VERSION ""

NS_ :

BS_:

BU_: Skylark_EV

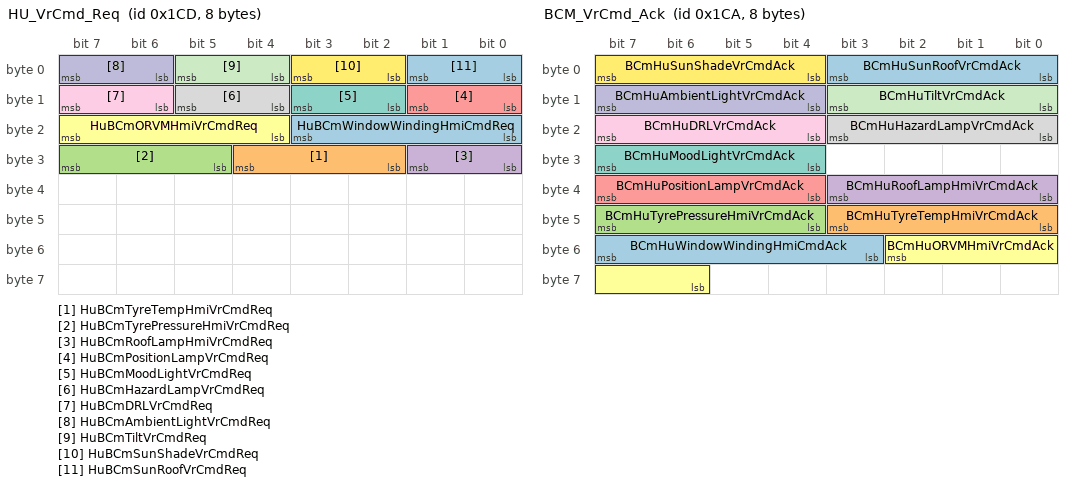
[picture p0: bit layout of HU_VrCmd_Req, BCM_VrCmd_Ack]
BO_ 461 HU_VrCmd_Req: 8 Skylark_EV
 SG_ HuBCmWindowWindingHmiCmdReq : 19|4@0+ (1,0) [0|15] "" Vector__XXX
 SG_ HuBCmTyreTempHmiVrCmdReq : 28|3@0+ (1,0) [0|7] "" Vector__XXX
 SG_ HuBCmTyrePressureHmiVrCmdReq : 31|3@0+ (1,0) [0|7] "" Vector__XXX
 SG_ HuBCmRoofLampHmiVrCmdReq : 25|2@0+ (1,0) [0|3] "" Vector__XXX
 SG_ HuBCmPositionLampVrCmdReq : 9|2@0+ (1,0) [0|3] "" Vector__XXX
 SG_ HuBCmORVMHmiVrCmdReq : 23|4@0+ (1,0) [0|15] "" Vector__XXX
 SG_ HuBCmMoodLightVrCmdReq : 11|2@0+ (1,0) [0|3] "" Vector__XXX
 SG_ HuBCmHazardLampVrCmdReq : 13|2@0+ (1,0) [0|3] "" Vector__XXX
 SG_ HuBCmDRLVrCmdReq : 15|2@0+ (1,0) [0|3] "" Vector__XXX
 SG_ HuBCmAmbientLightVrCmdReq : 7|2@0+ (1,0) [0|3] "" Vector__XXX
 SG_ HuBCmTiltVrCmdReq : 5|2@0+ (1,0) [0|3] "" Vector__XXX
 SG_ HuBCmSunShadeVrCmdReq : 3|2@0+ (1,0) [0|3] "" Vector__XXX
 SG_ HuBCmSunRoofVrCmdReq : 1|2@0+ (1,0) [0|3] "" Vector__XXX

BO_ 489 BCM_VrCmd_Support: 8 Vector__XXX
 SG_ BCmHuWindowWindingHmiCmdSupport : 23|1@0+ (1,0) [0|1] ""  Skylark_EV
 SG_ BCmHuTyreTempVrCmdSupport : 8|1@0+ (1,0) [0|1] ""  Skylark_EV
 SG_ BCmHuTyreTempHmiCmdSupport : 9|1@0+ (1,0) [0|1] ""  Skylark_EV
 SG_ BCmHuTyrePressureVrCmdSupport : 10|1@0+ (1,0) [0|1] ""  Skylark_EV
 SG_ BCmHuTyrePressureHmiCmdSupport : 11|1@0+ (1,0) [0|1] ""  Skylark_EV
 SG_ BCmHuSunroofTiltVrCmdSupport : 12|1@0+ (1,0) [0|1] ""  Skylark_EV
 SG_ BCmHuRoofLampVrCmdSupport : 13|1@0+ (1,0) [0|1] ""  Skylark_EV
 SG_ BCmHuRoofLampHmiCmdSupport : 14|1@0+ (1,0) [0|1] ""  Skylark_EV
 SG_ BCmHuPositionLampVrCmdSupport : 15|1@0+ (1,0) [0|1] ""  Skylark_EV
 SG_ BCmHuORVMVrCmdSupport : 2|1@0+ (1,0) [0|1] ""  Skylark_EV
 SG_ BCmHuORVMHmiCmdSupport : 3|1@0+ (1,0) [0|1] ""  Skylark_EV
 SG_ BCmHuMoodLightVrCmdSupport : 4|1@0+ (1,0) [0|1] ""  Skylark_EV
 SG_ BCmHuHazardLampVrCmdSupport : 5|1@0+ (1,0) [0|1] ""  Skylark_EV
 SG_ BCmHuDRLVrCmdSupport : 6|1@0+ (1,0) [0|1] ""  Skylark_EV
 SG_ BCmHuAmbientLightVrCmdSupport : 7|1@0+ (1,0) [0|1] ""  Skylark_EV
 SG_ BCmHuSunShadeVrCmdSupport : 1|1@0+ (1,0) [0|1] ""  Skylark_EV
 SG_ BCmHuSunRoofVrCmdSupport : 0|1@0+ (1,0) [0|1] ""  Skylark_EV

BO_ 458 BCM_VrCmd_Ack: 8 Vector__XXX
 SG_ BCmHuWindowWindingHmiCmdAck : 55|5@0+ (1,0) [0|31] ""  Skylark_EV
 SG_ BCmHuTyreTempHmiVrCmdAck : 43|4@0+ (1,0) [0|15] ""  Skylark_EV
 SG_ BCmHuTyrePressureHmiVrCmdAck : 47|4@0+ (1,0) [0|15] ""  Skylark_EV
 SG_ BCmHuRoofLampHmiVrCmdAck : 35|4@0+ (1,0) [0|15] ""  Skylark_EV
 SG_ BCmHuPositionLampVrCmdAck : 39|4@0+ (1,0) [0|15] ""  Skylark_EV
 SG_ BCmHuORVMHmiVrCmdAck : 50|5@0+ (1,0) [0|31] ""  Skylark_EV
 SG_ BCmHuMoodLightVrCmdAck : 31|4@0+ (1,0) [0|15] ""  Skylark_EV
 SG_ BCmHuHazardLampVrCmdAck : 19|4@0+ (1,0) [0|15] ""  Skylark_EV
 SG_ BCmHuDRLVrCmdAck : 23|4@0+ (1,0) [0|15] ""  Skylark_EV
 SG_ BCmHuAmbientLightVrCmdAck : 15|4@0+ (1,0) [0|15] ""  Skylark_EV
 SG_ BCmHuTiltVrCmdAck : 11|4@0+ (1,0) [0|15] ""  Skylark_EV
 SG_ BCmHuSunShadeVrCmdAck : 7|4@0+ (1,0) [0|15] ""  Skylark_EV
 SG_ BCmHuSunRoofVrCmdAck : 3|4@0+ (1,0) [0|15] ""  Skylark_EV

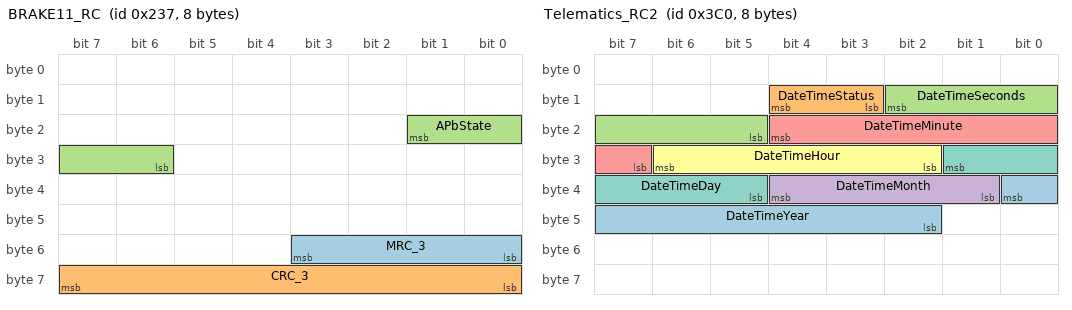
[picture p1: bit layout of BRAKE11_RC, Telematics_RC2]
BO_ 567 BRAKE11_RC: 8 Vector__XXX
 SG_ MRC_3 : 51|4@0+ (1,0) [0|15] ""  Skylark_EV
 SG_ CRC_3 : 63|8@0+ (1,0) [0|255] ""  Skylark_EV
 SG_ APbState : 17|4@0+ (1,0) [0|15] ""  Skylark_EV

BO_ 960 Telematics_RC2: 8 Skylark_EV
 SG_ DateTimeYear : 32|7@0+ (1,0) [0|99] "" Vector__XXX
 SG_ DateTimeStatus : 12|2@0+ (1,0) [0|3] "" Vector__XXX
 SG_ DateTimeSeconds : 10|6@0+ (1,0) [0|59] "" Vector__XXX
 SG_ DateTimeMonth : 36|4@0+ (1,0) [1|12] "" Vector__XXX
 SG_ DateTimeMinute : 20|6@0+ (1,0) [0|59] "" Vector__XXX
 SG_ DateTimeHour : 30|5@0+ (1,0) [0|23] "" Vector__XXX
 SG_ DateTimeDay : 25|5@0+ (1,0) [1|31] "" Vector__XXX

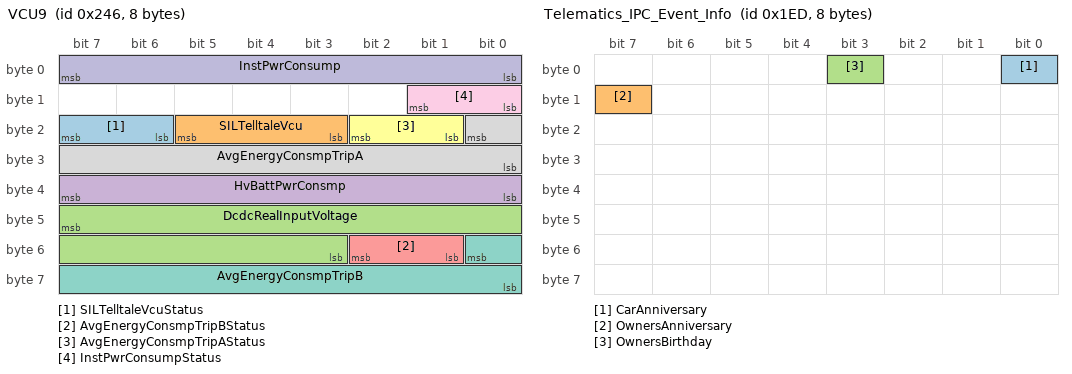
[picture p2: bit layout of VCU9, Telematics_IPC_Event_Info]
BO_ 582 VCU9: 8 Vector__XXX
 SG_ SILTelltaleVcuStatus : 23|2@0+ (1,0) [0|3] ""  Skylark_EV
 SG_ SILTelltaleVcu : 21|3@0+ (1,0) [0|7] ""  Skylark_EV
 SG_ DcdcRealInputVoltage : 47|13@0+ (0.1,0) [0|819.1] "V"  Skylark_EV
 SG_ HvBattPwrConsmp : 39|8@0+ (1,0) [0|250] "KwHr"  Skylark_EV
 SG_ AvgEnergyConsmpTripBStatus : 50|2@0+ (1,0) [0|3] ""  Skylark_EV
 SG_ AvgEnergyConsmpTripAStatus : 18|2@0+ (1,0) [0|3] ""  Skylark_EV
 SG_ AvgEnergyConsmpTripB : 48|9@0+ (1,0) [0|511] "kwH/Km"  Skylark_EV
 SG_ AvgEnergyConsmpTripA : 16|9@0+ (1,0) [0|511] "kwH/Km"  Skylark_EV
 SG_ InstPwrConsumpStatus : 9|2@0+ (1,0) [0|3] ""  Skylark_EV
 SG_ InstPwrConsump : 7|8@0+ (1,-100) [-100|100] "%"  Skylark_EV

BO_ 719 CCM_RC2: 8 Vector__XXX
 SG_ ComfortState : 0|1@0+ (1,0) [0|1] ""  Skylark_EV
 SG_ ComfortStateStatus : 2|2@0+ (1,0) [0|3] ""  Skylark_EV

BO_ 493 Telematics_IPC_Event_Info: 8 Skylark_EV
 SG_ CarAnniversary : 0|1@0+ (1,0) [0|1] "" Vector__XXX
 SG_ OwnersAnniversary : 15|1@0+ (1,0) [0|1] "" Vector__XXX
 SG_ OwnersBirthday : 3|1@0+ (1,0) [0|1] "" Vector__XXX

BO_ 581 VCU8_RC: 8 Vector__XXX
 SG_ HvChargeTypeStatus_VCAN : 37|2@0+ (1,0) [0|3] ""  Skylark_EV
 SG_ HvChargeType_VCAN : 35|2@0+ (1,0) [0|3] ""  Skylark_EV
 SG_ HvChargingStateStatus_VCAN : 33|2@0+ (1,0) [0|3] ""  Skylark_EV
 SG_ HvChargingState_VCAN : 26|3@0+ (1,0) [0|7] ""  Skylark_EV
 SG_ TimetoChargeHVMintsStatus_VCAN : 17|2@0+ (1,0) [0|3] ""  Skylark_EV
 SG_ TimetoChargeHVMints_VCAN : 23|6@0+ (1,0) [0|59] "Minutes"  Skylark_EV
 SG_ TimetoChargeHVHoursStatus_VCAN : 10|2@0+ (1,0) [0|3] ""  Skylark_EV
 SG_ TimetoChargeHVHours_VCAN : 15|5@0+ (1,0) [0|23] "Hours"  Skylark_EV
 SG_ CoolingPwrFdbkVal : 63|7@0+ (1,0) [0|100] "%"  Skylark_EV
 SG_ HeatingPwrFdbkVal : 55|7@0+ (1,0) [0|100] "%"  Skylark_EV
 SG_ CabinCoolingSolValveStateStatus : 29|2@0+ (1,0) [0|3] ""  Skylark_EV
 SG_ CabinCoolingSolValveState : 31|2@0+ (1,0) [0|3] ""  Skylark_EV
 SG_ LowHVBatteryChargeStatus_VCAN : 7|2@0+ (1,0) [0|3] ""  Skylark_EV
 SG_ LowHVBatteryCharge_VCAN : 5|2@0+ (1,0) [0|3] ""  Skylark_EV
 SG_ LowLVBatteryChargeStatus_VCAN : 3|2@0+ (1,0) [0|3] ""  Skylark_EV
 SG_ LowLVBatteryCharge_VCAN : 1|2@0+ (1,0) [0|3] ""  Skylark_EV
 SG_ HvAmpHrStatus : 39|2@0+ (1,0) [0|3] ""  Skylark_EV
 SG_ HvAmpHr : 47|8@0+ (0.5,0) [0|125] ""  Skylark_EV

BO_ 1330 CCM_Debug_Output2: 8 Vector__XXX
 SG_ SolarLoad : 7|8@0+ (5,0) [0|1200] "W/M^2"  Skylark_EV

BO_ 1329 CCM_Debug_Output1: 8 Vector__XXX
 SG_ SolarLoad : 63|8@0+ (5,0) [0|1200] "W/M^2"  Skylark_EV

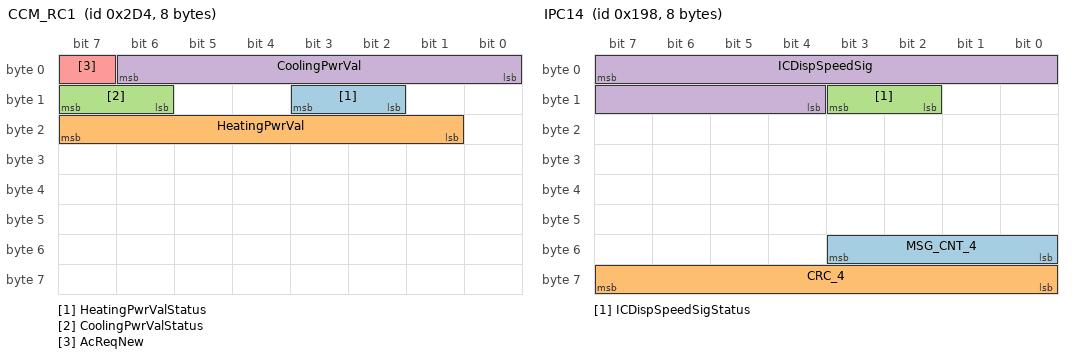
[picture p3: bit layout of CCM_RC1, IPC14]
BO_ 724 CCM_RC1: 8 Vector__XXX
 SG_ HeatingPwrValStatus : 11|2@0+ (1,0) [0|3] ""  Skylark_EV
 SG_ HeatingPwrVal : 23|7@0+ (1,0) [0|100] "%"  Skylark_EV
 SG_ CoolingPwrValStatus : 15|2@0+ (1,0) [0|3] ""  Skylark_EV
 SG_ CoolingPwrVal : 6|7@0+ (1,0) [0|100] "%"  Skylark_EV
 SG_ AcReqNew : 7|1@0+ (1,0) [0|1] ""  Skylark_EV

BO_ 408 IPC14: 8 Vector__XXX
 SG_ MSG_CNT_4 : 51|4@0+ (1,0) [0|15] ""  Skylark_EV
 SG_ CRC_4 : 63|8@0+ (1,0) [0|255] ""  Skylark_EV
 SG_ ICDispSpeedSigStatus : 11|2@0+ (1,0) [0|3] ""  Skylark_EV
 SG_ ICDispSpeedSig : 7|12@0+ (0.03125,0) [0|127.96875] "m/s"  Skylark_EV

BO_ 738 BCM_RC5: 8 Vector__XXX
 SG_ TurnInputSwStateInfoStatus : 62|2@0+ (1,0) [0|3] ""  Skylark_EV
 SG_ TurnInputSwStateInfo : 48|2@0+ (1,0) [0|3] ""  Skylark_EV
 SG_ RemoteUsecaseStateStatus : 51|2@0+ (1,0) [0|3] ""  Skylark_EV
 SG_ RemoteUsecaseState : 53|2@0+ (1,0) [0|3] ""  Skylark_EV
 SG_ HornStateStatus : 14|2@0+ (1,0) [0|3] ""  Skylark_EV
 SG_ HornState : 15|1@0+ (1,0) [0|1] ""  Skylark_EV
 SG_ ForcePanicStatus : 12|1@0+ (1,0) [0|1] ""  Skylark_EV
 SG_ ApprochLampStateStatus : 18|2@0+ (1,0) [0|3] ""  Skylark_EV
 SG_ ApprochLampState : 16|1@0+ (1,0) [0|1] ""  Skylark_EV
 SG_ LowBeamTellTaleStatus : 11|2@0+ (1,0) [0|3] ""  Skylark_EV
 SG_ LowBeamTellTale : 7|1@0+ (1,0) [0|1] ""  Skylark_EV
 SG_ IntrusionInfoStateStatus : 9|2@0+ (1,0) [0|3] ""  Skylark_EV
 SG_ IntrusionInfoState : 6|1@0+ (1,0) [0|1] ""  Skylark_EV
 SG_ HazardLampState : 3|1@0+ (1,0) [0|1] ""  Skylark_EV
 SG_ HazardLampStateStatus : 5|2@0+ (1,0) [0|3] ""  Skylark_EV
 SG_ VehicleSecured : 0|1@0+ (1,0) [0|1] ""  Skylark_EV
 SG_ VehicleSecuredStatus : 2|2@0+ (1,0) [0|3] ""  Skylark_EV

BO_ 495 TelematicsEventMsg_RC4: 8 Skylark_EV
 SG_ RemoteHornCmdStatus : 44|2@0+ (1,0) [0|3] "" Vector__XXX
 SG_ RemoteHornCmd : 45|1@0+ (1,0) [0|1] "" Vector__XXX
 SG_ RemoteApprochLmpCmdStatus : 41|2@0+ (1,0) [0|3] "" Vector__XXX
 SG_ RemoteApprochLmpCmd : 42|1@0+ (1,0) [0|1] "" Vector__XXX
 SG_ RemoteValetCmdStatus : 47|2@0+ (1,0) [0|3] "" Vector__XXX
 SG_ RemoteValetCmd : 33|1@0+ (1,0) [0|1] "" Vector__XXX
 SG_ RemoteAcTempSetStatus : 30|2@0+ (1,0) [0|3] "" Vector__XXX
 SG_ RemoteAcTempSet : 28|5@0+ (0.5,0) [0|31] "" Vector__XXX
 SG_ RemoteAcCmd : 31|1@0+ (1,0) [0|1] "" Vector__XXX
 SG_ RemoteAcCmdStatus : 39|2@0+ (1,0) [0|3] "" Vector__XXX
 SG_ RemoteImmoReqStatus : 37|2@0+ (1,0) [0|3] "" Vector__XXX
 SG_ RemoteImmoReq : 35|2@0+ (1,0) [0|3] "" Vector__XXX
 SG_ TowInfoStatus : 20|2@0+ (1,0) [0|3] "" Vector__XXX
 SG_ TowInfo : 21|1@0+ (1,0) [0|1] "" Vector__XXX
 SG_ ParkingCollisionInfoStatus : 23|2@0+ (1,0) [0|3] "" Vector__XXX
 SG_ ParkingCollisionInfo : 8|1@0+ (1,0) [0|1] "" Vector__XXX
 SG_ RemotePositionCmdStatus : 7|2@0+ (1,0) [0|3] "" Vector__XXX
 SG_ RemotePositionCmd : 15|1@0+ (1,0) [0|1] "" Vector__XXX
 SG_ RemoteHazardCmdStatus : 11|2@0+ (1,0) [0|3] "" Vector__XXX
 SG_ RemoteHazardCmd : 9|1@0+ (1,0) [0|1] "" Vector__XXX
 SG_ RemoteVehicleUnlockCmdStatus : 5|2@0+ (1,0) [0|3] "" Vector__XXX
 SG_ RemoteVehicleUnlockCmd : 3|1@0+ (1,0) [0|1] "" Vector__XXX
 SG_ RemoteVehicleLockCmdStatus : 2|2@0+ (1,0) [0|3] "" Vector__XXX
 SG_ RemoteVehicleLockCmd : 0|1@0+ (1,0) [0|1] "" Vector__XXX

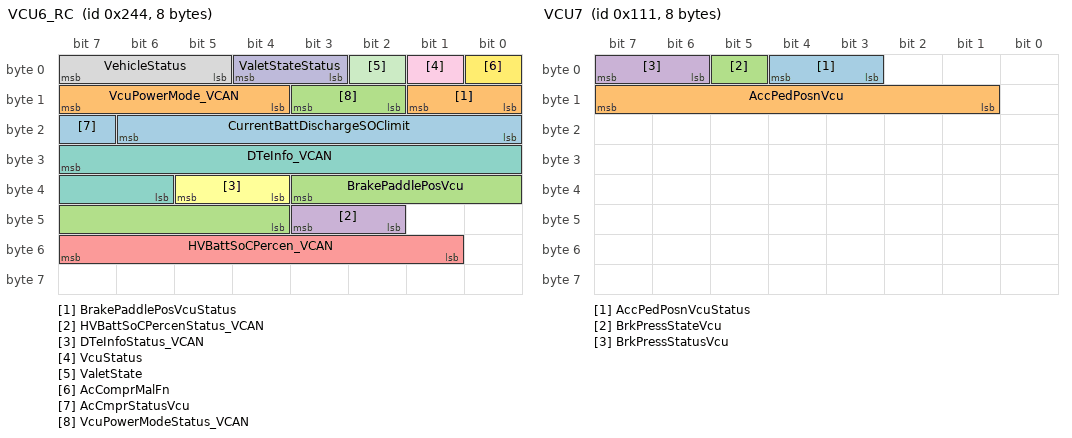
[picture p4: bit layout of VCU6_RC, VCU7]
BO_ 580 VCU6_RC: 8 Vector__XXX
 SG_ CurrentBattDischargeSOClimit : 22|7@0+ (1,0) [0|100] "%"  Skylark_EV
 SG_ BrakePaddlePosVcuStatus : 9|2@0+ (1,0) [0|3] ""  Skylark_EV
 SG_ BrakePaddlePosVcu : 35|8@0+ (0.5,0) [0|100] "%"  Skylark_EV
 SG_ HVBattSoCPercenStatus_VCAN : 43|2@0+ (1,0) [0|3] ""  Skylark_EV
 SG_ HVBattSoCPercen_VCAN : 55|7@0+ (1,0) [0|100] "%"  Skylark_EV
 SG_ DTeInfoStatus_VCAN : 37|2@0+ (1,0) [0|3] ""  Skylark_EV
 SG_ DTeInfo_VCAN : 31|10@0+ (1,0) [0|999] ""  Skylark_EV
 SG_ VehicleStatus : 7|3@0+ (1,0) [0|7] ""  Skylark_EV
 SG_ VcuStatus : 1|1@0+ (1,0) [0|1] ""  Skylark_EV
 SG_ ValetStateStatus : 4|2@0+ (1,0) [0|3] ""  Skylark_EV
 SG_ ValetState : 2|1@0+ (1,0) [0|1] ""  Skylark_EV
 SG_ AcComprMalFn : 0|1@0+ (1,0) [0|1] ""  Skylark_EV
 SG_ AcCmprStatusVcu : 23|1@0+ (1,0) [0|1] ""  Skylark_EV
 SG_ VcuPowerMode_VCAN : 15|4@0+ (1,0) [0|15] ""  Skylark_EV
 SG_ VcuPowerModeStatus_VCAN : 11|2@0+ (1,0) [0|3] ""  Skylark_EV

BO_ 579 VCU5: 8 Vector__XXX
 SG_ VcuHazardLampReqStatus : 50|2@0+ (1,0) [0|3] ""  Skylark_EV
 SG_ VcuHazardLampReq : 51|1@0+ (1,0) [0|1] ""  Skylark_EV
 SG_ VCuPresence : 0|1@0+ (1,0) [0|1] ""  Skylark_EV
 SG_ BrkVacPumpStatus : 40|1@0+ (1,0) [0|1] ""  Skylark_EV
 SG_ DriveMotorStatus : 53|1@0+ (1,0) [0|1] ""  Skylark_EV
 SG_ HvBattSoh : 52|1@0+ (1,0) [0|1] ""  Skylark_EV
 SG_ RegenAmpHr : 29|8@0+ (0.5,0) [0|125] ""  Skylark_EV
 SG_ HvBattPackVolStatus : 55|2@0+ (1,0) [0|3] ""  Skylark_EV
 SG_ HvBattPackVol : 37|13@0+ (0.1,0) [0|500] ""  Skylark_EV
 SG_ AvgEnergyConsmption : 48|9@0+ (1,0) [0|511] "kwH/Km"  Skylark_EV
 SG_ AvgEnergyConsmptionStatus : 17|2@0+ (1,0) [0|3] ""  Skylark_EV
 SG_ MotorHightempStatus : 19|2@0+ (1,0) [0|3] ""  Skylark_EV
 SG_ MotorHightemp : 31|2@0+ (1,0) [0|3] ""  Skylark_EV
 SG_ VcuGearSelectionChangeTxt : 21|2@0+ (1,0) [0|3] ""  Skylark_EV
 SG_ ImmoStatusVcu : 8|1@0+ (1,0) [0|1] ""  Skylark_EV
 SG_ ClntTempVcuStatus : 23|2@0+ (1,0) [0|3] ""  Skylark_EV
 SG_ ClntTempVcu : 15|7@0+ (1,-10) [-10|80] "deg"  Skylark_EV
 SG_ GearForDisplayVcu : 7|4@0+ (1,0) [0|15] ""  Skylark_EV
 SG_ GearForDisplayVcuStatus : 3|2@0+ (1,0) [0|3] ""  Skylark_EV

BO_ 273 VCU7: 8 Vector__XXX
 SG_ AccPedPosnVcuStatus : 4|2@0+ (1,0) [0|3] ""  Skylark_EV
 SG_ AccPedPosnVcu : 15|7@0+ (1,0) [0|100] "%"  Skylark_EV
 SG_ BrkPressStateVcu : 5|1@0+ (1,0) [0|1] ""  Skylark_EV
 SG_ BrkPressStatusVcu : 7|2@0+ (1,0) [0|3] ""  Skylark_EV

BO_ 192 SAS1: 5 Vector__XXX
 SG_ LWS_ANGLE : 0|16@1- (0.1,0) [-780|779.9] "degree"  Skylark_EV

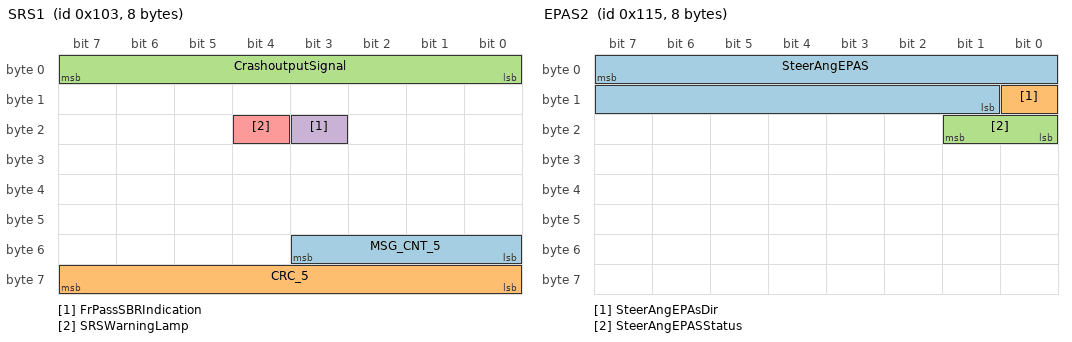
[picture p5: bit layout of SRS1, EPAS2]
BO_ 259 SRS1: 8 Vector__XXX
 SG_ MSG_CNT_5 : 51|4@0+ (1,0) [0|15] ""  Skylark_EV
 SG_ CRC_5 : 63|8@0+ (1,0) [0|255] ""  Skylark_EV
 SG_ CrashoutputSignal : 7|8@0+ (1,0) [0|255] ""  Skylark_EV
 SG_ FrPassSBRIndication : 19|1@0+ (1,0) [0|1] ""  Skylark_EV
 SG_ SRSWarningLamp : 20|1@0+ (1,0) [0|1] ""  Skylark_EV

BO_ 277 EPAS2: 8 Vector__XXX
 SG_ SteerAngEPAS : 7|15@0+ (0.04375,0) [0|1433.55625] " deg"  Skylark_EV
 SG_ SteerAngEPAsDir : 8|1@0+ (1,0) [0|1] ""  Skylark_EV
 SG_ SteerAngEPASStatus : 17|2@0+ (1,0) [0|3] ""  Skylark_EV

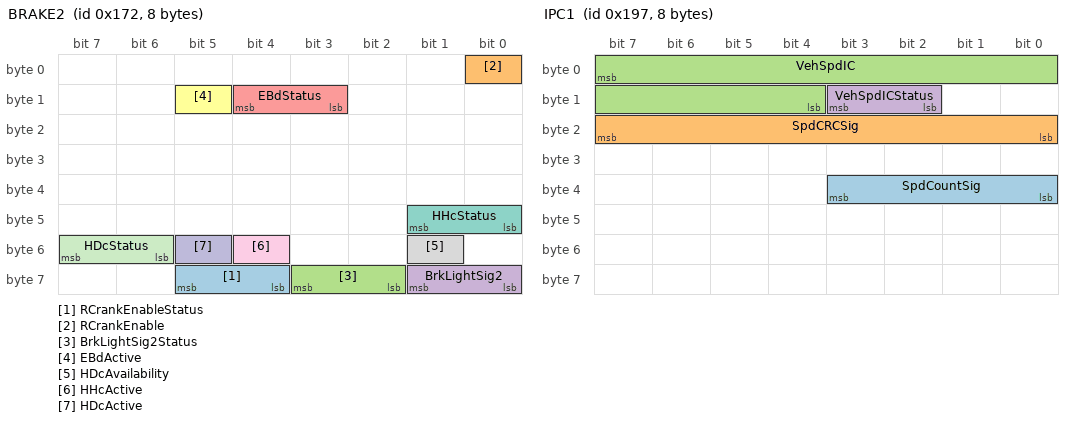
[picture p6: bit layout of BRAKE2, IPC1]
BO_ 370 BRAKE2: 8 Vector__XXX
 SG_ RCrankEnableStatus : 61|2@0+ (1,0) [0|3] ""  Skylark_EV
 SG_ RCrankEnable : 0|1@0+ (1,0) [0|1] ""  Skylark_EV
 SG_ BrkLightSig2Status : 59|2@0+ (1,0) [0|3] ""  Skylark_EV
 SG_ BrkLightSig2 : 57|2@0+ (1,0) [0|3] ""  Skylark_EV
 SG_ EBdStatus : 12|2@0+ (1,0) [0|3] ""  Skylark_EV
 SG_ EBdActive : 13|1@0+ (1,0) [0|1] ""  Skylark_EV
 SG_ HHcStatus : 41|2@0+ (1,0) [0|3] ""  Skylark_EV
 SG_ HDcAvailability : 49|1@0+ (1,0) [0|1] ""  Skylark_EV
 SG_ HHcActive : 52|1@0+ (1,0) [0|1] ""  Skylark_EV
 SG_ HDcActive : 53|1@0+ (1,0) [0|1] ""  Skylark_EV
 SG_ HDcStatus : 55|2@0+ (1,0) [0|3] ""  Skylark_EV

BO_ 374 BRAKE5: 8 Vector__XXX
 SG_ DrvModeIndctnESP2Status : 28|2@0+ (1,0) [0|3] ""  Skylark_EV
 SG_ DrvModeIndctnESP2 : 31|3@0+ (1,0) [0|7] ""  Skylark_EV

BO_ 376 BRAKE9: 8 Vector__XXX
 SG_ AX1 : 7|16@0+ (0.0001,-3.2768) [-3.2768|3.2767] "g"  Skylark_EV
 SG_ AY1 : 23|16@0+ (0.0001,-3.2768) [-3.2768|3.2767] "g"  Skylark_EV

BO_ 407 IPC1: 8 Vector__XXX
 SG_ SpdCountSig : 35|4@0+ (1,0) [0|15] ""  Skylark_EV
 SG_ SpdCRCSig : 23|8@0+ (1,0) [0|255] ""  Skylark_EV
 SG_ VehSpdIC : 7|12@0+ (0.03125,0) [0|127.96875] "m/s"  Skylark_EV
 SG_ VehSpdICStatus : 11|2@0+ (1,0) [0|3] ""  Skylark_EV

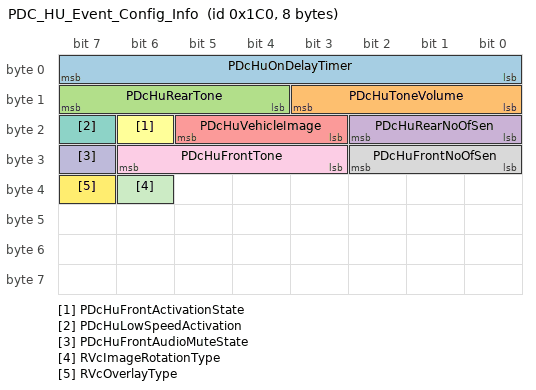
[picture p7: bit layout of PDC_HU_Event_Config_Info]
BO_ 448 PDC_HU_Event_Config_Info: 8 Vector__XXX
 SG_ PDcHuOnDelayTimer : 7|8@0+ (1,0) [0|255] "sec"  Skylark_EV
 SG_ PDcHuToneVolume : 11|4@0+ (1,0) [0|15] ""  Skylark_EV
 SG_ PDcHuRearTone : 15|4@0+ (1,0) [0|15] ""  Skylark_EV
 SG_ PDcHuRearNoOfSen : 18|3@0+ (1,0) [0|7] ""  Skylark_EV
 SG_ PDcHuVehicleImage : 21|3@0+ (1,0) [0|7] ""  Skylark_EV
 SG_ PDcHuFrontActivationState : 22|1@0+ (1,0) [0|1] ""  Skylark_EV
 SG_ PDcHuLowSpeedActivation : 23|1@0+ (1,0) [0|1] ""  Skylark_EV
 SG_ PDcHuFrontNoOfSen : 26|3@0+ (1,0) [0|7] ""  Skylark_EV
 SG_ PDcHuFrontTone : 30|4@0+ (1,0) [0|15] ""  Skylark_EV
 SG_ PDcHuFrontAudioMuteState : 31|1@0+ (1,0) [0|1] ""  Skylark_EV
 SG_ RVcImageRotationType : 38|1@0+ (1,0) [0|1] ""  Skylark_EV
 SG_ RVcOverlayType : 39|1@0+ (1,0) [0|1] ""  Skylark_EV

BO_ 451 IPC_VCIM_Event_OdoFullRange_RC: 8 Vector__XXX
 SG_ OdoICFullSig : 7|32@0+ (1,0) [0|999999000] "m"  Skylark_EV

CM_ SG_ 461 HuBCmWindowWindingHmiCmdReq "Window Winding voice command request from HU to BCM";
CM_ SG_ 461 HuBCmTyreTempHmiVrCmdReq "Tyre Temperature HMI or voice command request from HU to BCM";
CM_ SG_ 461 HuBCmTyrePressureHmiVrCmdReq "Tyre Pressure HMI or voice command request from HU to BCM";
CM_ SG_ 461 HuBCmRoofLampHmiVrCmdReq "Roof lamp HMI or Voice command request from HU to BCM";
CM_ SG_ 461 HuBCmPositionLampVrCmdReq "Position lamp voice command request from HU to BCM";
CM_ SG_ 461 HuBCmORVMHmiVrCmdReq "ORVM HMI or Voice command request from HU to BCM";
CM_ SG_ 461 HuBCmMoodLightVrCmdReq "Mood light voice command request from HU to BCM";
CM_ SG_ 461 HuBCmHazardLampVrCmdReq "Hazard lamp voice command request from HU to BCM";
CM_ SG_ 461 HuBCmDRLVrCmdReq "DRL voice command request from HU to BCM";
CM_ SG_ 461 HuBCmAmbientLightVrCmdReq "Ambient light voice command request from HU to BCM";
CM_ SG_ 461 HuBCmTiltVrCmdReq "Sunroof Tilt voice command command request from HU to BCM";
CM_ SG_ 461 HuBCmSunShadeVrCmdReq "Sunshade voice command request from HU to BCM";
CM_ SG_ 461 HuBCmSunRoofVrCmdReq "Sunroof voice command command request from HU to BCM";
CM_ SG_ 489 BCmHuWindowWindingHmiCmdSupport "Window Winding HMI support from BCM to HU";
CM_ SG_ 489 BCmHuTyreTempVrCmdSupport "Tyre Temparature Voice support from BCM to HU";
CM_ SG_ 489 BCmHuTyreTempHmiCmdSupport "Tyre Temparature HMI support from BCM to HU";
CM_ SG_ 489 BCmHuTyrePressureVrCmdSupport "Tyre Pressure Voice support from BCM to HU";
CM_ SG_ 489 BCmHuTyrePressureHmiCmdSupport "Tyre Pressure HMI support from BCM to HU";
CM_ SG_ 489 BCmHuSunroofTiltVrCmdSupport "Sunroof Tilt voice support from BCM to HU";
CM_ SG_ 489 BCmHuRoofLampVrCmdSupport "Roof Lamp Voice support from BCM to HU";
CM_ SG_ 489 BCmHuRoofLampHmiCmdSupport "Roof Lamp HMI support from BCM to HU";
CM_ SG_ 489 BCmHuPositionLampVrCmdSupport "Position lamp voice support from BCM to HU";
CM_ SG_ 489 BCmHuORVMVrCmdSupport "ORVM Voice support from BCM to HU";
CM_ SG_ 489 BCmHuORVMHmiCmdSupport "ORVM HMI support from BCM to HU";
CM_ SG_ 489 BCmHuMoodLightVrCmdSupport "Mood Light voice support from BCM to HU";
CM_ SG_ 489 BCmHuHazardLampVrCmdSupport "Hazard Lamp voice support from BCM to HU";
CM_ SG_ 489 BCmHuDRLVrCmdSupport "DRL voice support from BCM to HU";
CM_ SG_ 489 BCmHuAmbientLightVrCmdSupport "Ambient Light voice support from BCM to HU";
CM_ SG_ 489 BCmHuSunShadeVrCmdSupport "Sunshade operation support from BCM to HU";
CM_ SG_ 489 BCmHuSunRoofVrCmdSupport "Sunroof operation support from BCM to HU";
CM_ SG_ 458 BCmHuWindowWindingHmiCmdAck "Window Winding state from BCM to HU















";
CM_ SG_ 458 BCmHuTyreTempHmiVrCmdAck "Tyre Temperature state from BCM to HU














";
CM_ SG_ 458 BCmHuTyrePressureHmiVrCmdAck "Tyre Pressure state from BCM to HU















";
CM_ SG_ 458 BCmHuRoofLampHmiVrCmdAck "Roof lamp state from BCM to HU

















";
CM_ SG_ 458 BCmHuPositionLampVrCmdAck "Position lamp state from BCM to HU";
CM_ SG_ 458 BCmHuORVMHmiVrCmdAck "ORVM state from BCM to HU
















";
CM_ SG_ 458 BCmHuMoodLightVrCmdAck "Mood Light state from BCM to HU";
CM_ SG_ 458 BCmHuHazardLampVrCmdAck "Hazard lamp state from BCM to HU";
CM_ SG_ 458 BCmHuDRLVrCmdAck "DRL state from BCM to HU";
CM_ SG_ 458 BCmHuAmbientLightVrCmdAck "Ambient Light state from BCM to HU";
CM_ SG_ 458 BCmHuTiltVrCmdAck "Sunroof Tilt state from BCM to HU";
CM_ SG_ 458 BCmHuSunShadeVrCmdAck "Sunshade state from BCM to HU";
CM_ SG_ 458 BCmHuSunRoofVrCmdAck "Sunroof state from BCM to HU";
CM_ SG_ 567 MRC_3 "Messgage counter for APbState signals";
CM_ SG_ 567 CRC_3 "CRC signal for APbState";
CM_ SG_ 567 APbState "status of APB system";
CM_ SG_ 960 DateTimeYear "Year Information";
CM_ SG_ 960 DateTimeStatus "Date Time Status Information";
CM_ SG_ 960 DateTimeSeconds "Seconds Information";
CM_ SG_ 960 DateTimeMonth "Month Information";
CM_ SG_ 960 DateTimeMinute "Minute Information";
CM_ SG_ 960 DateTimeHour "Hour Information";
CM_ SG_ 960 DateTimeDay "Day Information";
CM_ SG_ 582 SILTelltaleVcuStatus "status of Service Indicator Lamp telltale from VCU";
CM_ SG_ 582 SILTelltaleVcu "Service Indicator Lamp telltale from VCU";
CM_ SG_ 582 DcdcRealInputVoltage "DCDC_VCU_38E( signal name at PT side)
Voltage after the HV Battery Contactor";
CM_ SG_ 582 HvBattPwrConsmp "HV Battery Power Consumption";
CM_ SG_ 582 AvgEnergyConsmpTripBStatus "Average Energy Consumption for Trip B Status";
CM_ SG_ 582 AvgEnergyConsmpTripAStatus "Average Energy Consumption for Trip A Status";
CM_ SG_ 582 AvgEnergyConsmpTripB "Average Energy Consumption for Trip B";
CM_ SG_ 582 AvgEnergyConsmpTripA "Average Energy Consumption for Trip A";
CM_ SG_ 582 InstPwrConsumpStatus "Instantaneous Power Consumption Status";
CM_ SG_ 582 InstPwrConsump "Instantaneous Power Consumption";
CM_ SG_ 719 ComfortState "Set temperature reached information as published by FATC to Tcu";
CM_ SG_ 719 ComfortStateStatus "Status signal of Set temperature reached information as published by FATC to Tcu";
CM_ SG_ 493 CarAnniversary "Car Anniversary";
CM_ SG_ 493 OwnersAnniversary "Owenrs Marriage Anniversary";
CM_ SG_ 493 OwnersBirthday "It’s the car Owners Birthday";
CM_ SG_ 581 HvChargeTypeStatus_VCAN "HV Battery Charging Type Status";
CM_ SG_ 581 HvChargeType_VCAN "HV Battery Charging Type";
CM_ SG_ 581 HvChargingStateStatus_VCAN "HV Battery Charging Status";
CM_ SG_ 581 HvChargingState_VCAN "HV Battery Charging State";
CM_ SG_ 581 TimetoChargeHVMintsStatus_VCAN "Time to charge HV Battery Minutes Status";
CM_ SG_ 581 TimetoChargeHVMints_VCAN "Time to charge HV Battery Minutes";
CM_ SG_ 581 TimetoChargeHVHoursStatus_VCAN "Time to charge HV Battery Hours Status";
CM_ SG_ 581 TimetoChargeHVHours_VCAN "Time to charge HV Battery Hours";
CM_ SG_ 581 CoolingPwrFdbkVal "This signal is used to indicate the actual value of Cooling Power honored by VCU.";
CM_ SG_ 581 HeatingPwrFdbkVal "This signal is used to indicate the actual value of Heating Power honored by VCU.
";
CM_ SG_ 581 CabinCoolingSolValveStateStatus "Cabin Cooling Solenoid Valve Signal Status";
CM_ SG_ 581 CabinCoolingSolValveState "Cabin Cooling Solenoid Valve Signal";
CM_ SG_ 581 LowHVBatteryChargeStatus_VCAN "Low HV Battery Charge Status";
CM_ SG_ 581 LowHVBatteryCharge_VCAN "Low HV Battery Charge";
CM_ SG_ 581 LowLVBatteryChargeStatus_VCAN "Low LV Battery Charge Status";
CM_ SG_ 581 LowLVBatteryCharge_VCAN "Low LV Battery Charge";
CM_ SG_ 581 HvAmpHrStatus "HV Battery Charge Status";
CM_ SG_ 581 HvAmpHr "HV Battery Charge";
CM_ SG_ 1330 SolarLoad "This signal is used to provide the current value of  Solar Load";
CM_ SG_ 1329 SolarLoad "This signal is used to provide the current value of  Solar Load";
CM_ SG_ 724 HeatingPwrValStatus "Indicate the status of heating power required for cabin heating ";
CM_ SG_ 724 HeatingPwrVal "This signal is used to control the PTC Heater for cabin heating";
CM_ SG_ 724 CoolingPwrValStatus "Indicate the status of cooling power required for cabin Cooling ";
CM_ SG_ 724 CoolingPwrVal "This signal is used to control the Compressor rpm for cabin Cooling";
CM_ SG_ 724 AcReqNew "VCU to recive the signal from FATC to know the AC request by driver";
CM_ SG_ 408 MSG_CNT_4 "rolling counter for message 0x198";
CM_ SG_ 408 CRC_4 "Signal represents CRC of the message.";
CM_ SG_ 408 ICDispSpeedSigStatus "Signal represents Status of Display Vehicle Speed Signal";
CM_ SG_ 408 ICDispSpeedSig "Signal represents Display Vehicle Speed evaluated by Instrument Cluster
";
CM_ SG_ 738 TurnInputSwStateInfoStatus "BCM shall publish turn indicator input switch state  Status information on CAN";
CM_ SG_ 738 TurnInputSwStateInfo "BCM shall publish turn indictor input switch state information on CAN";
CM_ SG_ 738 RemoteUsecaseStateStatus "This signal gives status of RemoteUsecaseState signal.";
CM_ SG_ 738 RemoteUsecaseState "This signal is transmitted from BCM to TCM, PEPS, EMS, IPC & HU for informing ECUs about start working as normal Drive mode and ignore Remote Command recondition checks.";
CM_ SG_ 738 HornStateStatus "HornStateStatus Signal information";
CM_ SG_ 738 HornState "Horn Status Information ";
CM_ SG_ 738 ForcePanicStatus "Force Panic Request signal";
CM_ SG_ 738 ApprochLampStateStatus "Status signal for ApprochLamp status from BCM";
CM_ SG_ 738 ApprochLampState "ApprochLampstatus from BCM";
CM_ SG_ 738 LowBeamTellTaleStatus "Status of the Low Beam Telltale";
CM_ SG_ 738 LowBeamTellTale "IC to display the low beam tell-tale when the low beam lamp is active";
CM_ SG_ 738 IntrusionInfoStateStatus "Status of Perimetric alarm state from BCM";
CM_ SG_ 738 IntrusionInfoState "Perimetric alarm state from BCM";
CM_ SG_ 738 HazardLampState "Hazard lamp status from BCM";
CM_ SG_ 738 HazardLampStateStatus "Status of signal HazardLampState";
CM_ SG_ 738 VehicleSecured "Vehicle secured information";
CM_ SG_ 738 VehicleSecuredStatus "Status of Vehicle secured information";
CM_ SG_ 495 RemoteHornCmdStatus "Status of the HornStateCmd signal published by TCU";
CM_ SG_ 495 RemoteHornCmd "Horn State on/off request from TCU";
CM_ SG_ 495 RemoteApprochLmpCmdStatus "Status of the RemoteApprochCmd signal published by TCU";
CM_ SG_ 495 RemoteApprochLmpCmd "Approch lamp on/off request from TCU";
CM_ SG_ 495 RemoteValetCmdStatus "Status of the Valetcmd Status published by TCU";
CM_ SG_ 495 RemoteValetCmd "Command published by TCU to request FATC";
CM_ SG_ 495 RemoteAcTempSetStatus "Status of the TCuAcTemperatureSet singnal as published by TCU.";
CM_ SG_ 495 RemoteAcTempSet "Set temperature value from TCU to FATC for in-cabin climate control.";
CM_ SG_ 495 RemoteAcCmd "Command published by TCU to request FATC to turn On/Off the AC.";
CM_ SG_ 495 RemoteAcCmdStatus "Status of the TCuAcCmd signal published by TCU";
CM_ SG_ 495 RemoteImmoReqStatus "Status signal for Immobilize request from TCU to VCU";
CM_ SG_ 495 RemoteImmoReq "Immobilize request from TCU to VCU";
CM_ SG_ 495 TowInfoStatus "status signal for TCU sends the Tow away detection to BCM";
CM_ SG_ 495 TowInfo "TCU sends the Tow away detection to BCM ";
CM_ SG_ 495 ParkingCollisionInfoStatus "status signal for TCU sends the Park collision detection to BCM";
CM_ SG_ 495 ParkingCollisionInfo "TCU sends the Park collision detection to BCM ";
CM_ SG_ 495 RemotePositionCmdStatus "Status of the RemotePositionCmd signal published by BCM";
CM_ SG_ 495 RemotePositionCmd "Position lamp on/off request from TCU";
CM_ SG_ 495 RemoteHazardCmdStatus "Status of the RemoteHazardCmd signal published by TCU";
CM_ SG_ 495 RemoteHazardCmd "Hazard lamp on/off request from TCU";
CM_ SG_ 495 RemoteVehicleUnlockCmdStatus "Staus of signal for Command published by TCU to request BCM to unlock the vehicle";
CM_ SG_ 495 RemoteVehicleUnlockCmd "Command published by TCU to request BCM to unlock the vehicle";
CM_ SG_ 495 RemoteVehicleLockCmdStatus "Staus of signal for Command published by TCU to request BCM to lock the vehicle";
CM_ SG_ 495 RemoteVehicleLockCmd "Command published by TCU to request BCM to lock the vehicle";
CM_ SG_ 580 CurrentBattDischargeSOClimit "Indicates the requested discharge limit by user ";
CM_ SG_ 580 BrakePaddlePosVcuStatus "Brake paddle travel percentage status information shall be Transmissted  by VCU to Telematics ";
CM_ SG_ 580 BrakePaddlePosVcu "Brake paddle travel percentage shall be Transmissted  by VCU to Telematics ";
CM_ SG_ 580 HVBattSoCPercenStatus_VCAN "HV Battery SoC Percentage Status";
CM_ SG_ 580 HVBattSoCPercen_VCAN "HV Battery SoC Percentage";
CM_ SG_ 580 DTeInfoStatus_VCAN "Distance to Empty Information Status";
CM_ SG_ 580 DTeInfo_VCAN "Distance to Empty Information";
CM_ SG_ 580 VehicleStatus "Vehicle status display messages";
CM_ SG_ 580 VcuStatus "This function displays status of the VCU Malfunctioning
";
CM_ SG_ 580 ValetStateStatus "ValetStateStatus signlal published by VCU";
CM_ SG_ 580 ValetState "ValetState as Published by VCU";
CM_ SG_ 580 AcComprMalFn "This function displays status of the AC Compressor Malfunctioning";
CM_ SG_ 580 AcCmprStatusVcu "This signal is used to cycle the compressor and diagnostic";
CM_ SG_ 580 VcuPowerMode_VCAN "Indicates the VCU power mode";
CM_ SG_ 580 VcuPowerModeStatus_VCAN "This information is used to determine the plausibility status for VCU power mode message";
CM_ SG_ 579 VcuHazardLampReqStatus "Hazard lamp operation status from VCU to BCM";
CM_ SG_ 579 VcuHazardLampReq "Hazard lamp operation request from VCU to BCM";
CM_ SG_ 579 VCuPresence "ECU presence signal to the partner ECU";
CM_ SG_ 579 BrkVacPumpStatus "This function displays status of the Brake Vaccum Pump Malfunctioning";
CM_ SG_ 579 DriveMotorStatus "This function displays status of the Drive Motor Malfunctioning";
CM_ SG_ 579 HvBattSoh "HV Battery State of Health";
CM_ SG_ 579 RegenAmpHr "Regeneration Battery Charge";
CM_ SG_ 579 HvBattPackVolStatus "HV Battery Pack Voltage Status";
CM_ SG_ 579 HvBattPackVol "HV Battery Pack Voltage";
CM_ SG_ 579 AvgEnergyConsmption "Average Energy Consumption";
CM_ SG_ 579 AvgEnergyConsmptionStatus "Average Energy Consumption Status";
CM_ SG_ 579 MotorHightempStatus "This information is used to determine the Motor High Temp Status";
CM_ SG_ 579 MotorHightemp "This feature provides the traction motor High Temperature Status to the user.";
CM_ SG_ 579 VcuGearSelectionChangeTxt "Indicate the VCU Gear Selection Message";
CM_ SG_ 579 ImmoStatusVcu "This gives status of VCU whether mobilized or immobilized.";
CM_ SG_ 579 ClntTempVcuStatus "This information is used to determine the  Battery coolant temperature signal status. 
";
CM_ SG_ 579 ClntTempVcu "This information is used   to display or indicate the coolant temperature 
";
CM_ SG_ 579 GearForDisplayVcu "Gear For Display";
CM_ SG_ 579 GearForDisplayVcuStatus "Gear For Display Status";
CM_ SG_ 273 AccPedPosnVcuStatus "This information is used to determine the accelerator pedal position signal status";
CM_ SG_ 273 AccPedPosnVcu "This information is used to determine the accelerator pedal position";
CM_ SG_ 273 BrkPressStateVcu "This inofmation tells whether brake is pressed  or not ";
CM_ SG_ 273 BrkPressStatusVcu "This information is used to determine the  Brake press status signal status. ";
CM_ SG_ 192 LWS_ANGLE "Current steering wheel angle
";
CM_ SG_ 259 MSG_CNT_5 "MRC for CrashOutputSignals";
CM_ SG_ 259 CRC_5 "CRC for CrashOutput signals";
CM_ SG_ 259 CrashoutputSignal "CrashOutput signal is periodic in the event of no Crash. In the event of crash, the signal is send as an event signal.";
CM_ SG_ 259 FrPassSBRIndication "Visual indication request signal to SBR display for passenger.";
CM_ SG_ 259 SRSWarningLamp "AWL Warning Lamp signal Request to IC";
CM_ BO_ 277 "Frame to be enabled through DID for X0,X1 ";
CM_ SG_ 277 SteerAngEPAS "Steering Angle information can be used only for comfort function";
CM_ SG_ 277 SteerAngEPAsDir "Steering wheel angle direction";
CM_ SG_ 277 SteerAngEPASStatus "Steering Angle information can be used only for comfort function,Status info";
CM_ SG_ 370 RCrankEnableStatus "Status information of Remote Crank Signal";
CM_ SG_ 370 RCrankEnable "Remote crank  signal to  EMS.";
CM_ SG_ 370 BrkLightSig2Status "status information of BrkLightSig";
CM_ SG_ 370 BrkLightSig2 "Brake Light status signal is given by ABS / Esp to BCM for redundaent purpose";
CM_ SG_ 370 EBdStatus "status information of EBD
";
CM_ SG_ 370 EBdActive "Indication that ABS / ESP system currently performs EBD intervention
";
CM_ SG_ 370 HHcStatus "status information of HHc. It is 'Package Protected' signal.
";
CM_ SG_ 370 HDcAvailability "Indication that HDC system is available or not";
CM_ SG_ 370 HHcActive "Indication that ESP system currently performs HHC intervention. It is 'Package Protected' signal.
";
CM_ SG_ 370 HDcActive "Indication that ESP system currently performs HDC intervention. It is 'Package Protected' signal.
";
CM_ SG_ 370 HDcStatus "status information of HDc. It is 'Package Protected' signal.
";
CM_ SG_ 374 DrvModeIndctnESP2Status "Status of the Drive mode indication ESP signal. It is 'Package Protected' signal.";
CM_ SG_ 374 DrvModeIndctnESP2 "Information is sent from ESP to EMS,BCM,IPC and HU indicating that it has switched to the corresponding mode.";
CM_ SG_ 376 AX1 "Longitudinal accelaration information";
CM_ SG_ 376 AY1 "Lateral accelaration information";
CM_ SG_ 407 SpdCountSig "Signal represents Message counter to indicate message has not freezed.";
CM_ SG_ 407 SpdCRCSig "Signal represents CRC of the message.";
CM_ SG_ 407 VehSpdIC "Signal represents Vehicle Speed evaluated by Instrument Cluster.";
CM_ SG_ 407 VehSpdICStatus "Signal represents Status of Vehicle Speed Signal";
CM_ SG_ 448 PDcHuOnDelayTimer "On evey ignition ON, delay timer info is send as an input to HU .
";
CM_ SG_ 448 PDcHuToneVolume "On evey ignition ON, tone volume info for rear PDC  is send as an input to HU";
CM_ SG_ 448 PDcHuRearTone "This signal is used as an input to the HU for any change in the rear tone setting done by the user.";
CM_ SG_ 448 PDcHuRearNoOfSen "On every IGN ON, PDC shall publish its rear number of sensor status to HU.";
CM_ SG_ 448 PDcHuVehicleImage "On every IGN ON, PDC shall publish vehicle images to HU.";
CM_ SG_ 448 PDcHuFrontActivationState "This signal is used an input from BCM to HU to know Front PDC function is Active/Deactive state .";
CM_ SG_ 448 PDcHuLowSpeedActivation "This signal is used as an input from BCM to HU to know front PDC function for Low speed activation is active/deactive";
CM_ SG_ 448 PDcHuFrontNoOfSen "On every IGN ON, BCM shall publish its Front number of sensor status to HU.";
CM_ SG_ 448 PDcHuFrontTone "This signal is used as an input to the HU for any change in the Front tone setting done by the user.";
CM_ SG_ 448 PDcHuFrontAudioMuteState "On every IGN ON, BCM shall publish its rear number of sensor status to HU.";
CM_ SG_ 448 RVcImageRotationType "This signal is used as an input from BCM to HU to know the image rotation type";
CM_ SG_ 448 RVcOverlayType "This signal is used as an input from BCM to HU to know the type of RVC overlay";
CM_ SG_ 451 OdoICFullSig "Signal represents Odometer information in full range.This information is used by VICM for Odometer learning.";
BA_DEF_ SG_  "Remarks" STRING ;
BA_DEF_ SG_  "NWM_WakeupAllowed" ENUM  "No","Yes";
BA_DEF_ SG_  "GenSigTimeoutTime_HU_Mid_X451" INT 0 65535;
BA_DEF_ SG_  "GenSigTimeoutTime_HU_High_X451" INT 0 65535;
BA_DEF_ SG_  "GenSigTimeoutTime_HU_B" INT 0 65535;
BA_DEF_ SG_  "GenSigTimeoutTime_HU_A" INT 0 65535;
BA_DEF_ SG_  "GenSigTimeoutTime_BCM_Mid" INT 0 65535;
BA_DEF_ SG_  "GenSigTimeoutMsg_HU_Mid_X451" INT 0 65535;
BA_DEF_ SG_  "GenSigTimeoutMsg_HU_High_X451" INT 0 65535;
BA_DEF_ SG_  "GenSigTimeoutMsg_HU_B" INT 0 65535;
BA_DEF_ SG_  "GenSigTimeoutMsg_HU_A" INT 0 65535;
BA_DEF_ SG_  "GenSigStartValue" INT 0 0;
BA_DEF_ SG_  "GenSigSendType" ENUM  "Cyclic","OnWrite","OnWriteWithRepetition","OnChange","OnChangeWithRepetition","IfActive","IfActiveWithRepetition","NoSigSendType","NotUsed","NotUsed","NotUsed","NotUsed","NotUsed";
BA_DEF_ SG_  "GenSigInactiveValue" INT 0 0;
BA_DEF_ SG_  "GenSigEnvVarType" ENUM  "int","float","undef";
BA_DEF_ SG_  "GenSigCycleTimeActive" INT 0 0;
BA_DEF_ SG_  "GenSigCycleTime" INT 0 0;
BA_DEF_ SG_  "GenSigTimeoutMsg_HU_High_X445" INT 0 65535;
BA_DEF_ SG_  "GenSigTimeoutMsg_HU_Mid_X445" INT 0 65535;
BA_DEF_ SG_  "GenSigTimeoutTime_HU_High_X445" INT 0 65535;
BA_DEF_ SG_  "GenSigTimeoutTime_HU_Mid_X445" INT 0 65535;
BA_DEF_ SG_  "GenSigTimeoutMsg_IVI" INT 0 65535;
BA_DEF_ SG_  "GenSigTimeoutTime_IVI" INT 0 65535;
BA_DEF_ BO_  "NmMessage" ENUM  "no","yes";
BA_DEF_ BO_  "NmAsrMessage" ENUM  "<n.a.>","No","Yes";
BA_DEF_ BO_  "MessageTimeout" INT 0 65535;
BA_DEF_ BO_  "GenMsgStartDelayTime" INT 0 0;
BA_DEF_ BO_  "GenMsgSendType" ENUM  "Cyclic","NotUsed","NotUsed","NotUsed","NotUsed","NotUsed","NotUsed","IfActive","NoMsgSendType","NotUsed";
BA_DEF_ BO_  "GenMsgNrOfRepetition" INT 0 0;
BA_DEF_ BO_  "GenMsgILSupport" ENUM  "No","Yes";
BA_DEF_ BO_  "GenMsgDelayTime" INT 0 0;
BA_DEF_ BO_  "GenMsgCycleTimeFast" INT 0 0;
BA_DEF_ BO_  "GenMsgCycleTime" INT 0 0;
BA_DEF_ BO_  "DiagUudtResponse" ENUM  "false","true";
BA_DEF_ BO_  "DiagUsdtResponse" ENUM  "false","true";
BA_DEF_ BO_  "DiagState" ENUM  "No","Yes";
BA_DEF_ BO_  "DiagResponse" ENUM  "No","Yes";
BA_DEF_ BO_  "DiagRequest" ENUM  "No","Yes";
BA_DEF_ BO_  "MsgType" ENUM  "Application","NM","NMH";
BA_DEF_ SG_  "SystemSignalLongSymbol" STRING ;
BA_DEF_DEF_  "Remarks" "null";
BA_DEF_DEF_  "NWM_WakeupAllowed" "No";
BA_DEF_DEF_  "GenSigTimeoutTime_HU_Mid_X451" 500;
BA_DEF_DEF_  "GenSigTimeoutTime_HU_High_X451" 500;
BA_DEF_DEF_  "GenSigTimeoutTime_HU_B" 500;
BA_DEF_DEF_  "GenSigTimeoutTime_HU_A" 500;
BA_DEF_DEF_  "GenSigTimeoutTime_BCM_Mid" 0;
BA_DEF_DEF_  "GenSigTimeoutMsg_HU_Mid_X451" 500;
BA_DEF_DEF_  "GenSigTimeoutMsg_HU_High_X451" 500;
BA_DEF_DEF_  "GenSigTimeoutMsg_HU_B" 500;
BA_DEF_DEF_  "GenSigTimeoutMsg_HU_A" 500;
BA_DEF_DEF_  "GenSigStartValue" 0;
BA_DEF_DEF_  "GenSigSendType" "Cyclic";
BA_DEF_DEF_  "GenSigInactiveValue" 0;
BA_DEF_DEF_  "GenSigEnvVarType" "undef";
BA_DEF_DEF_  "GenSigCycleTimeActive" 0;
BA_DEF_DEF_  "GenSigCycleTime" 0;
BA_DEF_DEF_  "GenSigTimeoutMsg_HU_High_X445" 500;
BA_DEF_DEF_  "GenSigTimeoutMsg_HU_Mid_X445" 500;
BA_DEF_DEF_  "GenSigTimeoutTime_HU_High_X445" 500;
BA_DEF_DEF_  "GenSigTimeoutTime_HU_Mid_X445" 500;
BA_DEF_DEF_  "GenSigTimeoutMsg_IVI" 500;
BA_DEF_DEF_  "GenSigTimeoutTime_IVI" 500;
BA_DEF_DEF_  "NmMessage" "no";
BA_DEF_DEF_  "NmAsrMessage" "<n.a.>";
BA_DEF_DEF_  "MessageTimeout" 500;
BA_DEF_DEF_  "GenMsgStartDelayTime" 0;
BA_DEF_DEF_  "GenMsgSendType" "Cyclic";
BA_DEF_DEF_  "GenMsgNrOfRepetition" 0;
BA_DEF_DEF_  "GenMsgILSupport" "Yes";
BA_DEF_DEF_  "GenMsgDelayTime" 0;
BA_DEF_DEF_  "GenMsgCycleTimeFast" 0;
BA_DEF_DEF_  "GenMsgCycleTime" 0;
BA_DEF_DEF_  "DiagUudtResponse" "false";
BA_DEF_DEF_  "DiagUsdtResponse" "false";
BA_DEF_DEF_  "DiagState" "No";
BA_DEF_DEF_  "DiagResponse" "No";
BA_DEF_DEF_  "DiagRequest" "No";
BA_DEF_DEF_  "MsgType" "Application";
BA_DEF_DEF_  "SystemSignalLongSymbol" "";
BA_ "MessageTimeout" BO_ 461 0;
BA_ "GenMsgSendType" BO_ 461 8;
BA_ "GenMsgNrOfRepetition" BO_ 461 3;
BA_ "GenMsgDelayTime" BO_ 461 500;
BA_ "GenMsgCycleTimeFast" BO_ 461 500;
BA_ "MessageTimeout" BO_ 489 0;
BA_ "GenMsgSendType" BO_ 489 8;
BA_ "GenMsgNrOfRepetition" BO_ 489 3;
BA_ "GenMsgDelayTime" BO_ 489 500;
BA_ "GenMsgCycleTimeFast" BO_ 489 500;
BA_ "MessageTimeout" BO_ 458 0;
BA_ "GenMsgSendType" BO_ 458 8;
BA_ "GenMsgNrOfRepetition" BO_ 458 3;
BA_ "GenMsgDelayTime" BO_ 458 500;
BA_ "GenMsgCycleTimeFast" BO_ 458 500;
BA_ "GenMsgCycleTime" BO_ 567 50;
BA_ "MessageTimeout" BO_ 960 2500;
BA_ "GenMsgCycleTime" BO_ 960 500;
BA_ "GenMsgCycleTime" BO_ 582 100;
BA_ "GenMsgCycleTime" BO_ 719 100;
BA_ "MessageTimeout" BO_ 493 0;
BA_ "GenMsgSendType" BO_ 493 8;
BA_ "GenMsgNrOfRepetition" BO_ 493 3;
BA_ "GenMsgDelayTime" BO_ 493 100;
BA_ "GenMsgCycleTime" BO_ 581 100;
BA_ "GenMsgCycleTime" BO_ 1330 100;
BA_ "GenMsgCycleTime" BO_ 1329 100;
BA_ "GenMsgCycleTime" BO_ 724 100;
BA_ "GenMsgCycleTime" BO_ 408 20;
BA_ "GenMsgCycleTime" BO_ 738 100;
BA_ "MessageTimeout" BO_ 495 0;
BA_ "GenMsgSendType" BO_ 495 8;
BA_ "GenMsgNrOfRepetition" BO_ 495 10;
BA_ "GenMsgDelayTime" BO_ 495 200;
BA_ "GenMsgCycleTimeFast" BO_ 495 200;
BA_ "GenMsgCycleTime" BO_ 580 100;
BA_ "GenMsgCycleTime" BO_ 579 100;
BA_ "GenMsgCycleTime" BO_ 273 10;
BA_ "GenMsgCycleTime" BO_ 192 10;
BA_ "GenMsgNrOfRepetition" BO_ 259 4;
BA_ "GenMsgCycleTimeFast" BO_ 259 20;
BA_ "GenMsgCycleTime" BO_ 259 100;
BA_ "GenMsgCycleTime" BO_ 277 10;
BA_ "GenMsgCycleTime" BO_ 370 20;
BA_ "GenMsgCycleTime" BO_ 374 20;
BA_ "GenMsgCycleTime" BO_ 376 20;
BA_ "GenMsgCycleTime" BO_ 407 20;
BA_ "MessageTimeout" BO_ 448 0;
BA_ "GenMsgSendType" BO_ 448 8;
BA_ "MessageTimeout" BO_ 451 0;
BA_ "GenMsgSendType" BO_ 451 8;
BA_ "GenMsgNrOfRepetition" BO_ 451 2;
BA_ "GenMsgDelayTime" BO_ 451 60;
BA_ "GenSigTimeoutTime_HU_Mid_X451" SG_ 461 HuBCmWindowWindingHmiCmdReq 0;
BA_ "GenSigTimeoutTime_HU_High_X451" SG_ 461 HuBCmWindowWindingHmiCmdReq 0;
BA_ "GenSigTimeoutTime_HU_B" SG_ 461 HuBCmWindowWindingHmiCmdReq 0;
BA_ "GenSigTimeoutTime_HU_A" SG_ 461 HuBCmWindowWindingHmiCmdReq 0;
BA_ "GenSigTimeoutMsg_HU_Mid_X451" SG_ 461 HuBCmWindowWindingHmiCmdReq 0;
BA_ "GenSigTimeoutMsg_HU_High_X451" SG_ 461 HuBCmWindowWindingHmiCmdReq 0;
BA_ "GenSigTimeoutMsg_HU_B" SG_ 461 HuBCmWindowWindingHmiCmdReq 0;
BA_ "GenSigTimeoutMsg_HU_A" SG_ 461 HuBCmWindowWindingHmiCmdReq 0;
BA_ "GenSigSendType" SG_ 461 HuBCmWindowWindingHmiCmdReq 2;
BA_ "GenSigTimeoutMsg_HU_High_X445" SG_ 461 HuBCmWindowWindingHmiCmdReq 0;
BA_ "GenSigTimeoutMsg_HU_Mid_X445" SG_ 461 HuBCmWindowWindingHmiCmdReq 0;
BA_ "GenSigTimeoutTime_HU_High_X445" SG_ 461 HuBCmWindowWindingHmiCmdReq 0;
BA_ "GenSigTimeoutTime_HU_Mid_X445" SG_ 461 HuBCmWindowWindingHmiCmdReq 0;
BA_ "GenSigTimeoutMsg_IVI" SG_ 461 HuBCmWindowWindingHmiCmdReq 0;
BA_ "GenSigTimeoutTime_IVI" SG_ 461 HuBCmWindowWindingHmiCmdReq 0;
BA_ "GenSigTimeoutTime_HU_Mid_X451" SG_ 461 HuBCmTyreTempHmiVrCmdReq 0;
BA_ "GenSigTimeoutTime_HU_High_X451" SG_ 461 HuBCmTyreTempHmiVrCmdReq 0;
BA_ "GenSigTimeoutTime_HU_B" SG_ 461 HuBCmTyreTempHmiVrCmdReq 0;
BA_ "GenSigTimeoutTime_HU_A" SG_ 461 HuBCmTyreTempHmiVrCmdReq 0;
BA_ "GenSigTimeoutMsg_HU_Mid_X451" SG_ 461 HuBCmTyreTempHmiVrCmdReq 0;
BA_ "GenSigTimeoutMsg_HU_High_X451" SG_ 461 HuBCmTyreTempHmiVrCmdReq 0;
BA_ "GenSigTimeoutMsg_HU_B" SG_ 461 HuBCmTyreTempHmiVrCmdReq 0;
BA_ "GenSigTimeoutMsg_HU_A" SG_ 461 HuBCmTyreTempHmiVrCmdReq 0;
BA_ "GenSigSendType" SG_ 461 HuBCmTyreTempHmiVrCmdReq 2;
BA_ "GenSigTimeoutMsg_HU_High_X445" SG_ 461 HuBCmTyreTempHmiVrCmdReq 0;
BA_ "GenSigTimeoutMsg_HU_Mid_X445" SG_ 461 HuBCmTyreTempHmiVrCmdReq 0;
BA_ "GenSigTimeoutTime_HU_High_X445" SG_ 461 HuBCmTyreTempHmiVrCmdReq 0;
BA_ "GenSigTimeoutTime_HU_Mid_X445" SG_ 461 HuBCmTyreTempHmiVrCmdReq 0;
BA_ "GenSigTimeoutMsg_IVI" SG_ 461 HuBCmTyreTempHmiVrCmdReq 0;
BA_ "GenSigTimeoutTime_IVI" SG_ 461 HuBCmTyreTempHmiVrCmdReq 0;
BA_ "GenSigTimeoutTime_HU_Mid_X451" SG_ 461 HuBCmTyrePressureHmiVrCmdReq 0;
BA_ "GenSigTimeoutTime_HU_High_X451" SG_ 461 HuBCmTyrePressureHmiVrCmdReq 0;
BA_ "GenSigTimeoutTime_HU_B" SG_ 461 HuBCmTyrePressureHmiVrCmdReq 0;
BA_ "GenSigTimeoutTime_HU_A" SG_ 461 HuBCmTyrePressureHmiVrCmdReq 0;
BA_ "GenSigTimeoutMsg_HU_Mid_X451" SG_ 461 HuBCmTyrePressureHmiVrCmdReq 0;
BA_ "GenSigTimeoutMsg_HU_High_X451" SG_ 461 HuBCmTyrePressureHmiVrCmdReq 0;
BA_ "GenSigTimeoutMsg_HU_B" SG_ 461 HuBCmTyrePressureHmiVrCmdReq 0;
BA_ "GenSigTimeoutMsg_HU_A" SG_ 461 HuBCmTyrePressureHmiVrCmdReq 0;
BA_ "GenSigSendType" SG_ 461 HuBCmTyrePressureHmiVrCmdReq 2;
BA_ "GenSigTimeoutMsg_HU_High_X445" SG_ 461 HuBCmTyrePressureHmiVrCmdReq 0;
BA_ "GenSigTimeoutMsg_HU_Mid_X445" SG_ 461 HuBCmTyrePressureHmiVrCmdReq 0;
BA_ "GenSigTimeoutTime_HU_High_X445" SG_ 461 HuBCmTyrePressureHmiVrCmdReq 0;
BA_ "GenSigTimeoutTime_HU_Mid_X445" SG_ 461 HuBCmTyrePressureHmiVrCmdReq 0;
BA_ "GenSigTimeoutMsg_IVI" SG_ 461 HuBCmTyrePressureHmiVrCmdReq 0;
BA_ "GenSigTimeoutTime_IVI" SG_ 461 HuBCmTyrePressureHmiVrCmdReq 0;
BA_ "GenSigTimeoutTime_HU_Mid_X451" SG_ 461 HuBCmRoofLampHmiVrCmdReq 0;
BA_ "GenSigTimeoutTime_HU_High_X451" SG_ 461 HuBCmRoofLampHmiVrCmdReq 0;
BA_ "GenSigTimeoutTime_HU_B" SG_ 461 HuBCmRoofLampHmiVrCmdReq 0;
BA_ "GenSigTimeoutTime_HU_A" SG_ 461 HuBCmRoofLampHmiVrCmdReq 0;
BA_ "GenSigTimeoutMsg_HU_Mid_X451" SG_ 461 HuBCmRoofLampHmiVrCmdReq 0;
BA_ "GenSigTimeoutMsg_HU_High_X451" SG_ 461 HuBCmRoofLampHmiVrCmdReq 0;
BA_ "GenSigTimeoutMsg_HU_B" SG_ 461 HuBCmRoofLampHmiVrCmdReq 0;
BA_ "GenSigTimeoutMsg_HU_A" SG_ 461 HuBCmRoofLampHmiVrCmdReq 0;
BA_ "GenSigSendType" SG_ 461 HuBCmRoofLampHmiVrCmdReq 2;
BA_ "GenSigTimeoutMsg_HU_High_X445" SG_ 461 HuBCmRoofLampHmiVrCmdReq 0;
BA_ "GenSigTimeoutMsg_HU_Mid_X445" SG_ 461 HuBCmRoofLampHmiVrCmdReq 0;
BA_ "GenSigTimeoutTime_HU_High_X445" SG_ 461 HuBCmRoofLampHmiVrCmdReq 0;
BA_ "GenSigTimeoutTime_HU_Mid_X445" SG_ 461 HuBCmRoofLampHmiVrCmdReq 0;
BA_ "GenSigTimeoutMsg_IVI" SG_ 461 HuBCmRoofLampHmiVrCmdReq 0;
BA_ "GenSigTimeoutTime_IVI" SG_ 461 HuBCmRoofLampHmiVrCmdReq 0;
BA_ "GenSigTimeoutTime_HU_Mid_X451" SG_ 461 HuBCmPositionLampVrCmdReq 0;
BA_ "GenSigTimeoutTime_HU_High_X451" SG_ 461 HuBCmPositionLampVrCmdReq 0;
BA_ "GenSigTimeoutTime_HU_B" SG_ 461 HuBCmPositionLampVrCmdReq 0;
BA_ "GenSigTimeoutTime_HU_A" SG_ 461 HuBCmPositionLampVrCmdReq 0;
BA_ "GenSigTimeoutMsg_HU_Mid_X451" SG_ 461 HuBCmPositionLampVrCmdReq 0;
BA_ "GenSigTimeoutMsg_HU_High_X451" SG_ 461 HuBCmPositionLampVrCmdReq 0;
BA_ "GenSigTimeoutMsg_HU_B" SG_ 461 HuBCmPositionLampVrCmdReq 0;
BA_ "GenSigTimeoutMsg_HU_A" SG_ 461 HuBCmPositionLampVrCmdReq 0;
BA_ "GenSigSendType" SG_ 461 HuBCmPositionLampVrCmdReq 2;
BA_ "GenSigTimeoutMsg_HU_High_X445" SG_ 461 HuBCmPositionLampVrCmdReq 0;
BA_ "GenSigTimeoutMsg_HU_Mid_X445" SG_ 461 HuBCmPositionLampVrCmdReq 0;
BA_ "GenSigTimeoutTime_HU_High_X445" SG_ 461 HuBCmPositionLampVrCmdReq 0;
BA_ "GenSigTimeoutTime_HU_Mid_X445" SG_ 461 HuBCmPositionLampVrCmdReq 0;
BA_ "GenSigTimeoutMsg_IVI" SG_ 461 HuBCmPositionLampVrCmdReq 0;
BA_ "GenSigTimeoutTime_IVI" SG_ 461 HuBCmPositionLampVrCmdReq 0;
BA_ "GenSigTimeoutTime_HU_Mid_X451" SG_ 461 HuBCmORVMHmiVrCmdReq 0;
BA_ "GenSigTimeoutTime_HU_High_X451" SG_ 461 HuBCmORVMHmiVrCmdReq 0;
BA_ "GenSigTimeoutTime_HU_B" SG_ 461 HuBCmORVMHmiVrCmdReq 0;
BA_ "GenSigTimeoutTime_HU_A" SG_ 461 HuBCmORVMHmiVrCmdReq 0;
BA_ "GenSigTimeoutMsg_HU_Mid_X451" SG_ 461 HuBCmORVMHmiVrCmdReq 0;
BA_ "GenSigTimeoutMsg_HU_High_X451" SG_ 461 HuBCmORVMHmiVrCmdReq 0;
BA_ "GenSigTimeoutMsg_HU_B" SG_ 461 HuBCmORVMHmiVrCmdReq 0;
BA_ "GenSigTimeoutMsg_HU_A" SG_ 461 HuBCmORVMHmiVrCmdReq 0;
BA_ "GenSigSendType" SG_ 461 HuBCmORVMHmiVrCmdReq 2;
BA_ "GenSigTimeoutMsg_HU_High_X445" SG_ 461 HuBCmORVMHmiVrCmdReq 0;
BA_ "GenSigTimeoutMsg_HU_Mid_X445" SG_ 461 HuBCmORVMHmiVrCmdReq 0;
BA_ "GenSigTimeoutTime_HU_High_X445" SG_ 461 HuBCmORVMHmiVrCmdReq 0;
BA_ "GenSigTimeoutTime_HU_Mid_X445" SG_ 461 HuBCmORVMHmiVrCmdReq 0;
BA_ "GenSigTimeoutMsg_IVI" SG_ 461 HuBCmORVMHmiVrCmdReq 0;
BA_ "GenSigTimeoutTime_IVI" SG_ 461 HuBCmORVMHmiVrCmdReq 0;
BA_ "GenSigTimeoutTime_HU_Mid_X451" SG_ 461 HuBCmMoodLightVrCmdReq 0;
BA_ "GenSigTimeoutTime_HU_High_X451" SG_ 461 HuBCmMoodLightVrCmdReq 0;
BA_ "GenSigTimeoutTime_HU_B" SG_ 461 HuBCmMoodLightVrCmdReq 0;
BA_ "GenSigTimeoutTime_HU_A" SG_ 461 HuBCmMoodLightVrCmdReq 0;
BA_ "GenSigTimeoutMsg_HU_Mid_X451" SG_ 461 HuBCmMoodLightVrCmdReq 0;
BA_ "GenSigTimeoutMsg_HU_High_X451" SG_ 461 HuBCmMoodLightVrCmdReq 0;
BA_ "GenSigTimeoutMsg_HU_B" SG_ 461 HuBCmMoodLightVrCmdReq 0;
BA_ "GenSigTimeoutMsg_HU_A" SG_ 461 HuBCmMoodLightVrCmdReq 0;
BA_ "GenSigSendType" SG_ 461 HuBCmMoodLightVrCmdReq 2;
BA_ "GenSigTimeoutMsg_HU_High_X445" SG_ 461 HuBCmMoodLightVrCmdReq 0;
BA_ "GenSigTimeoutMsg_HU_Mid_X445" SG_ 461 HuBCmMoodLightVrCmdReq 0;
BA_ "GenSigTimeoutTime_HU_High_X445" SG_ 461 HuBCmMoodLightVrCmdReq 0;
BA_ "GenSigTimeoutTime_HU_Mid_X445" SG_ 461 HuBCmMoodLightVrCmdReq 0;
BA_ "GenSigTimeoutMsg_IVI" SG_ 461 HuBCmMoodLightVrCmdReq 0;
BA_ "GenSigTimeoutTime_IVI" SG_ 461 HuBCmMoodLightVrCmdReq 0;
BA_ "GenSigTimeoutTime_HU_Mid_X451" SG_ 461 HuBCmHazardLampVrCmdReq 0;
BA_ "GenSigTimeoutTime_HU_High_X451" SG_ 461 HuBCmHazardLampVrCmdReq 0;
BA_ "GenSigTimeoutTime_HU_B" SG_ 461 HuBCmHazardLampVrCmdReq 0;
BA_ "GenSigTimeoutTime_HU_A" SG_ 461 HuBCmHazardLampVrCmdReq 0;
BA_ "GenSigTimeoutMsg_HU_Mid_X451" SG_ 461 HuBCmHazardLampVrCmdReq 0;
BA_ "GenSigTimeoutMsg_HU_High_X451" SG_ 461 HuBCmHazardLampVrCmdReq 0;
BA_ "GenSigTimeoutMsg_HU_B" SG_ 461 HuBCmHazardLampVrCmdReq 0;
BA_ "GenSigTimeoutMsg_HU_A" SG_ 461 HuBCmHazardLampVrCmdReq 0;
BA_ "GenSigSendType" SG_ 461 HuBCmHazardLampVrCmdReq 2;
BA_ "GenSigTimeoutMsg_HU_High_X445" SG_ 461 HuBCmHazardLampVrCmdReq 0;
BA_ "GenSigTimeoutMsg_HU_Mid_X445" SG_ 461 HuBCmHazardLampVrCmdReq 0;
BA_ "GenSigTimeoutTime_HU_High_X445" SG_ 461 HuBCmHazardLampVrCmdReq 0;
BA_ "GenSigTimeoutTime_HU_Mid_X445" SG_ 461 HuBCmHazardLampVrCmdReq 0;
BA_ "GenSigTimeoutMsg_IVI" SG_ 461 HuBCmHazardLampVrCmdReq 0;
BA_ "GenSigTimeoutTime_IVI" SG_ 461 HuBCmHazardLampVrCmdReq 0;
BA_ "GenSigTimeoutTime_HU_Mid_X451" SG_ 461 HuBCmDRLVrCmdReq 0;
BA_ "GenSigTimeoutTime_HU_High_X451" SG_ 461 HuBCmDRLVrCmdReq 0;
BA_ "GenSigTimeoutTime_HU_B" SG_ 461 HuBCmDRLVrCmdReq 0;
BA_ "GenSigTimeoutTime_HU_A" SG_ 461 HuBCmDRLVrCmdReq 0;
BA_ "GenSigTimeoutMsg_HU_Mid_X451" SG_ 461 HuBCmDRLVrCmdReq 0;
BA_ "GenSigTimeoutMsg_HU_High_X451" SG_ 461 HuBCmDRLVrCmdReq 0;
BA_ "GenSigTimeoutMsg_HU_B" SG_ 461 HuBCmDRLVrCmdReq 0;
BA_ "GenSigTimeoutMsg_HU_A" SG_ 461 HuBCmDRLVrCmdReq 0;
BA_ "GenSigSendType" SG_ 461 HuBCmDRLVrCmdReq 2;
BA_ "GenSigTimeoutMsg_HU_High_X445" SG_ 461 HuBCmDRLVrCmdReq 0;
BA_ "GenSigTimeoutMsg_HU_Mid_X445" SG_ 461 HuBCmDRLVrCmdReq 0;
BA_ "GenSigTimeoutTime_HU_High_X445" SG_ 461 HuBCmDRLVrCmdReq 0;
BA_ "GenSigTimeoutTime_HU_Mid_X445" SG_ 461 HuBCmDRLVrCmdReq 0;
BA_ "GenSigTimeoutMsg_IVI" SG_ 461 HuBCmDRLVrCmdReq 0;
BA_ "GenSigTimeoutTime_IVI" SG_ 461 HuBCmDRLVrCmdReq 0;
BA_ "GenSigTimeoutTime_HU_Mid_X451" SG_ 461 HuBCmAmbientLightVrCmdReq 0;
BA_ "GenSigTimeoutTime_HU_High_X451" SG_ 461 HuBCmAmbientLightVrCmdReq 0;
BA_ "GenSigTimeoutTime_HU_B" SG_ 461 HuBCmAmbientLightVrCmdReq 0;
BA_ "GenSigTimeoutTime_HU_A" SG_ 461 HuBCmAmbientLightVrCmdReq 0;
BA_ "GenSigTimeoutMsg_HU_Mid_X451" SG_ 461 HuBCmAmbientLightVrCmdReq 0;
BA_ "GenSigTimeoutMsg_HU_High_X451" SG_ 461 HuBCmAmbientLightVrCmdReq 0;
BA_ "GenSigTimeoutMsg_HU_B" SG_ 461 HuBCmAmbientLightVrCmdReq 0;
BA_ "GenSigTimeoutMsg_HU_A" SG_ 461 HuBCmAmbientLightVrCmdReq 0;
BA_ "GenSigSendType" SG_ 461 HuBCmAmbientLightVrCmdReq 2;
BA_ "GenSigTimeoutMsg_HU_High_X445" SG_ 461 HuBCmAmbientLightVrCmdReq 0;
BA_ "GenSigTimeoutMsg_HU_Mid_X445" SG_ 461 HuBCmAmbientLightVrCmdReq 0;
BA_ "GenSigTimeoutTime_HU_High_X445" SG_ 461 HuBCmAmbientLightVrCmdReq 0;
BA_ "GenSigTimeoutTime_HU_Mid_X445" SG_ 461 HuBCmAmbientLightVrCmdReq 0;
BA_ "GenSigTimeoutMsg_IVI" SG_ 461 HuBCmAmbientLightVrCmdReq 0;
BA_ "GenSigTimeoutTime_IVI" SG_ 461 HuBCmAmbientLightVrCmdReq 0;
BA_ "GenSigTimeoutTime_HU_Mid_X451" SG_ 461 HuBCmTiltVrCmdReq 0;
BA_ "GenSigTimeoutTime_HU_High_X451" SG_ 461 HuBCmTiltVrCmdReq 0;
BA_ "GenSigTimeoutTime_HU_B" SG_ 461 HuBCmTiltVrCmdReq 0;
BA_ "GenSigTimeoutTime_HU_A" SG_ 461 HuBCmTiltVrCmdReq 0;
BA_ "GenSigTimeoutMsg_HU_Mid_X451" SG_ 461 HuBCmTiltVrCmdReq 0;
BA_ "GenSigTimeoutMsg_HU_High_X451" SG_ 461 HuBCmTiltVrCmdReq 0;
BA_ "GenSigTimeoutMsg_HU_B" SG_ 461 HuBCmTiltVrCmdReq 0;
BA_ "GenSigTimeoutMsg_HU_A" SG_ 461 HuBCmTiltVrCmdReq 0;
BA_ "GenSigSendType" SG_ 461 HuBCmTiltVrCmdReq 2;
BA_ "GenSigTimeoutMsg_HU_High_X445" SG_ 461 HuBCmTiltVrCmdReq 0;
BA_ "GenSigTimeoutMsg_HU_Mid_X445" SG_ 461 HuBCmTiltVrCmdReq 0;
BA_ "GenSigTimeoutTime_HU_High_X445" SG_ 461 HuBCmTiltVrCmdReq 0;
BA_ "GenSigTimeoutTime_HU_Mid_X445" SG_ 461 HuBCmTiltVrCmdReq 0;
BA_ "GenSigTimeoutMsg_IVI" SG_ 461 HuBCmTiltVrCmdReq 0;
BA_ "GenSigTimeoutTime_IVI" SG_ 461 HuBCmTiltVrCmdReq 0;
BA_ "GenSigTimeoutTime_HU_Mid_X451" SG_ 461 HuBCmSunShadeVrCmdReq 0;
BA_ "GenSigTimeoutTime_HU_High_X451" SG_ 461 HuBCmSunShadeVrCmdReq 0;
BA_ "GenSigTimeoutTime_HU_B" SG_ 461 HuBCmSunShadeVrCmdReq 0;
BA_ "GenSigTimeoutTime_HU_A" SG_ 461 HuBCmSunShadeVrCmdReq 0;
BA_ "GenSigTimeoutMsg_HU_Mid_X451" SG_ 461 HuBCmSunShadeVrCmdReq 0;
BA_ "GenSigTimeoutMsg_HU_High_X451" SG_ 461 HuBCmSunShadeVrCmdReq 0;
BA_ "GenSigTimeoutMsg_HU_B" SG_ 461 HuBCmSunShadeVrCmdReq 0;
BA_ "GenSigTimeoutMsg_HU_A" SG_ 461 HuBCmSunShadeVrCmdReq 0;
BA_ "GenSigSendType" SG_ 461 HuBCmSunShadeVrCmdReq 2;
BA_ "GenSigTimeoutMsg_HU_High_X445" SG_ 461 HuBCmSunShadeVrCmdReq 0;
BA_ "GenSigTimeoutMsg_HU_Mid_X445" SG_ 461 HuBCmSunShadeVrCmdReq 0;
BA_ "GenSigTimeoutTime_HU_High_X445" SG_ 461 HuBCmSunShadeVrCmdReq 0;
BA_ "GenSigTimeoutTime_HU_Mid_X445" SG_ 461 HuBCmSunShadeVrCmdReq 0;
BA_ "GenSigTimeoutMsg_IVI" SG_ 461 HuBCmSunShadeVrCmdReq 0;
BA_ "GenSigTimeoutTime_IVI" SG_ 461 HuBCmSunShadeVrCmdReq 0;
BA_ "GenSigTimeoutTime_HU_Mid_X451" SG_ 461 HuBCmSunRoofVrCmdReq 0;
BA_ "GenSigTimeoutTime_HU_High_X451" SG_ 461 HuBCmSunRoofVrCmdReq 0;
BA_ "GenSigTimeoutTime_HU_B" SG_ 461 HuBCmSunRoofVrCmdReq 0;
BA_ "GenSigTimeoutTime_HU_A" SG_ 461 HuBCmSunRoofVrCmdReq 0;
BA_ "GenSigTimeoutMsg_HU_Mid_X451" SG_ 461 HuBCmSunRoofVrCmdReq 0;
BA_ "GenSigTimeoutMsg_HU_High_X451" SG_ 461 HuBCmSunRoofVrCmdReq 0;
BA_ "GenSigTimeoutMsg_HU_B" SG_ 461 HuBCmSunRoofVrCmdReq 0;
BA_ "GenSigTimeoutMsg_HU_A" SG_ 461 HuBCmSunRoofVrCmdReq 0;
BA_ "GenSigSendType" SG_ 461 HuBCmSunRoofVrCmdReq 2;
BA_ "GenSigTimeoutMsg_HU_High_X445" SG_ 461 HuBCmSunRoofVrCmdReq 0;
BA_ "GenSigTimeoutMsg_HU_Mid_X445" SG_ 461 HuBCmSunRoofVrCmdReq 0;
BA_ "GenSigTimeoutTime_HU_High_X445" SG_ 461 HuBCmSunRoofVrCmdReq 0;
BA_ "GenSigTimeoutTime_HU_Mid_X445" SG_ 461 HuBCmSunRoofVrCmdReq 0;
BA_ "GenSigTimeoutMsg_IVI" SG_ 461 HuBCmSunRoofVrCmdReq 0;
BA_ "GenSigTimeoutTime_IVI" SG_ 461 HuBCmSunRoofVrCmdReq 0;
BA_ "GenSigTimeoutTime_HU_Mid_X451" SG_ 489 BCmHuWindowWindingHmiCmdSupport 0;
BA_ "GenSigTimeoutTime_HU_High_X451" SG_ 489 BCmHuWindowWindingHmiCmdSupport 0;
BA_ "GenSigTimeoutTime_HU_B" SG_ 489 BCmHuWindowWindingHmiCmdSupport 0;
BA_ "GenSigTimeoutTime_HU_A" SG_ 489 BCmHuWindowWindingHmiCmdSupport 0;
BA_ "GenSigTimeoutMsg_HU_Mid_X451" SG_ 489 BCmHuWindowWindingHmiCmdSupport 0;
BA_ "GenSigTimeoutMsg_HU_High_X451" SG_ 489 BCmHuWindowWindingHmiCmdSupport 0;
BA_ "GenSigTimeoutMsg_HU_B" SG_ 489 BCmHuWindowWindingHmiCmdSupport 0;
BA_ "GenSigTimeoutMsg_HU_A" SG_ 489 BCmHuWindowWindingHmiCmdSupport 0;
BA_ "GenSigSendType" SG_ 489 BCmHuWindowWindingHmiCmdSupport 2;
BA_ "GenSigTimeoutMsg_HU_High_X445" SG_ 489 BCmHuWindowWindingHmiCmdSupport 0;
BA_ "GenSigTimeoutMsg_HU_Mid_X445" SG_ 489 BCmHuWindowWindingHmiCmdSupport 0;
BA_ "GenSigTimeoutTime_HU_High_X445" SG_ 489 BCmHuWindowWindingHmiCmdSupport 0;
BA_ "GenSigTimeoutTime_HU_Mid_X445" SG_ 489 BCmHuWindowWindingHmiCmdSupport 0;
BA_ "GenSigTimeoutMsg_IVI" SG_ 489 BCmHuWindowWindingHmiCmdSupport 0;
BA_ "GenSigTimeoutTime_IVI" SG_ 489 BCmHuWindowWindingHmiCmdSupport 0;
BA_ "GenSigTimeoutTime_HU_Mid_X451" SG_ 489 BCmHuTyreTempVrCmdSupport 0;
BA_ "GenSigTimeoutTime_HU_High_X451" SG_ 489 BCmHuTyreTempVrCmdSupport 0;
BA_ "GenSigTimeoutTime_HU_B" SG_ 489 BCmHuTyreTempVrCmdSupport 0;
BA_ "GenSigTimeoutTime_HU_A" SG_ 489 BCmHuTyreTempVrCmdSupport 0;
BA_ "GenSigTimeoutMsg_HU_Mid_X451" SG_ 489 BCmHuTyreTempVrCmdSupport 0;
BA_ "GenSigTimeoutMsg_HU_High_X451" SG_ 489 BCmHuTyreTempVrCmdSupport 0;
BA_ "GenSigTimeoutMsg_HU_B" SG_ 489 BCmHuTyreTempVrCmdSupport 0;
BA_ "GenSigTimeoutMsg_HU_A" SG_ 489 BCmHuTyreTempVrCmdSupport 0;
BA_ "GenSigSendType" SG_ 489 BCmHuTyreTempVrCmdSupport 2;
BA_ "GenSigTimeoutMsg_HU_High_X445" SG_ 489 BCmHuTyreTempVrCmdSupport 0;
BA_ "GenSigTimeoutMsg_HU_Mid_X445" SG_ 489 BCmHuTyreTempVrCmdSupport 0;
BA_ "GenSigTimeoutTime_HU_High_X445" SG_ 489 BCmHuTyreTempVrCmdSupport 0;
BA_ "GenSigTimeoutTime_HU_Mid_X445" SG_ 489 BCmHuTyreTempVrCmdSupport 0;
BA_ "GenSigTimeoutMsg_IVI" SG_ 489 BCmHuTyreTempVrCmdSupport 0;
BA_ "GenSigTimeoutTime_IVI" SG_ 489 BCmHuTyreTempVrCmdSupport 0;
BA_ "GenSigTimeoutTime_HU_Mid_X451" SG_ 489 BCmHuTyreTempHmiCmdSupport 0;
BA_ "GenSigTimeoutTime_HU_High_X451" SG_ 489 BCmHuTyreTempHmiCmdSupport 0;
BA_ "GenSigTimeoutTime_HU_B" SG_ 489 BCmHuTyreTempHmiCmdSupport 0;
BA_ "GenSigTimeoutTime_HU_A" SG_ 489 BCmHuTyreTempHmiCmdSupport 0;
BA_ "GenSigTimeoutMsg_HU_Mid_X451" SG_ 489 BCmHuTyreTempHmiCmdSupport 0;
BA_ "GenSigTimeoutMsg_HU_High_X451" SG_ 489 BCmHuTyreTempHmiCmdSupport 0;
BA_ "GenSigTimeoutMsg_HU_B" SG_ 489 BCmHuTyreTempHmiCmdSupport 0;
BA_ "GenSigTimeoutMsg_HU_A" SG_ 489 BCmHuTyreTempHmiCmdSupport 0;
BA_ "GenSigSendType" SG_ 489 BCmHuTyreTempHmiCmdSupport 2;
BA_ "GenSigTimeoutMsg_HU_High_X445" SG_ 489 BCmHuTyreTempHmiCmdSupport 0;
BA_ "GenSigTimeoutMsg_HU_Mid_X445" SG_ 489 BCmHuTyreTempHmiCmdSupport 0;
BA_ "GenSigTimeoutTime_HU_High_X445" SG_ 489 BCmHuTyreTempHmiCmdSupport 0;
BA_ "GenSigTimeoutTime_HU_Mid_X445" SG_ 489 BCmHuTyreTempHmiCmdSupport 0;
BA_ "GenSigTimeoutMsg_IVI" SG_ 489 BCmHuTyreTempHmiCmdSupport 0;
BA_ "GenSigTimeoutTime_IVI" SG_ 489 BCmHuTyreTempHmiCmdSupport 0;
BA_ "GenSigTimeoutTime_HU_Mid_X451" SG_ 489 BCmHuTyrePressureVrCmdSupport 0;
BA_ "GenSigTimeoutTime_HU_High_X451" SG_ 489 BCmHuTyrePressureVrCmdSupport 0;
BA_ "GenSigTimeoutTime_HU_B" SG_ 489 BCmHuTyrePressureVrCmdSupport 0;
BA_ "GenSigTimeoutTime_HU_A" SG_ 489 BCmHuTyrePressureVrCmdSupport 0;
BA_ "GenSigTimeoutMsg_HU_Mid_X451" SG_ 489 BCmHuTyrePressureVrCmdSupport 0;
BA_ "GenSigTimeoutMsg_HU_High_X451" SG_ 489 BCmHuTyrePressureVrCmdSupport 0;
BA_ "GenSigTimeoutMsg_HU_B" SG_ 489 BCmHuTyrePressureVrCmdSupport 0;
BA_ "GenSigTimeoutMsg_HU_A" SG_ 489 BCmHuTyrePressureVrCmdSupport 0;
BA_ "GenSigSendType" SG_ 489 BCmHuTyrePressureVrCmdSupport 2;
BA_ "GenSigTimeoutMsg_HU_High_X445" SG_ 489 BCmHuTyrePressureVrCmdSupport 0;
BA_ "GenSigTimeoutMsg_HU_Mid_X445" SG_ 489 BCmHuTyrePressureVrCmdSupport 0;
BA_ "GenSigTimeoutTime_HU_High_X445" SG_ 489 BCmHuTyrePressureVrCmdSupport 0;
BA_ "GenSigTimeoutTime_HU_Mid_X445" SG_ 489 BCmHuTyrePressureVrCmdSupport 0;
BA_ "GenSigTimeoutMsg_IVI" SG_ 489 BCmHuTyrePressureVrCmdSupport 0;
BA_ "GenSigTimeoutTime_IVI" SG_ 489 BCmHuTyrePressureVrCmdSupport 0;
BA_ "GenSigTimeoutTime_HU_Mid_X451" SG_ 489 BCmHuTyrePressureHmiCmdSupport 0;
BA_ "GenSigTimeoutTime_HU_High_X451" SG_ 489 BCmHuTyrePressureHmiCmdSupport 0;
BA_ "GenSigTimeoutTime_HU_B" SG_ 489 BCmHuTyrePressureHmiCmdSupport 0;
BA_ "GenSigTimeoutTime_HU_A" SG_ 489 BCmHuTyrePressureHmiCmdSupport 0;
BA_ "GenSigTimeoutMsg_HU_Mid_X451" SG_ 489 BCmHuTyrePressureHmiCmdSupport 0;
BA_ "GenSigTimeoutMsg_HU_High_X451" SG_ 489 BCmHuTyrePressureHmiCmdSupport 0;
BA_ "GenSigTimeoutMsg_HU_B" SG_ 489 BCmHuTyrePressureHmiCmdSupport 0;
BA_ "GenSigTimeoutMsg_HU_A" SG_ 489 BCmHuTyrePressureHmiCmdSupport 0;
BA_ "GenSigSendType" SG_ 489 BCmHuTyrePressureHmiCmdSupport 2;
BA_ "GenSigTimeoutMsg_HU_High_X445" SG_ 489 BCmHuTyrePressureHmiCmdSupport 0;
BA_ "GenSigTimeoutMsg_HU_Mid_X445" SG_ 489 BCmHuTyrePressureHmiCmdSupport 0;
BA_ "GenSigTimeoutTime_HU_High_X445" SG_ 489 BCmHuTyrePressureHmiCmdSupport 0;
BA_ "GenSigTimeoutTime_HU_Mid_X445" SG_ 489 BCmHuTyrePressureHmiCmdSupport 0;
BA_ "GenSigTimeoutMsg_IVI" SG_ 489 BCmHuTyrePressureHmiCmdSupport 0;
BA_ "GenSigTimeoutTime_IVI" SG_ 489 BCmHuTyrePressureHmiCmdSupport 0;
BA_ "GenSigTimeoutTime_HU_Mid_X451" SG_ 489 BCmHuSunroofTiltVrCmdSupport 0;
BA_ "GenSigTimeoutTime_HU_High_X451" SG_ 489 BCmHuSunroofTiltVrCmdSupport 0;
BA_ "GenSigTimeoutTime_HU_B" SG_ 489 BCmHuSunroofTiltVrCmdSupport 0;
BA_ "GenSigTimeoutTime_HU_A" SG_ 489 BCmHuSunroofTiltVrCmdSupport 0;
BA_ "GenSigTimeoutMsg_HU_Mid_X451" SG_ 489 BCmHuSunroofTiltVrCmdSupport 0;
BA_ "GenSigTimeoutMsg_HU_High_X451" SG_ 489 BCmHuSunroofTiltVrCmdSupport 0;
BA_ "GenSigTimeoutMsg_HU_B" SG_ 489 BCmHuSunroofTiltVrCmdSupport 0;
BA_ "GenSigTimeoutMsg_HU_A" SG_ 489 BCmHuSunroofTiltVrCmdSupport 0;
BA_ "GenSigSendType" SG_ 489 BCmHuSunroofTiltVrCmdSupport 2;
BA_ "GenSigTimeoutMsg_HU_High_X445" SG_ 489 BCmHuSunroofTiltVrCmdSupport 0;
BA_ "GenSigTimeoutMsg_HU_Mid_X445" SG_ 489 BCmHuSunroofTiltVrCmdSupport 0;
BA_ "GenSigTimeoutTime_HU_High_X445" SG_ 489 BCmHuSunroofTiltVrCmdSupport 0;
BA_ "GenSigTimeoutTime_HU_Mid_X445" SG_ 489 BCmHuSunroofTiltVrCmdSupport 0;
BA_ "GenSigTimeoutMsg_IVI" SG_ 489 BCmHuSunroofTiltVrCmdSupport 0;
BA_ "GenSigTimeoutTime_IVI" SG_ 489 BCmHuSunroofTiltVrCmdSupport 0;
BA_ "GenSigTimeoutTime_HU_Mid_X451" SG_ 489 BCmHuRoofLampVrCmdSupport 0;
BA_ "GenSigTimeoutTime_HU_High_X451" SG_ 489 BCmHuRoofLampVrCmdSupport 0;
BA_ "GenSigTimeoutTime_HU_B" SG_ 489 BCmHuRoofLampVrCmdSupport 0;
BA_ "GenSigTimeoutTime_HU_A" SG_ 489 BCmHuRoofLampVrCmdSupport 0;
BA_ "GenSigTimeoutMsg_HU_Mid_X451" SG_ 489 BCmHuRoofLampVrCmdSupport 0;
BA_ "GenSigTimeoutMsg_HU_High_X451" SG_ 489 BCmHuRoofLampVrCmdSupport 0;
BA_ "GenSigTimeoutMsg_HU_B" SG_ 489 BCmHuRoofLampVrCmdSupport 0;
BA_ "GenSigTimeoutMsg_HU_A" SG_ 489 BCmHuRoofLampVrCmdSupport 0;
BA_ "GenSigSendType" SG_ 489 BCmHuRoofLampVrCmdSupport 2;
BA_ "GenSigTimeoutMsg_HU_High_X445" SG_ 489 BCmHuRoofLampVrCmdSupport 0;
BA_ "GenSigTimeoutMsg_HU_Mid_X445" SG_ 489 BCmHuRoofLampVrCmdSupport 0;
BA_ "GenSigTimeoutTime_HU_High_X445" SG_ 489 BCmHuRoofLampVrCmdSupport 0;
BA_ "GenSigTimeoutTime_HU_Mid_X445" SG_ 489 BCmHuRoofLampVrCmdSupport 0;
BA_ "GenSigTimeoutMsg_IVI" SG_ 489 BCmHuRoofLampVrCmdSupport 0;
BA_ "GenSigTimeoutTime_IVI" SG_ 489 BCmHuRoofLampVrCmdSupport 0;
BA_ "GenSigTimeoutTime_HU_Mid_X451" SG_ 489 BCmHuRoofLampHmiCmdSupport 0;
BA_ "GenSigTimeoutTime_HU_High_X451" SG_ 489 BCmHuRoofLampHmiCmdSupport 0;
BA_ "GenSigTimeoutTime_HU_B" SG_ 489 BCmHuRoofLampHmiCmdSupport 0;
BA_ "GenSigTimeoutTime_HU_A" SG_ 489 BCmHuRoofLampHmiCmdSupport 0;
BA_ "GenSigTimeoutMsg_HU_Mid_X451" SG_ 489 BCmHuRoofLampHmiCmdSupport 0;
BA_ "GenSigTimeoutMsg_HU_High_X451" SG_ 489 BCmHuRoofLampHmiCmdSupport 0;
BA_ "GenSigTimeoutMsg_HU_B" SG_ 489 BCmHuRoofLampHmiCmdSupport 0;
BA_ "GenSigTimeoutMsg_HU_A" SG_ 489 BCmHuRoofLampHmiCmdSupport 0;
BA_ "GenSigSendType" SG_ 489 BCmHuRoofLampHmiCmdSupport 2;
BA_ "GenSigTimeoutMsg_HU_High_X445" SG_ 489 BCmHuRoofLampHmiCmdSupport 0;
BA_ "GenSigTimeoutMsg_HU_Mid_X445" SG_ 489 BCmHuRoofLampHmiCmdSupport 0;
BA_ "GenSigTimeoutTime_HU_High_X445" SG_ 489 BCmHuRoofLampHmiCmdSupport 0;
BA_ "GenSigTimeoutTime_HU_Mid_X445" SG_ 489 BCmHuRoofLampHmiCmdSupport 0;
BA_ "GenSigTimeoutMsg_IVI" SG_ 489 BCmHuRoofLampHmiCmdSupport 0;
BA_ "GenSigTimeoutTime_IVI" SG_ 489 BCmHuRoofLampHmiCmdSupport 0;
BA_ "GenSigTimeoutTime_HU_Mid_X451" SG_ 489 BCmHuPositionLampVrCmdSupport 0;
BA_ "GenSigTimeoutTime_HU_High_X451" SG_ 489 BCmHuPositionLampVrCmdSupport 0;
BA_ "GenSigTimeoutTime_HU_B" SG_ 489 BCmHuPositionLampVrCmdSupport 0;
BA_ "GenSigTimeoutTime_HU_A" SG_ 489 BCmHuPositionLampVrCmdSupport 0;
BA_ "GenSigTimeoutMsg_HU_Mid_X451" SG_ 489 BCmHuPositionLampVrCmdSupport 0;
BA_ "GenSigTimeoutMsg_HU_High_X451" SG_ 489 BCmHuPositionLampVrCmdSupport 0;
BA_ "GenSigTimeoutMsg_HU_B" SG_ 489 BCmHuPositionLampVrCmdSupport 0;
BA_ "GenSigTimeoutMsg_HU_A" SG_ 489 BCmHuPositionLampVrCmdSupport 0;
BA_ "GenSigSendType" SG_ 489 BCmHuPositionLampVrCmdSupport 2;
BA_ "GenSigTimeoutMsg_HU_High_X445" SG_ 489 BCmHuPositionLampVrCmdSupport 0;
BA_ "GenSigTimeoutMsg_HU_Mid_X445" SG_ 489 BCmHuPositionLampVrCmdSupport 0;
BA_ "GenSigTimeoutTime_HU_High_X445" SG_ 489 BCmHuPositionLampVrCmdSupport 0;
BA_ "GenSigTimeoutTime_HU_Mid_X445" SG_ 489 BCmHuPositionLampVrCmdSupport 0;
BA_ "GenSigTimeoutMsg_IVI" SG_ 489 BCmHuPositionLampVrCmdSupport 0;
BA_ "GenSigTimeoutTime_IVI" SG_ 489 BCmHuPositionLampVrCmdSupport 0;
BA_ "GenSigTimeoutTime_HU_Mid_X451" SG_ 489 BCmHuORVMVrCmdSupport 0;
BA_ "GenSigTimeoutTime_HU_High_X451" SG_ 489 BCmHuORVMVrCmdSupport 0;
BA_ "GenSigTimeoutTime_HU_B" SG_ 489 BCmHuORVMVrCmdSupport 0;
BA_ "GenSigTimeoutTime_HU_A" SG_ 489 BCmHuORVMVrCmdSupport 0;
BA_ "GenSigTimeoutMsg_HU_Mid_X451" SG_ 489 BCmHuORVMVrCmdSupport 0;
BA_ "GenSigTimeoutMsg_HU_High_X451" SG_ 489 BCmHuORVMVrCmdSupport 0;
BA_ "GenSigTimeoutMsg_HU_B" SG_ 489 BCmHuORVMVrCmdSupport 0;
BA_ "GenSigTimeoutMsg_HU_A" SG_ 489 BCmHuORVMVrCmdSupport 0;
BA_ "GenSigSendType" SG_ 489 BCmHuORVMVrCmdSupport 2;
BA_ "GenSigTimeoutMsg_HU_High_X445" SG_ 489 BCmHuORVMVrCmdSupport 0;
BA_ "GenSigTimeoutMsg_HU_Mid_X445" SG_ 489 BCmHuORVMVrCmdSupport 0;
BA_ "GenSigTimeoutTime_HU_High_X445" SG_ 489 BCmHuORVMVrCmdSupport 0;
BA_ "GenSigTimeoutTime_HU_Mid_X445" SG_ 489 BCmHuORVMVrCmdSupport 0;
BA_ "GenSigTimeoutMsg_IVI" SG_ 489 BCmHuORVMVrCmdSupport 0;
BA_ "GenSigTimeoutTime_IVI" SG_ 489 BCmHuORVMVrCmdSupport 0;
BA_ "GenSigTimeoutTime_HU_Mid_X451" SG_ 489 BCmHuORVMHmiCmdSupport 0;
BA_ "GenSigTimeoutTime_HU_High_X451" SG_ 489 BCmHuORVMHmiCmdSupport 0;
BA_ "GenSigTimeoutTime_HU_B" SG_ 489 BCmHuORVMHmiCmdSupport 0;
BA_ "GenSigTimeoutTime_HU_A" SG_ 489 BCmHuORVMHmiCmdSupport 0;
BA_ "GenSigTimeoutMsg_HU_Mid_X451" SG_ 489 BCmHuORVMHmiCmdSupport 0;
BA_ "GenSigTimeoutMsg_HU_High_X451" SG_ 489 BCmHuORVMHmiCmdSupport 0;
BA_ "GenSigTimeoutMsg_HU_B" SG_ 489 BCmHuORVMHmiCmdSupport 0;
BA_ "GenSigTimeoutMsg_HU_A" SG_ 489 BCmHuORVMHmiCmdSupport 0;
BA_ "GenSigSendType" SG_ 489 BCmHuORVMHmiCmdSupport 2;
BA_ "GenSigTimeoutMsg_HU_High_X445" SG_ 489 BCmHuORVMHmiCmdSupport 0;
BA_ "GenSigTimeoutMsg_HU_Mid_X445" SG_ 489 BCmHuORVMHmiCmdSupport 0;
BA_ "GenSigTimeoutTime_HU_High_X445" SG_ 489 BCmHuORVMHmiCmdSupport 0;
BA_ "GenSigTimeoutTime_HU_Mid_X445" SG_ 489 BCmHuORVMHmiCmdSupport 0;
BA_ "GenSigTimeoutMsg_IVI" SG_ 489 BCmHuORVMHmiCmdSupport 0;
BA_ "GenSigTimeoutTime_IVI" SG_ 489 BCmHuORVMHmiCmdSupport 0;
BA_ "GenSigTimeoutTime_HU_Mid_X451" SG_ 489 BCmHuMoodLightVrCmdSupport 0;
BA_ "GenSigTimeoutTime_HU_High_X451" SG_ 489 BCmHuMoodLightVrCmdSupport 0;
BA_ "GenSigTimeoutTime_HU_B" SG_ 489 BCmHuMoodLightVrCmdSupport 0;
BA_ "GenSigTimeoutTime_HU_A" SG_ 489 BCmHuMoodLightVrCmdSupport 0;
BA_ "GenSigTimeoutMsg_HU_Mid_X451" SG_ 489 BCmHuMoodLightVrCmdSupport 0;
BA_ "GenSigTimeoutMsg_HU_High_X451" SG_ 489 BCmHuMoodLightVrCmdSupport 0;
BA_ "GenSigTimeoutMsg_HU_B" SG_ 489 BCmHuMoodLightVrCmdSupport 0;
BA_ "GenSigTimeoutMsg_HU_A" SG_ 489 BCmHuMoodLightVrCmdSupport 0;
BA_ "GenSigSendType" SG_ 489 BCmHuMoodLightVrCmdSupport 2;
BA_ "GenSigTimeoutMsg_HU_High_X445" SG_ 489 BCmHuMoodLightVrCmdSupport 0;
BA_ "GenSigTimeoutMsg_HU_Mid_X445" SG_ 489 BCmHuMoodLightVrCmdSupport 0;
BA_ "GenSigTimeoutTime_HU_High_X445" SG_ 489 BCmHuMoodLightVrCmdSupport 0;
BA_ "GenSigTimeoutTime_HU_Mid_X445" SG_ 489 BCmHuMoodLightVrCmdSupport 0;
BA_ "GenSigTimeoutMsg_IVI" SG_ 489 BCmHuMoodLightVrCmdSupport 0;
BA_ "GenSigTimeoutTime_IVI" SG_ 489 BCmHuMoodLightVrCmdSupport 0;
BA_ "GenSigTimeoutTime_HU_Mid_X451" SG_ 489 BCmHuHazardLampVrCmdSupport 0;
BA_ "GenSigTimeoutTime_HU_High_X451" SG_ 489 BCmHuHazardLampVrCmdSupport 0;
BA_ "GenSigTimeoutTime_HU_B" SG_ 489 BCmHuHazardLampVrCmdSupport 0;
BA_ "GenSigTimeoutTime_HU_A" SG_ 489 BCmHuHazardLampVrCmdSupport 0;
BA_ "GenSigTimeoutMsg_HU_Mid_X451" SG_ 489 BCmHuHazardLampVrCmdSupport 0;
BA_ "GenSigTimeoutMsg_HU_High_X451" SG_ 489 BCmHuHazardLampVrCmdSupport 0;
BA_ "GenSigTimeoutMsg_HU_B" SG_ 489 BCmHuHazardLampVrCmdSupport 0;
BA_ "GenSigTimeoutMsg_HU_A" SG_ 489 BCmHuHazardLampVrCmdSupport 0;
BA_ "GenSigSendType" SG_ 489 BCmHuHazardLampVrCmdSupport 2;
BA_ "GenSigTimeoutMsg_HU_High_X445" SG_ 489 BCmHuHazardLampVrCmdSupport 0;
BA_ "GenSigTimeoutMsg_HU_Mid_X445" SG_ 489 BCmHuHazardLampVrCmdSupport 0;
BA_ "GenSigTimeoutTime_HU_High_X445" SG_ 489 BCmHuHazardLampVrCmdSupport 0;
BA_ "GenSigTimeoutTime_HU_Mid_X445" SG_ 489 BCmHuHazardLampVrCmdSupport 0;
BA_ "GenSigTimeoutMsg_IVI" SG_ 489 BCmHuHazardLampVrCmdSupport 0;
BA_ "GenSigTimeoutTime_IVI" SG_ 489 BCmHuHazardLampVrCmdSupport 0;
BA_ "GenSigTimeoutTime_HU_Mid_X451" SG_ 489 BCmHuDRLVrCmdSupport 0;
BA_ "GenSigTimeoutTime_HU_High_X451" SG_ 489 BCmHuDRLVrCmdSupport 0;
BA_ "GenSigTimeoutTime_HU_B" SG_ 489 BCmHuDRLVrCmdSupport 0;
BA_ "GenSigTimeoutTime_HU_A" SG_ 489 BCmHuDRLVrCmdSupport 0;
BA_ "GenSigTimeoutMsg_HU_Mid_X451" SG_ 489 BCmHuDRLVrCmdSupport 0;
BA_ "GenSigTimeoutMsg_HU_High_X451" SG_ 489 BCmHuDRLVrCmdSupport 0;
BA_ "GenSigTimeoutMsg_HU_B" SG_ 489 BCmHuDRLVrCmdSupport 0;
BA_ "GenSigTimeoutMsg_HU_A" SG_ 489 BCmHuDRLVrCmdSupport 0;
BA_ "GenSigSendType" SG_ 489 BCmHuDRLVrCmdSupport 2;
BA_ "GenSigTimeoutMsg_HU_High_X445" SG_ 489 BCmHuDRLVrCmdSupport 0;
BA_ "GenSigTimeoutMsg_HU_Mid_X445" SG_ 489 BCmHuDRLVrCmdSupport 0;
BA_ "GenSigTimeoutTime_HU_High_X445" SG_ 489 BCmHuDRLVrCmdSupport 0;
BA_ "GenSigTimeoutTime_HU_Mid_X445" SG_ 489 BCmHuDRLVrCmdSupport 0;
BA_ "GenSigTimeoutMsg_IVI" SG_ 489 BCmHuDRLVrCmdSupport 0;
BA_ "GenSigTimeoutTime_IVI" SG_ 489 BCmHuDRLVrCmdSupport 0;
BA_ "GenSigTimeoutTime_HU_Mid_X451" SG_ 489 BCmHuAmbientLightVrCmdSupport 0;
BA_ "GenSigTimeoutTime_HU_High_X451" SG_ 489 BCmHuAmbientLightVrCmdSupport 0;
BA_ "GenSigTimeoutTime_HU_B" SG_ 489 BCmHuAmbientLightVrCmdSupport 0;
BA_ "GenSigTimeoutTime_HU_A" SG_ 489 BCmHuAmbientLightVrCmdSupport 0;
BA_ "GenSigTimeoutMsg_HU_Mid_X451" SG_ 489 BCmHuAmbientLightVrCmdSupport 0;
BA_ "GenSigTimeoutMsg_HU_High_X451" SG_ 489 BCmHuAmbientLightVrCmdSupport 0;
BA_ "GenSigTimeoutMsg_HU_B" SG_ 489 BCmHuAmbientLightVrCmdSupport 0;
BA_ "GenSigTimeoutMsg_HU_A" SG_ 489 BCmHuAmbientLightVrCmdSupport 0;
BA_ "GenSigSendType" SG_ 489 BCmHuAmbientLightVrCmdSupport 2;
BA_ "GenSigTimeoutMsg_HU_High_X445" SG_ 489 BCmHuAmbientLightVrCmdSupport 0;
BA_ "GenSigTimeoutMsg_HU_Mid_X445" SG_ 489 BCmHuAmbientLightVrCmdSupport 0;
BA_ "GenSigTimeoutTime_HU_High_X445" SG_ 489 BCmHuAmbientLightVrCmdSupport 0;
BA_ "GenSigTimeoutTime_HU_Mid_X445" SG_ 489 BCmHuAmbientLightVrCmdSupport 0;
BA_ "GenSigTimeoutMsg_IVI" SG_ 489 BCmHuAmbientLightVrCmdSupport 0;
BA_ "GenSigTimeoutTime_IVI" SG_ 489 BCmHuAmbientLightVrCmdSupport 0;
BA_ "GenSigTimeoutTime_HU_Mid_X451" SG_ 489 BCmHuSunShadeVrCmdSupport 0;
BA_ "GenSigTimeoutTime_HU_High_X451" SG_ 489 BCmHuSunShadeVrCmdSupport 0;
BA_ "GenSigTimeoutTime_HU_B" SG_ 489 BCmHuSunShadeVrCmdSupport 0;
BA_ "GenSigTimeoutTime_HU_A" SG_ 489 BCmHuSunShadeVrCmdSupport 0;
BA_ "GenSigTimeoutMsg_HU_Mid_X451" SG_ 489 BCmHuSunShadeVrCmdSupport 0;
BA_ "GenSigTimeoutMsg_HU_High_X451" SG_ 489 BCmHuSunShadeVrCmdSupport 0;
BA_ "GenSigTimeoutMsg_HU_B" SG_ 489 BCmHuSunShadeVrCmdSupport 0;
BA_ "GenSigTimeoutMsg_HU_A" SG_ 489 BCmHuSunShadeVrCmdSupport 0;
BA_ "GenSigSendType" SG_ 489 BCmHuSunShadeVrCmdSupport 2;
BA_ "GenSigTimeoutMsg_HU_High_X445" SG_ 489 BCmHuSunShadeVrCmdSupport 0;
BA_ "GenSigTimeoutMsg_HU_Mid_X445" SG_ 489 BCmHuSunShadeVrCmdSupport 0;
BA_ "GenSigTimeoutTime_HU_High_X445" SG_ 489 BCmHuSunShadeVrCmdSupport 0;
BA_ "GenSigTimeoutTime_HU_Mid_X445" SG_ 489 BCmHuSunShadeVrCmdSupport 0;
BA_ "GenSigTimeoutMsg_IVI" SG_ 489 BCmHuSunShadeVrCmdSupport 0;
BA_ "GenSigTimeoutTime_IVI" SG_ 489 BCmHuSunShadeVrCmdSupport 0;
BA_ "GenSigTimeoutTime_HU_Mid_X451" SG_ 489 BCmHuSunRoofVrCmdSupport 0;
BA_ "GenSigTimeoutTime_HU_High_X451" SG_ 489 BCmHuSunRoofVrCmdSupport 0;
BA_ "GenSigTimeoutTime_HU_B" SG_ 489 BCmHuSunRoofVrCmdSupport 0;
BA_ "GenSigTimeoutTime_HU_A" SG_ 489 BCmHuSunRoofVrCmdSupport 0;
BA_ "GenSigTimeoutMsg_HU_Mid_X451" SG_ 489 BCmHuSunRoofVrCmdSupport 0;
BA_ "GenSigTimeoutMsg_HU_High_X451" SG_ 489 BCmHuSunRoofVrCmdSupport 0;
BA_ "GenSigTimeoutMsg_HU_B" SG_ 489 BCmHuSunRoofVrCmdSupport 0;
BA_ "GenSigTimeoutMsg_HU_A" SG_ 489 BCmHuSunRoofVrCmdSupport 0;
BA_ "GenSigSendType" SG_ 489 BCmHuSunRoofVrCmdSupport 2;
BA_ "GenSigTimeoutMsg_HU_High_X445" SG_ 489 BCmHuSunRoofVrCmdSupport 0;
BA_ "GenSigTimeoutMsg_HU_Mid_X445" SG_ 489 BCmHuSunRoofVrCmdSupport 0;
BA_ "GenSigTimeoutTime_HU_High_X445" SG_ 489 BCmHuSunRoofVrCmdSupport 0;
BA_ "GenSigTimeoutTime_HU_Mid_X445" SG_ 489 BCmHuSunRoofVrCmdSupport 0;
BA_ "GenSigTimeoutMsg_IVI" SG_ 489 BCmHuSunRoofVrCmdSupport 0;
BA_ "GenSigTimeoutTime_IVI" SG_ 489 BCmHuSunRoofVrCmdSupport 0;
BA_ "GenSigTimeoutTime_HU_Mid_X451" SG_ 458 BCmHuWindowWindingHmiCmdAck 0;
BA_ "GenSigTimeoutTime_HU_High_X451" SG_ 458 BCmHuWindowWindingHmiCmdAck 0;
BA_ "GenSigTimeoutTime_HU_B" SG_ 458 BCmHuWindowWindingHmiCmdAck 0;
BA_ "GenSigTimeoutTime_HU_A" SG_ 458 BCmHuWindowWindingHmiCmdAck 0;
BA_ "GenSigTimeoutMsg_HU_Mid_X451" SG_ 458 BCmHuWindowWindingHmiCmdAck 0;
BA_ "GenSigTimeoutMsg_HU_High_X451" SG_ 458 BCmHuWindowWindingHmiCmdAck 0;
BA_ "GenSigTimeoutMsg_HU_B" SG_ 458 BCmHuWindowWindingHmiCmdAck 0;
BA_ "GenSigTimeoutMsg_HU_A" SG_ 458 BCmHuWindowWindingHmiCmdAck 0;
BA_ "GenSigSendType" SG_ 458 BCmHuWindowWindingHmiCmdAck 2;
BA_ "GenSigTimeoutMsg_HU_High_X445" SG_ 458 BCmHuWindowWindingHmiCmdAck 0;
BA_ "GenSigTimeoutMsg_HU_Mid_X445" SG_ 458 BCmHuWindowWindingHmiCmdAck 0;
BA_ "GenSigTimeoutTime_HU_High_X445" SG_ 458 BCmHuWindowWindingHmiCmdAck 0;
BA_ "GenSigTimeoutTime_HU_Mid_X445" SG_ 458 BCmHuWindowWindingHmiCmdAck 0;
BA_ "GenSigTimeoutMsg_IVI" SG_ 458 BCmHuWindowWindingHmiCmdAck 0;
BA_ "GenSigTimeoutTime_IVI" SG_ 458 BCmHuWindowWindingHmiCmdAck 0;
BA_ "GenSigTimeoutTime_HU_Mid_X451" SG_ 458 BCmHuTyreTempHmiVrCmdAck 0;
BA_ "GenSigTimeoutTime_HU_High_X451" SG_ 458 BCmHuTyreTempHmiVrCmdAck 0;
BA_ "GenSigTimeoutTime_HU_B" SG_ 458 BCmHuTyreTempHmiVrCmdAck 0;
BA_ "GenSigTimeoutTime_HU_A" SG_ 458 BCmHuTyreTempHmiVrCmdAck 0;
BA_ "GenSigTimeoutMsg_HU_Mid_X451" SG_ 458 BCmHuTyreTempHmiVrCmdAck 0;
BA_ "GenSigTimeoutMsg_HU_High_X451" SG_ 458 BCmHuTyreTempHmiVrCmdAck 0;
BA_ "GenSigTimeoutMsg_HU_B" SG_ 458 BCmHuTyreTempHmiVrCmdAck 0;
BA_ "GenSigTimeoutMsg_HU_A" SG_ 458 BCmHuTyreTempHmiVrCmdAck 0;
BA_ "GenSigSendType" SG_ 458 BCmHuTyreTempHmiVrCmdAck 2;
BA_ "GenSigTimeoutMsg_HU_High_X445" SG_ 458 BCmHuTyreTempHmiVrCmdAck 0;
BA_ "GenSigTimeoutMsg_HU_Mid_X445" SG_ 458 BCmHuTyreTempHmiVrCmdAck 0;
BA_ "GenSigTimeoutTime_HU_High_X445" SG_ 458 BCmHuTyreTempHmiVrCmdAck 0;
BA_ "GenSigTimeoutTime_HU_Mid_X445" SG_ 458 BCmHuTyreTempHmiVrCmdAck 0;
BA_ "GenSigTimeoutMsg_IVI" SG_ 458 BCmHuTyreTempHmiVrCmdAck 0;
BA_ "GenSigTimeoutTime_IVI" SG_ 458 BCmHuTyreTempHmiVrCmdAck 0;
BA_ "GenSigTimeoutTime_HU_Mid_X451" SG_ 458 BCmHuTyrePressureHmiVrCmdAck 0;
BA_ "GenSigTimeoutTime_HU_High_X451" SG_ 458 BCmHuTyrePressureHmiVrCmdAck 0;
BA_ "GenSigTimeoutTime_HU_B" SG_ 458 BCmHuTyrePressureHmiVrCmdAck 0;
BA_ "GenSigTimeoutTime_HU_A" SG_ 458 BCmHuTyrePressureHmiVrCmdAck 0;
BA_ "GenSigTimeoutMsg_HU_Mid_X451" SG_ 458 BCmHuTyrePressureHmiVrCmdAck 0;
BA_ "GenSigTimeoutMsg_HU_High_X451" SG_ 458 BCmHuTyrePressureHmiVrCmdAck 0;
BA_ "GenSigTimeoutMsg_HU_B" SG_ 458 BCmHuTyrePressureHmiVrCmdAck 0;
BA_ "GenSigTimeoutMsg_HU_A" SG_ 458 BCmHuTyrePressureHmiVrCmdAck 0;
BA_ "GenSigSendType" SG_ 458 BCmHuTyrePressureHmiVrCmdAck 2;
BA_ "GenSigTimeoutMsg_HU_High_X445" SG_ 458 BCmHuTyrePressureHmiVrCmdAck 0;
BA_ "GenSigTimeoutMsg_HU_Mid_X445" SG_ 458 BCmHuTyrePressureHmiVrCmdAck 0;
BA_ "GenSigTimeoutTime_HU_High_X445" SG_ 458 BCmHuTyrePressureHmiVrCmdAck 0;
BA_ "GenSigTimeoutTime_HU_Mid_X445" SG_ 458 BCmHuTyrePressureHmiVrCmdAck 0;
BA_ "GenSigTimeoutMsg_IVI" SG_ 458 BCmHuTyrePressureHmiVrCmdAck 0;
BA_ "GenSigTimeoutTime_IVI" SG_ 458 BCmHuTyrePressureHmiVrCmdAck 0;
BA_ "GenSigTimeoutTime_HU_Mid_X451" SG_ 458 BCmHuRoofLampHmiVrCmdAck 0;
BA_ "GenSigTimeoutTime_HU_High_X451" SG_ 458 BCmHuRoofLampHmiVrCmdAck 0;
BA_ "GenSigTimeoutTime_HU_B" SG_ 458 BCmHuRoofLampHmiVrCmdAck 0;
BA_ "GenSigTimeoutTime_HU_A" SG_ 458 BCmHuRoofLampHmiVrCmdAck 0;
BA_ "GenSigTimeoutMsg_HU_Mid_X451" SG_ 458 BCmHuRoofLampHmiVrCmdAck 0;
BA_ "GenSigTimeoutMsg_HU_High_X451" SG_ 458 BCmHuRoofLampHmiVrCmdAck 0;
BA_ "GenSigTimeoutMsg_HU_B" SG_ 458 BCmHuRoofLampHmiVrCmdAck 0;
BA_ "GenSigTimeoutMsg_HU_A" SG_ 458 BCmHuRoofLampHmiVrCmdAck 0;
BA_ "GenSigSendType" SG_ 458 BCmHuRoofLampHmiVrCmdAck 2;
BA_ "GenSigTimeoutMsg_HU_High_X445" SG_ 458 BCmHuRoofLampHmiVrCmdAck 0;
BA_ "GenSigTimeoutMsg_HU_Mid_X445" SG_ 458 BCmHuRoofLampHmiVrCmdAck 0;
BA_ "GenSigTimeoutTime_HU_High_X445" SG_ 458 BCmHuRoofLampHmiVrCmdAck 0;
BA_ "GenSigTimeoutTime_HU_Mid_X445" SG_ 458 BCmHuRoofLampHmiVrCmdAck 0;
BA_ "GenSigTimeoutMsg_IVI" SG_ 458 BCmHuRoofLampHmiVrCmdAck 0;
BA_ "GenSigTimeoutTime_IVI" SG_ 458 BCmHuRoofLampHmiVrCmdAck 0;
BA_ "GenSigTimeoutTime_HU_Mid_X451" SG_ 458 BCmHuPositionLampVrCmdAck 0;
BA_ "GenSigTimeoutTime_HU_High_X451" SG_ 458 BCmHuPositionLampVrCmdAck 0;
BA_ "GenSigTimeoutTime_HU_B" SG_ 458 BCmHuPositionLampVrCmdAck 0;
BA_ "GenSigTimeoutTime_HU_A" SG_ 458 BCmHuPositionLampVrCmdAck 0;
BA_ "GenSigTimeoutMsg_HU_Mid_X451" SG_ 458 BCmHuPositionLampVrCmdAck 0;
BA_ "GenSigTimeoutMsg_HU_High_X451" SG_ 458 BCmHuPositionLampVrCmdAck 0;
BA_ "GenSigTimeoutMsg_HU_B" SG_ 458 BCmHuPositionLampVrCmdAck 0;
BA_ "GenSigTimeoutMsg_HU_A" SG_ 458 BCmHuPositionLampVrCmdAck 0;
BA_ "GenSigSendType" SG_ 458 BCmHuPositionLampVrCmdAck 2;
BA_ "GenSigTimeoutMsg_HU_High_X445" SG_ 458 BCmHuPositionLampVrCmdAck 0;
BA_ "GenSigTimeoutMsg_HU_Mid_X445" SG_ 458 BCmHuPositionLampVrCmdAck 0;
BA_ "GenSigTimeoutTime_HU_High_X445" SG_ 458 BCmHuPositionLampVrCmdAck 0;
BA_ "GenSigTimeoutTime_HU_Mid_X445" SG_ 458 BCmHuPositionLampVrCmdAck 0;
BA_ "GenSigTimeoutMsg_IVI" SG_ 458 BCmHuPositionLampVrCmdAck 0;
BA_ "GenSigTimeoutTime_IVI" SG_ 458 BCmHuPositionLampVrCmdAck 0;
BA_ "GenSigTimeoutTime_HU_Mid_X451" SG_ 458 BCmHuORVMHmiVrCmdAck 0;
BA_ "GenSigTimeoutTime_HU_High_X451" SG_ 458 BCmHuORVMHmiVrCmdAck 0;
BA_ "GenSigTimeoutTime_HU_B" SG_ 458 BCmHuORVMHmiVrCmdAck 0;
BA_ "GenSigTimeoutTime_HU_A" SG_ 458 BCmHuORVMHmiVrCmdAck 0;
BA_ "GenSigTimeoutMsg_HU_Mid_X451" SG_ 458 BCmHuORVMHmiVrCmdAck 0;
BA_ "GenSigTimeoutMsg_HU_High_X451" SG_ 458 BCmHuORVMHmiVrCmdAck 0;
BA_ "GenSigTimeoutMsg_HU_B" SG_ 458 BCmHuORVMHmiVrCmdAck 0;
BA_ "GenSigTimeoutMsg_HU_A" SG_ 458 BCmHuORVMHmiVrCmdAck 0;
BA_ "GenSigSendType" SG_ 458 BCmHuORVMHmiVrCmdAck 2;
BA_ "GenSigTimeoutMsg_HU_High_X445" SG_ 458 BCmHuORVMHmiVrCmdAck 0;
BA_ "GenSigTimeoutMsg_HU_Mid_X445" SG_ 458 BCmHuORVMHmiVrCmdAck 0;
BA_ "GenSigTimeoutTime_HU_High_X445" SG_ 458 BCmHuORVMHmiVrCmdAck 0;
BA_ "GenSigTimeoutTime_HU_Mid_X445" SG_ 458 BCmHuORVMHmiVrCmdAck 0;
BA_ "GenSigTimeoutMsg_IVI" SG_ 458 BCmHuORVMHmiVrCmdAck 0;
BA_ "GenSigTimeoutTime_IVI" SG_ 458 BCmHuORVMHmiVrCmdAck 0;
BA_ "GenSigTimeoutTime_HU_Mid_X451" SG_ 458 BCmHuMoodLightVrCmdAck 0;
BA_ "GenSigTimeoutTime_HU_High_X451" SG_ 458 BCmHuMoodLightVrCmdAck 0;
BA_ "GenSigTimeoutTime_HU_B" SG_ 458 BCmHuMoodLightVrCmdAck 0;
BA_ "GenSigTimeoutTime_HU_A" SG_ 458 BCmHuMoodLightVrCmdAck 0;
BA_ "GenSigTimeoutMsg_HU_Mid_X451" SG_ 458 BCmHuMoodLightVrCmdAck 0;
BA_ "GenSigTimeoutMsg_HU_High_X451" SG_ 458 BCmHuMoodLightVrCmdAck 0;
BA_ "GenSigTimeoutMsg_HU_B" SG_ 458 BCmHuMoodLightVrCmdAck 0;
BA_ "GenSigTimeoutMsg_HU_A" SG_ 458 BCmHuMoodLightVrCmdAck 0;
BA_ "GenSigSendType" SG_ 458 BCmHuMoodLightVrCmdAck 2;
BA_ "GenSigTimeoutMsg_HU_High_X445" SG_ 458 BCmHuMoodLightVrCmdAck 0;
BA_ "GenSigTimeoutMsg_HU_Mid_X445" SG_ 458 BCmHuMoodLightVrCmdAck 0;
BA_ "GenSigTimeoutTime_HU_High_X445" SG_ 458 BCmHuMoodLightVrCmdAck 0;
BA_ "GenSigTimeoutTime_HU_Mid_X445" SG_ 458 BCmHuMoodLightVrCmdAck 0;
BA_ "GenSigTimeoutMsg_IVI" SG_ 458 BCmHuMoodLightVrCmdAck 0;
BA_ "GenSigTimeoutTime_IVI" SG_ 458 BCmHuMoodLightVrCmdAck 0;
BA_ "GenSigTimeoutTime_HU_Mid_X451" SG_ 458 BCmHuHazardLampVrCmdAck 0;
BA_ "GenSigTimeoutTime_HU_High_X451" SG_ 458 BCmHuHazardLampVrCmdAck 0;
BA_ "GenSigTimeoutTime_HU_B" SG_ 458 BCmHuHazardLampVrCmdAck 0;
BA_ "GenSigTimeoutTime_HU_A" SG_ 458 BCmHuHazardLampVrCmdAck 0;
BA_ "GenSigTimeoutMsg_HU_Mid_X451" SG_ 458 BCmHuHazardLampVrCmdAck 0;
BA_ "GenSigTimeoutMsg_HU_High_X451" SG_ 458 BCmHuHazardLampVrCmdAck 0;
BA_ "GenSigTimeoutMsg_HU_B" SG_ 458 BCmHuHazardLampVrCmdAck 0;
BA_ "GenSigTimeoutMsg_HU_A" SG_ 458 BCmHuHazardLampVrCmdAck 0;
BA_ "GenSigSendType" SG_ 458 BCmHuHazardLampVrCmdAck 2;
BA_ "GenSigTimeoutMsg_HU_High_X445" SG_ 458 BCmHuHazardLampVrCmdAck 0;
BA_ "GenSigTimeoutMsg_HU_Mid_X445" SG_ 458 BCmHuHazardLampVrCmdAck 0;
BA_ "GenSigTimeoutTime_HU_High_X445" SG_ 458 BCmHuHazardLampVrCmdAck 0;
BA_ "GenSigTimeoutTime_HU_Mid_X445" SG_ 458 BCmHuHazardLampVrCmdAck 0;
BA_ "GenSigTimeoutMsg_IVI" SG_ 458 BCmHuHazardLampVrCmdAck 0;
BA_ "GenSigTimeoutTime_IVI" SG_ 458 BCmHuHazardLampVrCmdAck 0;
BA_ "GenSigTimeoutTime_HU_Mid_X451" SG_ 458 BCmHuDRLVrCmdAck 0;
BA_ "GenSigTimeoutTime_HU_High_X451" SG_ 458 BCmHuDRLVrCmdAck 0;
BA_ "GenSigTimeoutTime_HU_B" SG_ 458 BCmHuDRLVrCmdAck 0;
BA_ "GenSigTimeoutTime_HU_A" SG_ 458 BCmHuDRLVrCmdAck 0;
BA_ "GenSigTimeoutMsg_HU_Mid_X451" SG_ 458 BCmHuDRLVrCmdAck 0;
BA_ "GenSigTimeoutMsg_HU_High_X451" SG_ 458 BCmHuDRLVrCmdAck 0;
BA_ "GenSigTimeoutMsg_HU_B" SG_ 458 BCmHuDRLVrCmdAck 0;
BA_ "GenSigTimeoutMsg_HU_A" SG_ 458 BCmHuDRLVrCmdAck 0;
BA_ "GenSigSendType" SG_ 458 BCmHuDRLVrCmdAck 2;
BA_ "GenSigTimeoutMsg_HU_High_X445" SG_ 458 BCmHuDRLVrCmdAck 0;
BA_ "GenSigTimeoutMsg_HU_Mid_X445" SG_ 458 BCmHuDRLVrCmdAck 0;
BA_ "GenSigTimeoutTime_HU_High_X445" SG_ 458 BCmHuDRLVrCmdAck 0;
BA_ "GenSigTimeoutTime_HU_Mid_X445" SG_ 458 BCmHuDRLVrCmdAck 0;
BA_ "GenSigTimeoutMsg_IVI" SG_ 458 BCmHuDRLVrCmdAck 0;
BA_ "GenSigTimeoutTime_IVI" SG_ 458 BCmHuDRLVrCmdAck 0;
BA_ "GenSigTimeoutTime_HU_Mid_X451" SG_ 458 BCmHuAmbientLightVrCmdAck 0;
BA_ "GenSigTimeoutTime_HU_High_X451" SG_ 458 BCmHuAmbientLightVrCmdAck 0;
BA_ "GenSigTimeoutTime_HU_B" SG_ 458 BCmHuAmbientLightVrCmdAck 0;
BA_ "GenSigTimeoutTime_HU_A" SG_ 458 BCmHuAmbientLightVrCmdAck 0;
BA_ "GenSigTimeoutMsg_HU_Mid_X451" SG_ 458 BCmHuAmbientLightVrCmdAck 0;
BA_ "GenSigTimeoutMsg_HU_High_X451" SG_ 458 BCmHuAmbientLightVrCmdAck 0;
BA_ "GenSigTimeoutMsg_HU_B" SG_ 458 BCmHuAmbientLightVrCmdAck 0;
BA_ "GenSigTimeoutMsg_HU_A" SG_ 458 BCmHuAmbientLightVrCmdAck 0;
BA_ "GenSigSendType" SG_ 458 BCmHuAmbientLightVrCmdAck 2;
BA_ "GenSigTimeoutMsg_HU_High_X445" SG_ 458 BCmHuAmbientLightVrCmdAck 0;
BA_ "GenSigTimeoutMsg_HU_Mid_X445" SG_ 458 BCmHuAmbientLightVrCmdAck 0;
BA_ "GenSigTimeoutTime_HU_High_X445" SG_ 458 BCmHuAmbientLightVrCmdAck 0;
BA_ "GenSigTimeoutTime_HU_Mid_X445" SG_ 458 BCmHuAmbientLightVrCmdAck 0;
BA_ "GenSigTimeoutMsg_IVI" SG_ 458 BCmHuAmbientLightVrCmdAck 0;
BA_ "GenSigTimeoutTime_IVI" SG_ 458 BCmHuAmbientLightVrCmdAck 0;
BA_ "GenSigTimeoutTime_HU_Mid_X451" SG_ 458 BCmHuTiltVrCmdAck 0;
BA_ "GenSigTimeoutTime_HU_High_X451" SG_ 458 BCmHuTiltVrCmdAck 0;
BA_ "GenSigTimeoutTime_HU_B" SG_ 458 BCmHuTiltVrCmdAck 0;
BA_ "GenSigTimeoutTime_HU_A" SG_ 458 BCmHuTiltVrCmdAck 0;
BA_ "GenSigTimeoutMsg_HU_Mid_X451" SG_ 458 BCmHuTiltVrCmdAck 0;
BA_ "GenSigTimeoutMsg_HU_High_X451" SG_ 458 BCmHuTiltVrCmdAck 0;
BA_ "GenSigTimeoutMsg_HU_B" SG_ 458 BCmHuTiltVrCmdAck 0;
BA_ "GenSigTimeoutMsg_HU_A" SG_ 458 BCmHuTiltVrCmdAck 0;
BA_ "GenSigSendType" SG_ 458 BCmHuTiltVrCmdAck 2;
BA_ "GenSigTimeoutMsg_HU_High_X445" SG_ 458 BCmHuTiltVrCmdAck 0;
BA_ "GenSigTimeoutMsg_HU_Mid_X445" SG_ 458 BCmHuTiltVrCmdAck 0;
BA_ "GenSigTimeoutTime_HU_High_X445" SG_ 458 BCmHuTiltVrCmdAck 0;
BA_ "GenSigTimeoutTime_HU_Mid_X445" SG_ 458 BCmHuTiltVrCmdAck 0;
BA_ "GenSigTimeoutMsg_IVI" SG_ 458 BCmHuTiltVrCmdAck 0;
BA_ "GenSigTimeoutTime_IVI" SG_ 458 BCmHuTiltVrCmdAck 0;
BA_ "GenSigTimeoutTime_HU_Mid_X451" SG_ 458 BCmHuSunShadeVrCmdAck 0;
BA_ "GenSigTimeoutTime_HU_High_X451" SG_ 458 BCmHuSunShadeVrCmdAck 0;
BA_ "GenSigTimeoutTime_HU_B" SG_ 458 BCmHuSunShadeVrCmdAck 0;
BA_ "GenSigTimeoutTime_HU_A" SG_ 458 BCmHuSunShadeVrCmdAck 0;
BA_ "GenSigTimeoutMsg_HU_Mid_X451" SG_ 458 BCmHuSunShadeVrCmdAck 0;
BA_ "GenSigTimeoutMsg_HU_High_X451" SG_ 458 BCmHuSunShadeVrCmdAck 0;
BA_ "GenSigTimeoutMsg_HU_B" SG_ 458 BCmHuSunShadeVrCmdAck 0;
BA_ "GenSigTimeoutMsg_HU_A" SG_ 458 BCmHuSunShadeVrCmdAck 0;
BA_ "GenSigSendType" SG_ 458 BCmHuSunShadeVrCmdAck 2;
BA_ "GenSigTimeoutMsg_HU_High_X445" SG_ 458 BCmHuSunShadeVrCmdAck 0;
BA_ "GenSigTimeoutMsg_HU_Mid_X445" SG_ 458 BCmHuSunShadeVrCmdAck 0;
BA_ "GenSigTimeoutTime_HU_High_X445" SG_ 458 BCmHuSunShadeVrCmdAck 0;
BA_ "GenSigTimeoutTime_HU_Mid_X445" SG_ 458 BCmHuSunShadeVrCmdAck 0;
BA_ "GenSigTimeoutMsg_IVI" SG_ 458 BCmHuSunShadeVrCmdAck 0;
BA_ "GenSigTimeoutTime_IVI" SG_ 458 BCmHuSunShadeVrCmdAck 0;
BA_ "GenSigTimeoutTime_HU_Mid_X451" SG_ 458 BCmHuSunRoofVrCmdAck 0;
BA_ "GenSigTimeoutTime_HU_High_X451" SG_ 458 BCmHuSunRoofVrCmdAck 0;
BA_ "GenSigTimeoutTime_HU_B" SG_ 458 BCmHuSunRoofVrCmdAck 0;
BA_ "GenSigTimeoutTime_HU_A" SG_ 458 BCmHuSunRoofVrCmdAck 0;
BA_ "GenSigTimeoutMsg_HU_Mid_X451" SG_ 458 BCmHuSunRoofVrCmdAck 0;
BA_ "GenSigTimeoutMsg_HU_High_X451" SG_ 458 BCmHuSunRoofVrCmdAck 0;
BA_ "GenSigTimeoutMsg_HU_B" SG_ 458 BCmHuSunRoofVrCmdAck 0;
BA_ "GenSigTimeoutMsg_HU_A" SG_ 458 BCmHuSunRoofVrCmdAck 0;
BA_ "GenSigSendType" SG_ 458 BCmHuSunRoofVrCmdAck 2;
BA_ "GenSigTimeoutMsg_HU_High_X445" SG_ 458 BCmHuSunRoofVrCmdAck 0;
BA_ "GenSigTimeoutMsg_HU_Mid_X445" SG_ 458 BCmHuSunRoofVrCmdAck 0;
BA_ "GenSigTimeoutTime_HU_High_X445" SG_ 458 BCmHuSunRoofVrCmdAck 0;
BA_ "GenSigTimeoutTime_HU_Mid_X445" SG_ 458 BCmHuSunRoofVrCmdAck 0;
BA_ "GenSigTimeoutMsg_IVI" SG_ 458 BCmHuSunRoofVrCmdAck 0;
BA_ "GenSigTimeoutTime_IVI" SG_ 458 BCmHuSunRoofVrCmdAck 0;
BA_ "GenSigSendType" SG_ 567 MRC_3 7;
BA_ "GenSigCycleTimeActive" SG_ 567 MRC_3 50;
BA_ "GenSigCycleTime" SG_ 567 MRC_3 50;
BA_ "GenSigSendType" SG_ 567 CRC_3 7;
BA_ "GenSigCycleTimeActive" SG_ 567 CRC_3 50;
BA_ "GenSigCycleTime" SG_ 567 CRC_3 50;
BA_ "GenSigStartValue" SG_ 567 APbState 7;
BA_ "GenSigSendType" SG_ 567 APbState 7;
BA_ "GenSigCycleTimeActive" SG_ 567 APbState 50;
BA_ "GenSigCycleTime" SG_ 567 APbState 50;
BA_ "GenSigTimeoutTime_HU_Mid_X451" SG_ 960 DateTimeYear 2500;
BA_ "GenSigTimeoutTime_HU_High_X451" SG_ 960 DateTimeYear 2500;
BA_ "GenSigTimeoutTime_HU_B" SG_ 960 DateTimeYear 2500;
BA_ "GenSigTimeoutTime_HU_A" SG_ 960 DateTimeYear 2500;
BA_ "GenSigTimeoutMsg_HU_Mid_X451" SG_ 960 DateTimeYear 2500;
BA_ "GenSigTimeoutMsg_HU_High_X451" SG_ 960 DateTimeYear 2500;
BA_ "GenSigTimeoutMsg_HU_B" SG_ 960 DateTimeYear 2500;
BA_ "GenSigTimeoutMsg_HU_A" SG_ 960 DateTimeYear 2500;
BA_ "GenSigSendType" SG_ 960 DateTimeYear 7;
BA_ "GenSigCycleTimeActive" SG_ 960 DateTimeYear 500;
BA_ "GenSigCycleTime" SG_ 960 DateTimeYear 500;
BA_ "GenSigTimeoutMsg_HU_High_X445" SG_ 960 DateTimeYear 2500;
BA_ "GenSigTimeoutMsg_HU_Mid_X445" SG_ 960 DateTimeYear 2500;
BA_ "GenSigTimeoutTime_HU_High_X445" SG_ 960 DateTimeYear 2500;
BA_ "GenSigTimeoutTime_HU_Mid_X445" SG_ 960 DateTimeYear 2500;
BA_ "GenSigTimeoutMsg_IVI" SG_ 960 DateTimeYear 2500;
BA_ "GenSigTimeoutTime_IVI" SG_ 960 DateTimeYear 2500;
BA_ "GenSigTimeoutTime_HU_Mid_X451" SG_ 960 DateTimeStatus 2500;
BA_ "GenSigTimeoutTime_HU_High_X451" SG_ 960 DateTimeStatus 2500;
BA_ "GenSigTimeoutTime_HU_B" SG_ 960 DateTimeStatus 2500;
BA_ "GenSigTimeoutTime_HU_A" SG_ 960 DateTimeStatus 2500;
BA_ "GenSigTimeoutMsg_HU_Mid_X451" SG_ 960 DateTimeStatus 2500;
BA_ "GenSigTimeoutMsg_HU_High_X451" SG_ 960 DateTimeStatus 2500;
BA_ "GenSigTimeoutMsg_HU_B" SG_ 960 DateTimeStatus 2500;
BA_ "GenSigTimeoutMsg_HU_A" SG_ 960 DateTimeStatus 2500;
BA_ "GenSigSendType" SG_ 960 DateTimeStatus 7;
BA_ "GenSigCycleTimeActive" SG_ 960 DateTimeStatus 500;
BA_ "GenSigCycleTime" SG_ 960 DateTimeStatus 500;
BA_ "GenSigTimeoutMsg_HU_High_X445" SG_ 960 DateTimeStatus 2500;
BA_ "GenSigTimeoutMsg_HU_Mid_X445" SG_ 960 DateTimeStatus 2500;
BA_ "GenSigTimeoutTime_HU_High_X445" SG_ 960 DateTimeStatus 2500;
BA_ "GenSigTimeoutTime_HU_Mid_X445" SG_ 960 DateTimeStatus 2500;
BA_ "GenSigTimeoutMsg_IVI" SG_ 960 DateTimeStatus 2500;
BA_ "GenSigTimeoutTime_IVI" SG_ 960 DateTimeStatus 2500;
BA_ "GenSigTimeoutTime_HU_Mid_X451" SG_ 960 DateTimeSeconds 2500;
BA_ "GenSigTimeoutTime_HU_High_X451" SG_ 960 DateTimeSeconds 2500;
BA_ "GenSigTimeoutTime_HU_B" SG_ 960 DateTimeSeconds 2500;
BA_ "GenSigTimeoutTime_HU_A" SG_ 960 DateTimeSeconds 2500;
BA_ "GenSigTimeoutMsg_HU_Mid_X451" SG_ 960 DateTimeSeconds 2500;
BA_ "GenSigTimeoutMsg_HU_High_X451" SG_ 960 DateTimeSeconds 2500;
BA_ "GenSigTimeoutMsg_HU_B" SG_ 960 DateTimeSeconds 2500;
BA_ "GenSigTimeoutMsg_HU_A" SG_ 960 DateTimeSeconds 2500;
BA_ "GenSigSendType" SG_ 960 DateTimeSeconds 7;
BA_ "GenSigCycleTimeActive" SG_ 960 DateTimeSeconds 500;
BA_ "GenSigCycleTime" SG_ 960 DateTimeSeconds 500;
BA_ "GenSigTimeoutMsg_HU_High_X445" SG_ 960 DateTimeSeconds 2500;
BA_ "GenSigTimeoutMsg_HU_Mid_X445" SG_ 960 DateTimeSeconds 2500;
BA_ "GenSigTimeoutTime_HU_High_X445" SG_ 960 DateTimeSeconds 2500;
BA_ "GenSigTimeoutTime_HU_Mid_X445" SG_ 960 DateTimeSeconds 2500;
BA_ "GenSigTimeoutMsg_IVI" SG_ 960 DateTimeSeconds 2500;
BA_ "GenSigTimeoutTime_IVI" SG_ 960 DateTimeSeconds 2500;
BA_ "GenSigTimeoutTime_HU_Mid_X451" SG_ 960 DateTimeMonth 2500;
BA_ "GenSigTimeoutTime_HU_High_X451" SG_ 960 DateTimeMonth 2500;
BA_ "GenSigTimeoutTime_HU_B" SG_ 960 DateTimeMonth 2500;
BA_ "GenSigTimeoutTime_HU_A" SG_ 960 DateTimeMonth 2500;
BA_ "GenSigTimeoutMsg_HU_Mid_X451" SG_ 960 DateTimeMonth 2500;
BA_ "GenSigTimeoutMsg_HU_High_X451" SG_ 960 DateTimeMonth 2500;
BA_ "GenSigTimeoutMsg_HU_B" SG_ 960 DateTimeMonth 2500;
BA_ "GenSigTimeoutMsg_HU_A" SG_ 960 DateTimeMonth 2500;
BA_ "GenSigStartValue" SG_ 960 DateTimeMonth 1;
BA_ "GenSigSendType" SG_ 960 DateTimeMonth 7;
BA_ "GenSigCycleTimeActive" SG_ 960 DateTimeMonth 500;
BA_ "GenSigCycleTime" SG_ 960 DateTimeMonth 500;
BA_ "GenSigTimeoutMsg_HU_High_X445" SG_ 960 DateTimeMonth 2500;
BA_ "GenSigTimeoutMsg_HU_Mid_X445" SG_ 960 DateTimeMonth 2500;
BA_ "GenSigTimeoutTime_HU_High_X445" SG_ 960 DateTimeMonth 2500;
BA_ "GenSigTimeoutTime_HU_Mid_X445" SG_ 960 DateTimeMonth 2500;
BA_ "GenSigTimeoutMsg_IVI" SG_ 960 DateTimeMonth 2500;
BA_ "GenSigTimeoutTime_IVI" SG_ 960 DateTimeMonth 2500;
BA_ "GenSigTimeoutTime_HU_Mid_X451" SG_ 960 DateTimeMinute 2500;
BA_ "GenSigTimeoutTime_HU_High_X451" SG_ 960 DateTimeMinute 2500;
BA_ "GenSigTimeoutTime_HU_B" SG_ 960 DateTimeMinute 2500;
BA_ "GenSigTimeoutTime_HU_A" SG_ 960 DateTimeMinute 2500;
BA_ "GenSigTimeoutMsg_HU_Mid_X451" SG_ 960 DateTimeMinute 2500;
BA_ "GenSigTimeoutMsg_HU_High_X451" SG_ 960 DateTimeMinute 2500;
BA_ "GenSigTimeoutMsg_HU_B" SG_ 960 DateTimeMinute 2500;
BA_ "GenSigTimeoutMsg_HU_A" SG_ 960 DateTimeMinute 2500;
BA_ "GenSigSendType" SG_ 960 DateTimeMinute 7;
BA_ "GenSigCycleTimeActive" SG_ 960 DateTimeMinute 500;
BA_ "GenSigCycleTime" SG_ 960 DateTimeMinute 500;
BA_ "GenSigTimeoutMsg_HU_High_X445" SG_ 960 DateTimeMinute 2500;
BA_ "GenSigTimeoutMsg_HU_Mid_X445" SG_ 960 DateTimeMinute 2500;
BA_ "GenSigTimeoutTime_HU_High_X445" SG_ 960 DateTimeMinute 2500;
BA_ "GenSigTimeoutTime_HU_Mid_X445" SG_ 960 DateTimeMinute 2500;
BA_ "GenSigTimeoutMsg_IVI" SG_ 960 DateTimeMinute 2500;
BA_ "GenSigTimeoutTime_IVI" SG_ 960 DateTimeMinute 2500;
BA_ "GenSigTimeoutTime_HU_Mid_X451" SG_ 960 DateTimeHour 2500;
BA_ "GenSigTimeoutTime_HU_High_X451" SG_ 960 DateTimeHour 2500;
BA_ "GenSigTimeoutTime_HU_B" SG_ 960 DateTimeHour 2500;
BA_ "GenSigTimeoutTime_HU_A" SG_ 960 DateTimeHour 2500;
BA_ "GenSigTimeoutMsg_HU_Mid_X451" SG_ 960 DateTimeHour 2500;
BA_ "GenSigTimeoutMsg_HU_High_X451" SG_ 960 DateTimeHour 2500;
BA_ "GenSigTimeoutMsg_HU_B" SG_ 960 DateTimeHour 2500;
BA_ "GenSigTimeoutMsg_HU_A" SG_ 960 DateTimeHour 2500;
BA_ "GenSigSendType" SG_ 960 DateTimeHour 7;
BA_ "GenSigCycleTimeActive" SG_ 960 DateTimeHour 500;
BA_ "GenSigCycleTime" SG_ 960 DateTimeHour 500;
BA_ "GenSigTimeoutMsg_HU_High_X445" SG_ 960 DateTimeHour 2500;
BA_ "GenSigTimeoutMsg_HU_Mid_X445" SG_ 960 DateTimeHour 2500;
BA_ "GenSigTimeoutTime_HU_High_X445" SG_ 960 DateTimeHour 2500;
BA_ "GenSigTimeoutTime_HU_Mid_X445" SG_ 960 DateTimeHour 2500;
BA_ "GenSigTimeoutMsg_IVI" SG_ 960 DateTimeHour 2500;
BA_ "GenSigTimeoutTime_IVI" SG_ 960 DateTimeHour 2500;
BA_ "GenSigTimeoutTime_HU_Mid_X451" SG_ 960 DateTimeDay 2500;
BA_ "GenSigTimeoutTime_HU_High_X451" SG_ 960 DateTimeDay 2500;
BA_ "GenSigTimeoutTime_HU_B" SG_ 960 DateTimeDay 2500;
BA_ "GenSigTimeoutTime_HU_A" SG_ 960 DateTimeDay 2500;
BA_ "GenSigTimeoutMsg_HU_Mid_X451" SG_ 960 DateTimeDay 2500;
BA_ "GenSigTimeoutMsg_HU_High_X451" SG_ 960 DateTimeDay 2500;
BA_ "GenSigTimeoutMsg_HU_B" SG_ 960 DateTimeDay 2500;
BA_ "GenSigTimeoutMsg_HU_A" SG_ 960 DateTimeDay 2500;
BA_ "GenSigStartValue" SG_ 960 DateTimeDay 1;
BA_ "GenSigSendType" SG_ 960 DateTimeDay 7;
BA_ "GenSigCycleTimeActive" SG_ 960 DateTimeDay 500;
BA_ "GenSigCycleTime" SG_ 960 DateTimeDay 500;
BA_ "GenSigTimeoutMsg_HU_High_X445" SG_ 960 DateTimeDay 2500;
BA_ "GenSigTimeoutMsg_HU_Mid_X445" SG_ 960 DateTimeDay 2500;
BA_ "GenSigTimeoutTime_HU_High_X445" SG_ 960 DateTimeDay 2500;
BA_ "GenSigTimeoutTime_HU_Mid_X445" SG_ 960 DateTimeDay 2500;
BA_ "GenSigTimeoutMsg_IVI" SG_ 960 DateTimeDay 2500;
BA_ "GenSigTimeoutTime_IVI" SG_ 960 DateTimeDay 2500;
BA_ "GenSigSendType" SG_ 582 SILTelltaleVcuStatus 7;
BA_ "GenSigCycleTimeActive" SG_ 582 SILTelltaleVcuStatus 100;
BA_ "GenSigCycleTime" SG_ 582 SILTelltaleVcuStatus 100;
BA_ "GenSigSendType" SG_ 582 SILTelltaleVcu 7;
BA_ "GenSigCycleTimeActive" SG_ 582 SILTelltaleVcu 100;
BA_ "GenSigCycleTime" SG_ 582 SILTelltaleVcu 100;
BA_ "GenSigSendType" SG_ 582 DcdcRealInputVoltage 7;
BA_ "GenSigCycleTimeActive" SG_ 582 DcdcRealInputVoltage 100;
BA_ "GenSigCycleTime" SG_ 582 DcdcRealInputVoltage 100;
BA_ "GenSigSendType" SG_ 582 HvBattPwrConsmp 7;
BA_ "GenSigCycleTimeActive" SG_ 582 HvBattPwrConsmp 100;
BA_ "GenSigCycleTime" SG_ 582 HvBattPwrConsmp 100;
BA_ "GenSigSendType" SG_ 582 AvgEnergyConsmpTripBStatus 7;
BA_ "GenSigCycleTimeActive" SG_ 582 AvgEnergyConsmpTripBStatus 100;
BA_ "GenSigCycleTime" SG_ 582 AvgEnergyConsmpTripBStatus 100;
BA_ "GenSigSendType" SG_ 582 AvgEnergyConsmpTripAStatus 7;
BA_ "GenSigCycleTimeActive" SG_ 582 AvgEnergyConsmpTripAStatus 100;
BA_ "GenSigCycleTime" SG_ 582 AvgEnergyConsmpTripAStatus 100;
BA_ "GenSigSendType" SG_ 582 AvgEnergyConsmpTripB 7;
BA_ "GenSigCycleTimeActive" SG_ 582 AvgEnergyConsmpTripB 100;
BA_ "GenSigCycleTime" SG_ 582 AvgEnergyConsmpTripB 100;
BA_ "GenSigSendType" SG_ 582 AvgEnergyConsmpTripA 7;
BA_ "GenSigCycleTimeActive" SG_ 582 AvgEnergyConsmpTripA 100;
BA_ "GenSigCycleTime" SG_ 582 AvgEnergyConsmpTripA 100;
BA_ "GenSigSendType" SG_ 582 InstPwrConsumpStatus 7;
BA_ "GenSigCycleTimeActive" SG_ 582 InstPwrConsumpStatus 100;
BA_ "GenSigCycleTime" SG_ 582 InstPwrConsumpStatus 100;
BA_ "GenSigStartValue" SG_ 582 InstPwrConsump 100;
BA_ "GenSigSendType" SG_ 582 InstPwrConsump 7;
BA_ "GenSigCycleTimeActive" SG_ 582 InstPwrConsump 100;
BA_ "GenSigCycleTime" SG_ 582 InstPwrConsump 100;
BA_ "GenSigSendType" SG_ 719 ComfortState 7;
BA_ "GenSigCycleTimeActive" SG_ 719 ComfortState 100;
BA_ "GenSigCycleTime" SG_ 719 ComfortState 100;
BA_ "GenSigSendType" SG_ 719 ComfortStateStatus 7;
BA_ "GenSigCycleTimeActive" SG_ 719 ComfortStateStatus 100;
BA_ "GenSigCycleTime" SG_ 719 ComfortStateStatus 100;
BA_ "GenSigTimeoutTime_HU_Mid_X451" SG_ 493 CarAnniversary 0;
BA_ "GenSigTimeoutTime_HU_High_X451" SG_ 493 CarAnniversary 0;
BA_ "GenSigTimeoutTime_HU_B" SG_ 493 CarAnniversary 0;
BA_ "GenSigTimeoutTime_HU_A" SG_ 493 CarAnniversary 0;
BA_ "GenSigTimeoutMsg_HU_Mid_X451" SG_ 493 CarAnniversary 0;
BA_ "GenSigTimeoutMsg_HU_High_X451" SG_ 493 CarAnniversary 0;
BA_ "GenSigTimeoutMsg_HU_B" SG_ 493 CarAnniversary 0;
BA_ "GenSigTimeoutMsg_HU_A" SG_ 493 CarAnniversary 0;
BA_ "GenSigSendType" SG_ 493 CarAnniversary 2;
BA_ "GenSigTimeoutMsg_HU_High_X445" SG_ 493 CarAnniversary 0;
BA_ "GenSigTimeoutMsg_HU_Mid_X445" SG_ 493 CarAnniversary 0;
BA_ "GenSigTimeoutTime_HU_High_X445" SG_ 493 CarAnniversary 0;
BA_ "GenSigTimeoutTime_HU_Mid_X445" SG_ 493 CarAnniversary 0;
BA_ "GenSigTimeoutMsg_IVI" SG_ 493 CarAnniversary 0;
BA_ "GenSigTimeoutTime_IVI" SG_ 493 CarAnniversary 0;
BA_ "GenSigTimeoutTime_HU_Mid_X451" SG_ 493 OwnersAnniversary 0;
BA_ "GenSigTimeoutTime_HU_High_X451" SG_ 493 OwnersAnniversary 0;
BA_ "GenSigTimeoutTime_HU_B" SG_ 493 OwnersAnniversary 0;
BA_ "GenSigTimeoutTime_HU_A" SG_ 493 OwnersAnniversary 0;
BA_ "GenSigTimeoutMsg_HU_Mid_X451" SG_ 493 OwnersAnniversary 0;
BA_ "GenSigTimeoutMsg_HU_High_X451" SG_ 493 OwnersAnniversary 0;
BA_ "GenSigTimeoutMsg_HU_B" SG_ 493 OwnersAnniversary 0;
BA_ "GenSigTimeoutMsg_HU_A" SG_ 493 OwnersAnniversary 0;
BA_ "GenSigSendType" SG_ 493 OwnersAnniversary 2;
BA_ "GenSigTimeoutMsg_HU_High_X445" SG_ 493 OwnersAnniversary 0;
BA_ "GenSigTimeoutMsg_HU_Mid_X445" SG_ 493 OwnersAnniversary 0;
BA_ "GenSigTimeoutTime_HU_High_X445" SG_ 493 OwnersAnniversary 0;
BA_ "GenSigTimeoutTime_HU_Mid_X445" SG_ 493 OwnersAnniversary 0;
BA_ "GenSigTimeoutMsg_IVI" SG_ 493 OwnersAnniversary 0;
BA_ "GenSigTimeoutTime_IVI" SG_ 493 OwnersAnniversary 0;
BA_ "GenSigTimeoutTime_HU_Mid_X451" SG_ 493 OwnersBirthday 0;
BA_ "GenSigTimeoutTime_HU_High_X451" SG_ 493 OwnersBirthday 0;
BA_ "GenSigTimeoutTime_HU_B" SG_ 493 OwnersBirthday 0;
BA_ "GenSigTimeoutTime_HU_A" SG_ 493 OwnersBirthday 0;
BA_ "GenSigTimeoutMsg_HU_Mid_X451" SG_ 493 OwnersBirthday 0;
BA_ "GenSigTimeoutMsg_HU_High_X451" SG_ 493 OwnersBirthday 0;
BA_ "GenSigTimeoutMsg_HU_B" SG_ 493 OwnersBirthday 0;
BA_ "GenSigTimeoutMsg_HU_A" SG_ 493 OwnersBirthday 0;
BA_ "GenSigSendType" SG_ 493 OwnersBirthday 2;
BA_ "GenSigTimeoutMsg_HU_High_X445" SG_ 493 OwnersBirthday 0;
BA_ "GenSigTimeoutMsg_HU_Mid_X445" SG_ 493 OwnersBirthday 0;
BA_ "GenSigTimeoutTime_HU_High_X445" SG_ 493 OwnersBirthday 0;
BA_ "GenSigTimeoutTime_HU_Mid_X445" SG_ 493 OwnersBirthday 0;
BA_ "GenSigTimeoutMsg_IVI" SG_ 493 OwnersBirthday 0;
BA_ "GenSigTimeoutTime_IVI" SG_ 493 OwnersBirthday 0;
BA_ "GenSigSendType" SG_ 581 HvChargeTypeStatus_VCAN 7;
BA_ "GenSigCycleTimeActive" SG_ 581 HvChargeTypeStatus_VCAN 100;
BA_ "GenSigCycleTime" SG_ 581 HvChargeTypeStatus_VCAN 100;
BA_ "GenSigSendType" SG_ 581 HvChargeType_VCAN 7;
BA_ "GenSigCycleTimeActive" SG_ 581 HvChargeType_VCAN 100;
BA_ "GenSigCycleTime" SG_ 581 HvChargeType_VCAN 100;
BA_ "GenSigSendType" SG_ 581 HvChargingStateStatus_VCAN 7;
BA_ "GenSigCycleTimeActive" SG_ 581 HvChargingStateStatus_VCAN 100;
BA_ "GenSigCycleTime" SG_ 581 HvChargingStateStatus_VCAN 100;
BA_ "GenSigSendType" SG_ 581 HvChargingState_VCAN 7;
BA_ "GenSigCycleTimeActive" SG_ 581 HvChargingState_VCAN 100;
BA_ "GenSigCycleTime" SG_ 581 HvChargingState_VCAN 100;
BA_ "GenSigSendType" SG_ 581 TimetoChargeHVMintsStatus_VCAN 7;
BA_ "GenSigCycleTimeActive" SG_ 581 TimetoChargeHVMintsStatus_VCAN 100;
BA_ "GenSigCycleTime" SG_ 581 TimetoChargeHVMintsStatus_VCAN 100;
BA_ "GenSigSendType" SG_ 581 TimetoChargeHVMints_VCAN 7;
BA_ "GenSigCycleTimeActive" SG_ 581 TimetoChargeHVMints_VCAN 100;
BA_ "GenSigCycleTime" SG_ 581 TimetoChargeHVMints_VCAN 100;
BA_ "GenSigSendType" SG_ 581 TimetoChargeHVHoursStatus_VCAN 7;
BA_ "GenSigCycleTimeActive" SG_ 581 TimetoChargeHVHoursStatus_VCAN 100;
BA_ "GenSigCycleTime" SG_ 581 TimetoChargeHVHoursStatus_VCAN 100;
BA_ "GenSigSendType" SG_ 581 TimetoChargeHVHours_VCAN 7;
BA_ "GenSigCycleTimeActive" SG_ 581 TimetoChargeHVHours_VCAN 100;
BA_ "GenSigCycleTime" SG_ 581 TimetoChargeHVHours_VCAN 100;
BA_ "GenSigSendType" SG_ 581 CoolingPwrFdbkVal 7;
BA_ "GenSigCycleTimeActive" SG_ 581 CoolingPwrFdbkVal 100;
BA_ "GenSigCycleTime" SG_ 581 CoolingPwrFdbkVal 100;
BA_ "GenSigSendType" SG_ 581 HeatingPwrFdbkVal 7;
BA_ "GenSigCycleTimeActive" SG_ 581 HeatingPwrFdbkVal 100;
BA_ "GenSigCycleTime" SG_ 581 HeatingPwrFdbkVal 100;
BA_ "GenSigSendType" SG_ 581 CabinCoolingSolValveStateStatus 7;
BA_ "GenSigCycleTimeActive" SG_ 581 CabinCoolingSolValveStateStatus 100;
BA_ "GenSigCycleTime" SG_ 581 CabinCoolingSolValveStateStatus 100;
BA_ "GenSigSendType" SG_ 581 CabinCoolingSolValveState 7;
BA_ "GenSigCycleTimeActive" SG_ 581 CabinCoolingSolValveState 100;
BA_ "GenSigCycleTime" SG_ 581 CabinCoolingSolValveState 100;
BA_ "GenSigSendType" SG_ 581 LowHVBatteryChargeStatus_VCAN 7;
BA_ "GenSigCycleTimeActive" SG_ 581 LowHVBatteryChargeStatus_VCAN 100;
BA_ "GenSigCycleTime" SG_ 581 LowHVBatteryChargeStatus_VCAN 100;
BA_ "GenSigSendType" SG_ 581 LowHVBatteryCharge_VCAN 7;
BA_ "GenSigCycleTimeActive" SG_ 581 LowHVBatteryCharge_VCAN 100;
BA_ "GenSigCycleTime" SG_ 581 LowHVBatteryCharge_VCAN 100;
BA_ "GenSigSendType" SG_ 581 LowLVBatteryChargeStatus_VCAN 7;
BA_ "GenSigCycleTimeActive" SG_ 581 LowLVBatteryChargeStatus_VCAN 100;
BA_ "GenSigCycleTime" SG_ 581 LowLVBatteryChargeStatus_VCAN 100;
BA_ "GenSigSendType" SG_ 581 LowLVBatteryCharge_VCAN 7;
BA_ "GenSigCycleTimeActive" SG_ 581 LowLVBatteryCharge_VCAN 100;
BA_ "GenSigCycleTime" SG_ 581 LowLVBatteryCharge_VCAN 100;
BA_ "GenSigSendType" SG_ 581 HvAmpHrStatus 7;
BA_ "GenSigCycleTimeActive" SG_ 581 HvAmpHrStatus 100;
BA_ "GenSigCycleTime" SG_ 581 HvAmpHrStatus 100;
BA_ "GenSigSendType" SG_ 581 HvAmpHr 7;
BA_ "GenSigCycleTimeActive" SG_ 581 HvAmpHr 100;
BA_ "GenSigCycleTime" SG_ 581 HvAmpHr 100;
BA_ "GenSigSendType" SG_ 1330 SolarLoad 7;
BA_ "GenSigCycleTimeActive" SG_ 1330 SolarLoad 100;
BA_ "GenSigCycleTime" SG_ 1330 SolarLoad 100;
BA_ "GenSigSendType" SG_ 1329 SolarLoad 7;
BA_ "GenSigCycleTimeActive" SG_ 1329 SolarLoad 100;
BA_ "GenSigCycleTime" SG_ 1329 SolarLoad 100;
BA_ "GenSigSendType" SG_ 724 HeatingPwrValStatus 7;
BA_ "GenSigCycleTimeActive" SG_ 724 HeatingPwrValStatus 100;
BA_ "GenSigCycleTime" SG_ 724 HeatingPwrValStatus 100;
BA_ "GenSigSendType" SG_ 724 HeatingPwrVal 7;
BA_ "GenSigCycleTimeActive" SG_ 724 HeatingPwrVal 100;
BA_ "GenSigCycleTime" SG_ 724 HeatingPwrVal 100;
BA_ "GenSigStartValue" SG_ 724 CoolingPwrValStatus 2;
BA_ "GenSigSendType" SG_ 724 CoolingPwrValStatus 7;
BA_ "GenSigCycleTimeActive" SG_ 724 CoolingPwrValStatus 100;
BA_ "GenSigCycleTime" SG_ 724 CoolingPwrValStatus 100;
BA_ "GenSigSendType" SG_ 724 CoolingPwrVal 7;
BA_ "GenSigCycleTimeActive" SG_ 724 CoolingPwrVal 100;
BA_ "GenSigCycleTime" SG_ 724 CoolingPwrVal 100;
BA_ "GenSigSendType" SG_ 724 AcReqNew 7;
BA_ "GenSigCycleTimeActive" SG_ 724 AcReqNew 100;
BA_ "GenSigCycleTime" SG_ 724 AcReqNew 100;
BA_ "GenSigSendType" SG_ 408 MSG_CNT_4 7;
BA_ "GenSigCycleTimeActive" SG_ 408 MSG_CNT_4 20;
BA_ "GenSigCycleTime" SG_ 408 MSG_CNT_4 20;
BA_ "GenSigSendType" SG_ 408 CRC_4 7;
BA_ "GenSigCycleTimeActive" SG_ 408 CRC_4 20;
BA_ "GenSigCycleTime" SG_ 408 CRC_4 20;
BA_ "GenSigSendType" SG_ 408 ICDispSpeedSigStatus 7;
BA_ "GenSigCycleTimeActive" SG_ 408 ICDispSpeedSigStatus 20;
BA_ "GenSigCycleTime" SG_ 408 ICDispSpeedSigStatus 20;
BA_ "GenSigSendType" SG_ 408 ICDispSpeedSig 7;
BA_ "GenSigCycleTimeActive" SG_ 408 ICDispSpeedSig 20;
BA_ "GenSigCycleTime" SG_ 408 ICDispSpeedSig 20;
BA_ "GenSigSendType" SG_ 738 TurnInputSwStateInfoStatus 7;
BA_ "GenSigCycleTimeActive" SG_ 738 TurnInputSwStateInfoStatus 100;
BA_ "GenSigCycleTime" SG_ 738 TurnInputSwStateInfoStatus 100;
BA_ "GenSigSendType" SG_ 738 TurnInputSwStateInfo 7;
BA_ "GenSigCycleTimeActive" SG_ 738 TurnInputSwStateInfo 100;
BA_ "GenSigCycleTime" SG_ 738 TurnInputSwStateInfo 100;
BA_ "GenSigSendType" SG_ 738 RemoteUsecaseStateStatus 7;
BA_ "GenSigCycleTimeActive" SG_ 738 RemoteUsecaseStateStatus 100;
BA_ "GenSigCycleTime" SG_ 738 RemoteUsecaseStateStatus 100;
BA_ "GenSigStartValue" SG_ 738 RemoteUsecaseState 1;
BA_ "GenSigSendType" SG_ 738 RemoteUsecaseState 7;
BA_ "GenSigCycleTimeActive" SG_ 738 RemoteUsecaseState 100;
BA_ "GenSigCycleTime" SG_ 738 RemoteUsecaseState 100;
BA_ "GenSigSendType" SG_ 738 HornStateStatus 7;
BA_ "GenSigCycleTimeActive" SG_ 738 HornStateStatus 100;
BA_ "GenSigCycleTime" SG_ 738 HornStateStatus 100;
BA_ "GenSigSendType" SG_ 738 HornState 7;
BA_ "GenSigCycleTimeActive" SG_ 738 HornState 100;
BA_ "GenSigCycleTime" SG_ 738 HornState 100;
BA_ "GenSigSendType" SG_ 738 ForcePanicStatus 7;
BA_ "GenSigCycleTimeActive" SG_ 738 ForcePanicStatus 100;
BA_ "GenSigCycleTime" SG_ 738 ForcePanicStatus 100;
BA_ "GenSigSendType" SG_ 738 ApprochLampStateStatus 7;
BA_ "GenSigCycleTimeActive" SG_ 738 ApprochLampStateStatus 100;
BA_ "GenSigCycleTime" SG_ 738 ApprochLampStateStatus 100;
BA_ "GenSigSendType" SG_ 738 ApprochLampState 7;
BA_ "GenSigCycleTimeActive" SG_ 738 ApprochLampState 100;
BA_ "GenSigCycleTime" SG_ 738 ApprochLampState 100;
BA_ "GenSigSendType" SG_ 738 LowBeamTellTaleStatus 7;
BA_ "GenSigCycleTimeActive" SG_ 738 LowBeamTellTaleStatus 100;
BA_ "GenSigCycleTime" SG_ 738 LowBeamTellTaleStatus 100;
BA_ "GenSigSendType" SG_ 738 LowBeamTellTale 7;
BA_ "GenSigCycleTimeActive" SG_ 738 LowBeamTellTale 100;
BA_ "GenSigCycleTime" SG_ 738 LowBeamTellTale 100;
BA_ "GenSigSendType" SG_ 738 IntrusionInfoStateStatus 7;
BA_ "GenSigCycleTimeActive" SG_ 738 IntrusionInfoStateStatus 100;
BA_ "GenSigCycleTime" SG_ 738 IntrusionInfoStateStatus 100;
BA_ "GenSigSendType" SG_ 738 IntrusionInfoState 7;
BA_ "GenSigCycleTimeActive" SG_ 738 IntrusionInfoState 100;
BA_ "GenSigCycleTime" SG_ 738 IntrusionInfoState 100;
BA_ "GenSigSendType" SG_ 738 HazardLampState 7;
BA_ "GenSigCycleTimeActive" SG_ 738 HazardLampState 100;
BA_ "GenSigCycleTime" SG_ 738 HazardLampState 100;
BA_ "GenSigSendType" SG_ 738 HazardLampStateStatus 7;
BA_ "GenSigCycleTimeActive" SG_ 738 HazardLampStateStatus 100;
BA_ "GenSigCycleTime" SG_ 738 HazardLampStateStatus 100;
BA_ "GenSigSendType" SG_ 738 VehicleSecured 7;
BA_ "GenSigCycleTimeActive" SG_ 738 VehicleSecured 100;
BA_ "GenSigCycleTime" SG_ 738 VehicleSecured 100;
BA_ "GenSigSendType" SG_ 738 VehicleSecuredStatus 7;
BA_ "GenSigCycleTimeActive" SG_ 738 VehicleSecuredStatus 100;
BA_ "GenSigCycleTime" SG_ 738 VehicleSecuredStatus 100;
BA_ "GenSigTimeoutTime_HU_Mid_X451" SG_ 495 RemoteHornCmdStatus 0;
BA_ "GenSigTimeoutTime_HU_High_X451" SG_ 495 RemoteHornCmdStatus 0;
BA_ "GenSigTimeoutTime_HU_B" SG_ 495 RemoteHornCmdStatus 0;
BA_ "GenSigTimeoutTime_HU_A" SG_ 495 RemoteHornCmdStatus 0;
BA_ "GenSigTimeoutMsg_HU_Mid_X451" SG_ 495 RemoteHornCmdStatus 0;
BA_ "GenSigTimeoutMsg_HU_High_X451" SG_ 495 RemoteHornCmdStatus 0;
BA_ "GenSigTimeoutMsg_HU_B" SG_ 495 RemoteHornCmdStatus 0;
BA_ "GenSigTimeoutMsg_HU_A" SG_ 495 RemoteHornCmdStatus 0;
BA_ "GenSigStartValue" SG_ 495 RemoteHornCmdStatus 1;
BA_ "GenSigSendType" SG_ 495 RemoteHornCmdStatus 2;
BA_ "GenSigTimeoutMsg_HU_High_X445" SG_ 495 RemoteHornCmdStatus 0;
BA_ "GenSigTimeoutMsg_HU_Mid_X445" SG_ 495 RemoteHornCmdStatus 0;
BA_ "GenSigTimeoutTime_HU_High_X445" SG_ 495 RemoteHornCmdStatus 0;
BA_ "GenSigTimeoutTime_HU_Mid_X445" SG_ 495 RemoteHornCmdStatus 0;
BA_ "GenSigTimeoutMsg_IVI" SG_ 495 RemoteHornCmdStatus 0;
BA_ "GenSigTimeoutTime_IVI" SG_ 495 RemoteHornCmdStatus 0;
BA_ "GenSigTimeoutTime_HU_Mid_X451" SG_ 495 RemoteHornCmd 0;
BA_ "GenSigTimeoutTime_HU_High_X451" SG_ 495 RemoteHornCmd 0;
BA_ "GenSigTimeoutTime_HU_B" SG_ 495 RemoteHornCmd 0;
BA_ "GenSigTimeoutTime_HU_A" SG_ 495 RemoteHornCmd 0;
BA_ "GenSigTimeoutMsg_HU_Mid_X451" SG_ 495 RemoteHornCmd 0;
BA_ "GenSigTimeoutMsg_HU_High_X451" SG_ 495 RemoteHornCmd 0;
BA_ "GenSigTimeoutMsg_HU_B" SG_ 495 RemoteHornCmd 0;
BA_ "GenSigTimeoutMsg_HU_A" SG_ 495 RemoteHornCmd 0;
BA_ "GenSigSendType" SG_ 495 RemoteHornCmd 2;
BA_ "GenSigTimeoutMsg_HU_High_X445" SG_ 495 RemoteHornCmd 0;
BA_ "GenSigTimeoutMsg_HU_Mid_X445" SG_ 495 RemoteHornCmd 0;
BA_ "GenSigTimeoutTime_HU_High_X445" SG_ 495 RemoteHornCmd 0;
BA_ "GenSigTimeoutTime_HU_Mid_X445" SG_ 495 RemoteHornCmd 0;
BA_ "GenSigTimeoutMsg_IVI" SG_ 495 RemoteHornCmd 0;
BA_ "GenSigTimeoutTime_IVI" SG_ 495 RemoteHornCmd 0;
BA_ "GenSigTimeoutTime_HU_Mid_X451" SG_ 495 RemoteApprochLmpCmdStatus 0;
BA_ "GenSigTimeoutTime_HU_High_X451" SG_ 495 RemoteApprochLmpCmdStatus 0;
BA_ "GenSigTimeoutTime_HU_B" SG_ 495 RemoteApprochLmpCmdStatus 0;
BA_ "GenSigTimeoutTime_HU_A" SG_ 495 RemoteApprochLmpCmdStatus 0;
BA_ "GenSigTimeoutMsg_HU_Mid_X451" SG_ 495 RemoteApprochLmpCmdStatus 0;
BA_ "GenSigTimeoutMsg_HU_High_X451" SG_ 495 RemoteApprochLmpCmdStatus 0;
BA_ "GenSigTimeoutMsg_HU_B" SG_ 495 RemoteApprochLmpCmdStatus 0;
BA_ "GenSigTimeoutMsg_HU_A" SG_ 495 RemoteApprochLmpCmdStatus 0;
BA_ "GenSigStartValue" SG_ 495 RemoteApprochLmpCmdStatus 1;
BA_ "GenSigSendType" SG_ 495 RemoteApprochLmpCmdStatus 2;
BA_ "GenSigTimeoutMsg_HU_High_X445" SG_ 495 RemoteApprochLmpCmdStatus 0;
BA_ "GenSigTimeoutMsg_HU_Mid_X445" SG_ 495 RemoteApprochLmpCmdStatus 0;
BA_ "GenSigTimeoutTime_HU_High_X445" SG_ 495 RemoteApprochLmpCmdStatus 0;
BA_ "GenSigTimeoutTime_HU_Mid_X445" SG_ 495 RemoteApprochLmpCmdStatus 0;
BA_ "GenSigTimeoutMsg_IVI" SG_ 495 RemoteApprochLmpCmdStatus 0;
BA_ "GenSigTimeoutTime_IVI" SG_ 495 RemoteApprochLmpCmdStatus 0;
BA_ "GenSigTimeoutTime_HU_Mid_X451" SG_ 495 RemoteApprochLmpCmd 0;
BA_ "GenSigTimeoutTime_HU_High_X451" SG_ 495 RemoteApprochLmpCmd 0;
BA_ "GenSigTimeoutTime_HU_B" SG_ 495 RemoteApprochLmpCmd 0;
BA_ "GenSigTimeoutTime_HU_A" SG_ 495 RemoteApprochLmpCmd 0;
BA_ "GenSigTimeoutMsg_HU_Mid_X451" SG_ 495 RemoteApprochLmpCmd 0;
BA_ "GenSigTimeoutMsg_HU_High_X451" SG_ 495 RemoteApprochLmpCmd 0;
BA_ "GenSigTimeoutMsg_HU_B" SG_ 495 RemoteApprochLmpCmd 0;
BA_ "GenSigTimeoutMsg_HU_A" SG_ 495 RemoteApprochLmpCmd 0;
BA_ "GenSigSendType" SG_ 495 RemoteApprochLmpCmd 2;
BA_ "GenSigTimeoutMsg_HU_High_X445" SG_ 495 RemoteApprochLmpCmd 0;
BA_ "GenSigTimeoutMsg_HU_Mid_X445" SG_ 495 RemoteApprochLmpCmd 0;
BA_ "GenSigTimeoutTime_HU_High_X445" SG_ 495 RemoteApprochLmpCmd 0;
BA_ "GenSigTimeoutTime_HU_Mid_X445" SG_ 495 RemoteApprochLmpCmd 0;
BA_ "GenSigTimeoutMsg_IVI" SG_ 495 RemoteApprochLmpCmd 0;
BA_ "GenSigTimeoutTime_IVI" SG_ 495 RemoteApprochLmpCmd 0;
BA_ "GenSigTimeoutTime_HU_Mid_X451" SG_ 495 RemoteValetCmdStatus 0;
BA_ "GenSigTimeoutTime_HU_High_X451" SG_ 495 RemoteValetCmdStatus 0;
BA_ "GenSigTimeoutTime_HU_B" SG_ 495 RemoteValetCmdStatus 0;
BA_ "GenSigTimeoutTime_HU_A" SG_ 495 RemoteValetCmdStatus 0;
BA_ "GenSigTimeoutMsg_HU_Mid_X451" SG_ 495 RemoteValetCmdStatus 0;
BA_ "GenSigTimeoutMsg_HU_High_X451" SG_ 495 RemoteValetCmdStatus 0;
BA_ "GenSigTimeoutMsg_HU_B" SG_ 495 RemoteValetCmdStatus 0;
BA_ "GenSigTimeoutMsg_HU_A" SG_ 495 RemoteValetCmdStatus 0;
BA_ "GenSigStartValue" SG_ 495 RemoteValetCmdStatus 1;
BA_ "GenSigSendType" SG_ 495 RemoteValetCmdStatus 2;
BA_ "GenSigTimeoutMsg_HU_High_X445" SG_ 495 RemoteValetCmdStatus 0;
BA_ "GenSigTimeoutMsg_HU_Mid_X445" SG_ 495 RemoteValetCmdStatus 0;
BA_ "GenSigTimeoutTime_HU_High_X445" SG_ 495 RemoteValetCmdStatus 0;
BA_ "GenSigTimeoutTime_HU_Mid_X445" SG_ 495 RemoteValetCmdStatus 0;
BA_ "GenSigTimeoutMsg_IVI" SG_ 495 RemoteValetCmdStatus 0;
BA_ "GenSigTimeoutTime_IVI" SG_ 495 RemoteValetCmdStatus 0;
BA_ "GenSigTimeoutTime_HU_Mid_X451" SG_ 495 RemoteValetCmd 0;
BA_ "GenSigTimeoutTime_HU_High_X451" SG_ 495 RemoteValetCmd 0;
BA_ "GenSigTimeoutTime_HU_B" SG_ 495 RemoteValetCmd 0;
BA_ "GenSigTimeoutTime_HU_A" SG_ 495 RemoteValetCmd 0;
BA_ "GenSigTimeoutMsg_HU_Mid_X451" SG_ 495 RemoteValetCmd 0;
BA_ "GenSigTimeoutMsg_HU_High_X451" SG_ 495 RemoteValetCmd 0;
BA_ "GenSigTimeoutMsg_HU_B" SG_ 495 RemoteValetCmd 0;
BA_ "GenSigTimeoutMsg_HU_A" SG_ 495 RemoteValetCmd 0;
BA_ "GenSigSendType" SG_ 495 RemoteValetCmd 2;
BA_ "GenSigTimeoutMsg_HU_High_X445" SG_ 495 RemoteValetCmd 0;
BA_ "GenSigTimeoutMsg_HU_Mid_X445" SG_ 495 RemoteValetCmd 0;
BA_ "GenSigTimeoutTime_HU_High_X445" SG_ 495 RemoteValetCmd 0;
BA_ "GenSigTimeoutTime_HU_Mid_X445" SG_ 495 RemoteValetCmd 0;
BA_ "GenSigTimeoutMsg_IVI" SG_ 495 RemoteValetCmd 0;
BA_ "GenSigTimeoutTime_IVI" SG_ 495 RemoteValetCmd 0;
BA_ "GenSigTimeoutTime_HU_Mid_X451" SG_ 495 RemoteAcTempSetStatus 0;
BA_ "GenSigTimeoutTime_HU_High_X451" SG_ 495 RemoteAcTempSetStatus 0;
BA_ "GenSigTimeoutTime_HU_B" SG_ 495 RemoteAcTempSetStatus 0;
BA_ "GenSigTimeoutTime_HU_A" SG_ 495 RemoteAcTempSetStatus 0;
BA_ "GenSigTimeoutMsg_HU_Mid_X451" SG_ 495 RemoteAcTempSetStatus 0;
BA_ "GenSigTimeoutMsg_HU_High_X451" SG_ 495 RemoteAcTempSetStatus 0;
BA_ "GenSigTimeoutMsg_HU_B" SG_ 495 RemoteAcTempSetStatus 0;
BA_ "GenSigTimeoutMsg_HU_A" SG_ 495 RemoteAcTempSetStatus 0;
BA_ "GenSigStartValue" SG_ 495 RemoteAcTempSetStatus 1;
BA_ "GenSigSendType" SG_ 495 RemoteAcTempSetStatus 2;
BA_ "GenSigTimeoutMsg_HU_High_X445" SG_ 495 RemoteAcTempSetStatus 0;
BA_ "GenSigTimeoutMsg_HU_Mid_X445" SG_ 495 RemoteAcTempSetStatus 0;
BA_ "GenSigTimeoutTime_HU_High_X445" SG_ 495 RemoteAcTempSetStatus 0;
BA_ "GenSigTimeoutTime_HU_Mid_X445" SG_ 495 RemoteAcTempSetStatus 0;
BA_ "GenSigTimeoutMsg_IVI" SG_ 495 RemoteAcTempSetStatus 0;
BA_ "GenSigTimeoutTime_IVI" SG_ 495 RemoteAcTempSetStatus 0;
BA_ "GenSigTimeoutTime_HU_Mid_X451" SG_ 495 RemoteAcTempSet 0;
BA_ "GenSigTimeoutTime_HU_High_X451" SG_ 495 RemoteAcTempSet 0;
BA_ "GenSigTimeoutTime_HU_B" SG_ 495 RemoteAcTempSet 0;
BA_ "GenSigTimeoutTime_HU_A" SG_ 495 RemoteAcTempSet 0;
BA_ "GenSigTimeoutMsg_HU_Mid_X451" SG_ 495 RemoteAcTempSet 0;
BA_ "GenSigTimeoutMsg_HU_High_X451" SG_ 495 RemoteAcTempSet 0;
BA_ "GenSigTimeoutMsg_HU_B" SG_ 495 RemoteAcTempSet 0;
BA_ "GenSigTimeoutMsg_HU_A" SG_ 495 RemoteAcTempSet 0;
BA_ "GenSigStartValue" SG_ 495 RemoteAcTempSet 8;
BA_ "GenSigSendType" SG_ 495 RemoteAcTempSet 2;
BA_ "GenSigTimeoutMsg_HU_High_X445" SG_ 495 RemoteAcTempSet 0;
BA_ "GenSigTimeoutMsg_HU_Mid_X445" SG_ 495 RemoteAcTempSet 0;
BA_ "GenSigTimeoutTime_HU_High_X445" SG_ 495 RemoteAcTempSet 0;
BA_ "GenSigTimeoutTime_HU_Mid_X445" SG_ 495 RemoteAcTempSet 0;
BA_ "GenSigTimeoutMsg_IVI" SG_ 495 RemoteAcTempSet 0;
BA_ "GenSigTimeoutTime_IVI" SG_ 495 RemoteAcTempSet 0;
BA_ "GenSigTimeoutTime_HU_Mid_X451" SG_ 495 RemoteAcCmd 0;
BA_ "GenSigTimeoutTime_HU_High_X451" SG_ 495 RemoteAcCmd 0;
BA_ "GenSigTimeoutTime_HU_B" SG_ 495 RemoteAcCmd 0;
BA_ "GenSigTimeoutTime_HU_A" SG_ 495 RemoteAcCmd 0;
BA_ "GenSigTimeoutMsg_HU_Mid_X451" SG_ 495 RemoteAcCmd 0;
BA_ "GenSigTimeoutMsg_HU_High_X451" SG_ 495 RemoteAcCmd 0;
BA_ "GenSigTimeoutMsg_HU_B" SG_ 495 RemoteAcCmd 0;
BA_ "GenSigTimeoutMsg_HU_A" SG_ 495 RemoteAcCmd 0;
BA_ "GenSigSendType" SG_ 495 RemoteAcCmd 2;
BA_ "GenSigTimeoutMsg_HU_High_X445" SG_ 495 RemoteAcCmd 0;
BA_ "GenSigTimeoutMsg_HU_Mid_X445" SG_ 495 RemoteAcCmd 0;
BA_ "GenSigTimeoutTime_HU_High_X445" SG_ 495 RemoteAcCmd 0;
BA_ "GenSigTimeoutTime_HU_Mid_X445" SG_ 495 RemoteAcCmd 0;
BA_ "GenSigTimeoutMsg_IVI" SG_ 495 RemoteAcCmd 0;
BA_ "GenSigTimeoutTime_IVI" SG_ 495 RemoteAcCmd 0;
BA_ "GenSigTimeoutTime_HU_Mid_X451" SG_ 495 RemoteAcCmdStatus 0;
BA_ "GenSigTimeoutTime_HU_High_X451" SG_ 495 RemoteAcCmdStatus 0;
BA_ "GenSigTimeoutTime_HU_B" SG_ 495 RemoteAcCmdStatus 0;
BA_ "GenSigTimeoutTime_HU_A" SG_ 495 RemoteAcCmdStatus 0;
BA_ "GenSigTimeoutMsg_HU_Mid_X451" SG_ 495 RemoteAcCmdStatus 0;
BA_ "GenSigTimeoutMsg_HU_High_X451" SG_ 495 RemoteAcCmdStatus 0;
BA_ "GenSigTimeoutMsg_HU_B" SG_ 495 RemoteAcCmdStatus 0;
BA_ "GenSigTimeoutMsg_HU_A" SG_ 495 RemoteAcCmdStatus 0;
BA_ "GenSigStartValue" SG_ 495 RemoteAcCmdStatus 1;
BA_ "GenSigSendType" SG_ 495 RemoteAcCmdStatus 2;
BA_ "GenSigTimeoutMsg_HU_High_X445" SG_ 495 RemoteAcCmdStatus 0;
BA_ "GenSigTimeoutMsg_HU_Mid_X445" SG_ 495 RemoteAcCmdStatus 0;
BA_ "GenSigTimeoutTime_HU_High_X445" SG_ 495 RemoteAcCmdStatus 0;
BA_ "GenSigTimeoutTime_HU_Mid_X445" SG_ 495 RemoteAcCmdStatus 0;
BA_ "GenSigTimeoutMsg_IVI" SG_ 495 RemoteAcCmdStatus 0;
BA_ "GenSigTimeoutTime_IVI" SG_ 495 RemoteAcCmdStatus 0;
BA_ "GenSigTimeoutTime_HU_Mid_X451" SG_ 495 RemoteImmoReqStatus 0;
BA_ "GenSigTimeoutTime_HU_High_X451" SG_ 495 RemoteImmoReqStatus 0;
BA_ "GenSigTimeoutTime_HU_B" SG_ 495 RemoteImmoReqStatus 0;
BA_ "GenSigTimeoutTime_HU_A" SG_ 495 RemoteImmoReqStatus 0;
BA_ "GenSigTimeoutMsg_HU_Mid_X451" SG_ 495 RemoteImmoReqStatus 0;
BA_ "GenSigTimeoutMsg_HU_High_X451" SG_ 495 RemoteImmoReqStatus 0;
BA_ "GenSigTimeoutMsg_HU_B" SG_ 495 RemoteImmoReqStatus 0;
BA_ "GenSigTimeoutMsg_HU_A" SG_ 495 RemoteImmoReqStatus 0;
BA_ "GenSigStartValue" SG_ 495 RemoteImmoReqStatus 1;
BA_ "GenSigSendType" SG_ 495 RemoteImmoReqStatus 2;
BA_ "GenSigTimeoutMsg_HU_High_X445" SG_ 495 RemoteImmoReqStatus 0;
BA_ "GenSigTimeoutMsg_HU_Mid_X445" SG_ 495 RemoteImmoReqStatus 0;
BA_ "GenSigTimeoutTime_HU_High_X445" SG_ 495 RemoteImmoReqStatus 0;
BA_ "GenSigTimeoutTime_HU_Mid_X445" SG_ 495 RemoteImmoReqStatus 0;
BA_ "GenSigTimeoutMsg_IVI" SG_ 495 RemoteImmoReqStatus 0;
BA_ "GenSigTimeoutTime_IVI" SG_ 495 RemoteImmoReqStatus 0;
BA_ "GenSigTimeoutTime_HU_Mid_X451" SG_ 495 RemoteImmoReq 0;
BA_ "GenSigTimeoutTime_HU_High_X451" SG_ 495 RemoteImmoReq 0;
BA_ "GenSigTimeoutTime_HU_B" SG_ 495 RemoteImmoReq 0;
BA_ "GenSigTimeoutTime_HU_A" SG_ 495 RemoteImmoReq 0;
BA_ "GenSigTimeoutMsg_HU_Mid_X451" SG_ 495 RemoteImmoReq 0;
BA_ "GenSigTimeoutMsg_HU_High_X451" SG_ 495 RemoteImmoReq 0;
BA_ "GenSigTimeoutMsg_HU_B" SG_ 495 RemoteImmoReq 0;
BA_ "GenSigTimeoutMsg_HU_A" SG_ 495 RemoteImmoReq 0;
BA_ "GenSigSendType" SG_ 495 RemoteImmoReq 2;
BA_ "GenSigTimeoutMsg_HU_High_X445" SG_ 495 RemoteImmoReq 0;
BA_ "GenSigTimeoutMsg_HU_Mid_X445" SG_ 495 RemoteImmoReq 0;
BA_ "GenSigTimeoutTime_HU_High_X445" SG_ 495 RemoteImmoReq 0;
BA_ "GenSigTimeoutTime_HU_Mid_X445" SG_ 495 RemoteImmoReq 0;
BA_ "GenSigTimeoutMsg_IVI" SG_ 495 RemoteImmoReq 0;
BA_ "GenSigTimeoutTime_IVI" SG_ 495 RemoteImmoReq 0;
BA_ "GenSigTimeoutTime_HU_Mid_X451" SG_ 495 TowInfoStatus 0;
BA_ "GenSigTimeoutTime_HU_High_X451" SG_ 495 TowInfoStatus 0;
BA_ "GenSigTimeoutTime_HU_B" SG_ 495 TowInfoStatus 0;
BA_ "GenSigTimeoutTime_HU_A" SG_ 495 TowInfoStatus 0;
BA_ "GenSigTimeoutMsg_HU_Mid_X451" SG_ 495 TowInfoStatus 0;
BA_ "GenSigTimeoutMsg_HU_High_X451" SG_ 495 TowInfoStatus 0;
BA_ "GenSigTimeoutMsg_HU_B" SG_ 495 TowInfoStatus 0;
BA_ "GenSigTimeoutMsg_HU_A" SG_ 495 TowInfoStatus 0;
BA_ "GenSigStartValue" SG_ 495 TowInfoStatus 1;
BA_ "GenSigSendType" SG_ 495 TowInfoStatus 2;
BA_ "GenSigTimeoutMsg_HU_High_X445" SG_ 495 TowInfoStatus 0;
BA_ "GenSigTimeoutMsg_HU_Mid_X445" SG_ 495 TowInfoStatus 0;
BA_ "GenSigTimeoutTime_HU_High_X445" SG_ 495 TowInfoStatus 0;
BA_ "GenSigTimeoutTime_HU_Mid_X445" SG_ 495 TowInfoStatus 0;
BA_ "GenSigTimeoutMsg_IVI" SG_ 495 TowInfoStatus 0;
BA_ "GenSigTimeoutTime_IVI" SG_ 495 TowInfoStatus 0;
BA_ "GenSigTimeoutTime_HU_Mid_X451" SG_ 495 TowInfo 0;
BA_ "GenSigTimeoutTime_HU_High_X451" SG_ 495 TowInfo 0;
BA_ "GenSigTimeoutTime_HU_B" SG_ 495 TowInfo 0;
BA_ "GenSigTimeoutTime_HU_A" SG_ 495 TowInfo 0;
BA_ "GenSigTimeoutMsg_HU_Mid_X451" SG_ 495 TowInfo 0;
BA_ "GenSigTimeoutMsg_HU_High_X451" SG_ 495 TowInfo 0;
BA_ "GenSigTimeoutMsg_HU_B" SG_ 495 TowInfo 0;
BA_ "GenSigTimeoutMsg_HU_A" SG_ 495 TowInfo 0;
BA_ "GenSigSendType" SG_ 495 TowInfo 2;
BA_ "GenSigTimeoutMsg_HU_High_X445" SG_ 495 TowInfo 0;
BA_ "GenSigTimeoutMsg_HU_Mid_X445" SG_ 495 TowInfo 0;
BA_ "GenSigTimeoutTime_HU_High_X445" SG_ 495 TowInfo 0;
BA_ "GenSigTimeoutTime_HU_Mid_X445" SG_ 495 TowInfo 0;
BA_ "GenSigTimeoutMsg_IVI" SG_ 495 TowInfo 0;
BA_ "GenSigTimeoutTime_IVI" SG_ 495 TowInfo 0;
BA_ "GenSigTimeoutTime_HU_Mid_X451" SG_ 495 ParkingCollisionInfoStatus 0;
BA_ "GenSigTimeoutTime_HU_High_X451" SG_ 495 ParkingCollisionInfoStatus 0;
BA_ "GenSigTimeoutTime_HU_B" SG_ 495 ParkingCollisionInfoStatus 0;
BA_ "GenSigTimeoutTime_HU_A" SG_ 495 ParkingCollisionInfoStatus 0;
BA_ "GenSigTimeoutMsg_HU_Mid_X451" SG_ 495 ParkingCollisionInfoStatus 0;
BA_ "GenSigTimeoutMsg_HU_High_X451" SG_ 495 ParkingCollisionInfoStatus 0;
BA_ "GenSigTimeoutMsg_HU_B" SG_ 495 ParkingCollisionInfoStatus 0;
BA_ "GenSigTimeoutMsg_HU_A" SG_ 495 ParkingCollisionInfoStatus 0;
BA_ "GenSigStartValue" SG_ 495 ParkingCollisionInfoStatus 1;
BA_ "GenSigSendType" SG_ 495 ParkingCollisionInfoStatus 2;
BA_ "GenSigTimeoutMsg_HU_High_X445" SG_ 495 ParkingCollisionInfoStatus 0;
BA_ "GenSigTimeoutMsg_HU_Mid_X445" SG_ 495 ParkingCollisionInfoStatus 0;
BA_ "GenSigTimeoutTime_HU_High_X445" SG_ 495 ParkingCollisionInfoStatus 0;
BA_ "GenSigTimeoutTime_HU_Mid_X445" SG_ 495 ParkingCollisionInfoStatus 0;
BA_ "GenSigTimeoutMsg_IVI" SG_ 495 ParkingCollisionInfoStatus 0;
BA_ "GenSigTimeoutTime_IVI" SG_ 495 ParkingCollisionInfoStatus 0;
BA_ "GenSigTimeoutTime_HU_Mid_X451" SG_ 495 ParkingCollisionInfo 0;
BA_ "GenSigTimeoutTime_HU_High_X451" SG_ 495 ParkingCollisionInfo 0;
BA_ "GenSigTimeoutTime_HU_B" SG_ 495 ParkingCollisionInfo 0;
BA_ "GenSigTimeoutTime_HU_A" SG_ 495 ParkingCollisionInfo 0;
BA_ "GenSigTimeoutMsg_HU_Mid_X451" SG_ 495 ParkingCollisionInfo 0;
BA_ "GenSigTimeoutMsg_HU_High_X451" SG_ 495 ParkingCollisionInfo 0;
BA_ "GenSigTimeoutMsg_HU_B" SG_ 495 ParkingCollisionInfo 0;
BA_ "GenSigTimeoutMsg_HU_A" SG_ 495 ParkingCollisionInfo 0;
BA_ "GenSigSendType" SG_ 495 ParkingCollisionInfo 2;
BA_ "GenSigTimeoutMsg_HU_High_X445" SG_ 495 ParkingCollisionInfo 0;
BA_ "GenSigTimeoutMsg_HU_Mid_X445" SG_ 495 ParkingCollisionInfo 0;
BA_ "GenSigTimeoutTime_HU_High_X445" SG_ 495 ParkingCollisionInfo 0;
BA_ "GenSigTimeoutTime_HU_Mid_X445" SG_ 495 ParkingCollisionInfo 0;
BA_ "GenSigTimeoutMsg_IVI" SG_ 495 ParkingCollisionInfo 0;
BA_ "GenSigTimeoutTime_IVI" SG_ 495 ParkingCollisionInfo 0;
BA_ "GenSigTimeoutTime_HU_Mid_X451" SG_ 495 RemotePositionCmdStatus 0;
BA_ "GenSigTimeoutTime_HU_High_X451" SG_ 495 RemotePositionCmdStatus 0;
BA_ "GenSigTimeoutTime_HU_B" SG_ 495 RemotePositionCmdStatus 0;
BA_ "GenSigTimeoutTime_HU_A" SG_ 495 RemotePositionCmdStatus 0;
BA_ "GenSigTimeoutMsg_HU_Mid_X451" SG_ 495 RemotePositionCmdStatus 0;
BA_ "GenSigTimeoutMsg_HU_High_X451" SG_ 495 RemotePositionCmdStatus 0;
BA_ "GenSigTimeoutMsg_HU_B" SG_ 495 RemotePositionCmdStatus 0;
BA_ "GenSigTimeoutMsg_HU_A" SG_ 495 RemotePositionCmdStatus 0;
BA_ "GenSigStartValue" SG_ 495 RemotePositionCmdStatus 1;
BA_ "GenSigSendType" SG_ 495 RemotePositionCmdStatus 2;
BA_ "GenSigTimeoutMsg_HU_High_X445" SG_ 495 RemotePositionCmdStatus 0;
BA_ "GenSigTimeoutMsg_HU_Mid_X445" SG_ 495 RemotePositionCmdStatus 0;
BA_ "GenSigTimeoutTime_HU_High_X445" SG_ 495 RemotePositionCmdStatus 0;
BA_ "GenSigTimeoutTime_HU_Mid_X445" SG_ 495 RemotePositionCmdStatus 0;
BA_ "GenSigTimeoutMsg_IVI" SG_ 495 RemotePositionCmdStatus 0;
BA_ "GenSigTimeoutTime_IVI" SG_ 495 RemotePositionCmdStatus 0;
BA_ "GenSigTimeoutTime_HU_Mid_X451" SG_ 495 RemotePositionCmd 0;
BA_ "GenSigTimeoutTime_HU_High_X451" SG_ 495 RemotePositionCmd 0;
BA_ "GenSigTimeoutTime_HU_B" SG_ 495 RemotePositionCmd 0;
BA_ "GenSigTimeoutTime_HU_A" SG_ 495 RemotePositionCmd 0;
BA_ "GenSigTimeoutMsg_HU_Mid_X451" SG_ 495 RemotePositionCmd 0;
BA_ "GenSigTimeoutMsg_HU_High_X451" SG_ 495 RemotePositionCmd 0;
BA_ "GenSigTimeoutMsg_HU_B" SG_ 495 RemotePositionCmd 0;
BA_ "GenSigTimeoutMsg_HU_A" SG_ 495 RemotePositionCmd 0;
BA_ "GenSigSendType" SG_ 495 RemotePositionCmd 2;
BA_ "GenSigTimeoutMsg_HU_High_X445" SG_ 495 RemotePositionCmd 0;
BA_ "GenSigTimeoutMsg_HU_Mid_X445" SG_ 495 RemotePositionCmd 0;
BA_ "GenSigTimeoutTime_HU_High_X445" SG_ 495 RemotePositionCmd 0;
BA_ "GenSigTimeoutTime_HU_Mid_X445" SG_ 495 RemotePositionCmd 0;
BA_ "GenSigTimeoutMsg_IVI" SG_ 495 RemotePositionCmd 0;
BA_ "GenSigTimeoutTime_IVI" SG_ 495 RemotePositionCmd 0;
BA_ "GenSigTimeoutTime_HU_Mid_X451" SG_ 495 RemoteHazardCmdStatus 0;
BA_ "GenSigTimeoutTime_HU_High_X451" SG_ 495 RemoteHazardCmdStatus 0;
BA_ "GenSigTimeoutTime_HU_B" SG_ 495 RemoteHazardCmdStatus 0;
BA_ "GenSigTimeoutTime_HU_A" SG_ 495 RemoteHazardCmdStatus 0;
BA_ "GenSigTimeoutMsg_HU_Mid_X451" SG_ 495 RemoteHazardCmdStatus 0;
BA_ "GenSigTimeoutMsg_HU_High_X451" SG_ 495 RemoteHazardCmdStatus 0;
BA_ "GenSigTimeoutMsg_HU_B" SG_ 495 RemoteHazardCmdStatus 0;
BA_ "GenSigTimeoutMsg_HU_A" SG_ 495 RemoteHazardCmdStatus 0;
BA_ "GenSigStartValue" SG_ 495 RemoteHazardCmdStatus 1;
BA_ "GenSigSendType" SG_ 495 RemoteHazardCmdStatus 2;
BA_ "GenSigTimeoutMsg_HU_High_X445" SG_ 495 RemoteHazardCmdStatus 0;
BA_ "GenSigTimeoutMsg_HU_Mid_X445" SG_ 495 RemoteHazardCmdStatus 0;
BA_ "GenSigTimeoutTime_HU_High_X445" SG_ 495 RemoteHazardCmdStatus 0;
BA_ "GenSigTimeoutTime_HU_Mid_X445" SG_ 495 RemoteHazardCmdStatus 0;
BA_ "GenSigTimeoutMsg_IVI" SG_ 495 RemoteHazardCmdStatus 0;
BA_ "GenSigTimeoutTime_IVI" SG_ 495 RemoteHazardCmdStatus 0;
BA_ "GenSigTimeoutTime_HU_Mid_X451" SG_ 495 RemoteHazardCmd 0;
BA_ "GenSigTimeoutTime_HU_High_X451" SG_ 495 RemoteHazardCmd 0;
BA_ "GenSigTimeoutTime_HU_B" SG_ 495 RemoteHazardCmd 0;
BA_ "GenSigTimeoutTime_HU_A" SG_ 495 RemoteHazardCmd 0;
BA_ "GenSigTimeoutMsg_HU_Mid_X451" SG_ 495 RemoteHazardCmd 0;
BA_ "GenSigTimeoutMsg_HU_High_X451" SG_ 495 RemoteHazardCmd 0;
BA_ "GenSigTimeoutMsg_HU_B" SG_ 495 RemoteHazardCmd 0;
BA_ "GenSigTimeoutMsg_HU_A" SG_ 495 RemoteHazardCmd 0;
BA_ "GenSigSendType" SG_ 495 RemoteHazardCmd 2;
BA_ "GenSigTimeoutMsg_HU_High_X445" SG_ 495 RemoteHazardCmd 0;
BA_ "GenSigTimeoutMsg_HU_Mid_X445" SG_ 495 RemoteHazardCmd 0;
BA_ "GenSigTimeoutTime_HU_High_X445" SG_ 495 RemoteHazardCmd 0;
BA_ "GenSigTimeoutTime_HU_Mid_X445" SG_ 495 RemoteHazardCmd 0;
BA_ "GenSigTimeoutMsg_IVI" SG_ 495 RemoteHazardCmd 0;
BA_ "GenSigTimeoutTime_IVI" SG_ 495 RemoteHazardCmd 0;
BA_ "GenSigTimeoutTime_HU_Mid_X451" SG_ 495 RemoteVehicleUnlockCmdStatus 0;
BA_ "GenSigTimeoutTime_HU_High_X451" SG_ 495 RemoteVehicleUnlockCmdStatus 0;
BA_ "GenSigTimeoutTime_HU_B" SG_ 495 RemoteVehicleUnlockCmdStatus 0;
BA_ "GenSigTimeoutTime_HU_A" SG_ 495 RemoteVehicleUnlockCmdStatus 0;
BA_ "GenSigTimeoutMsg_HU_Mid_X451" SG_ 495 RemoteVehicleUnlockCmdStatus 0;
BA_ "GenSigTimeoutMsg_HU_High_X451" SG_ 495 RemoteVehicleUnlockCmdStatus 0;
BA_ "GenSigTimeoutMsg_HU_B" SG_ 495 RemoteVehicleUnlockCmdStatus 0;
BA_ "GenSigTimeoutMsg_HU_A" SG_ 495 RemoteVehicleUnlockCmdStatus 0;
BA_ "GenSigStartValue" SG_ 495 RemoteVehicleUnlockCmdStatus 1;
BA_ "GenSigSendType" SG_ 495 RemoteVehicleUnlockCmdStatus 2;
BA_ "GenSigTimeoutMsg_HU_High_X445" SG_ 495 RemoteVehicleUnlockCmdStatus 0;
BA_ "GenSigTimeoutMsg_HU_Mid_X445" SG_ 495 RemoteVehicleUnlockCmdStatus 0;
BA_ "GenSigTimeoutTime_HU_High_X445" SG_ 495 RemoteVehicleUnlockCmdStatus 0;
BA_ "GenSigTimeoutTime_HU_Mid_X445" SG_ 495 RemoteVehicleUnlockCmdStatus 0;
BA_ "GenSigTimeoutMsg_IVI" SG_ 495 RemoteVehicleUnlockCmdStatus 0;
BA_ "GenSigTimeoutTime_IVI" SG_ 495 RemoteVehicleUnlockCmdStatus 0;
BA_ "GenSigTimeoutTime_HU_Mid_X451" SG_ 495 RemoteVehicleUnlockCmd 0;
BA_ "GenSigTimeoutTime_HU_High_X451" SG_ 495 RemoteVehicleUnlockCmd 0;
BA_ "GenSigTimeoutTime_HU_B" SG_ 495 RemoteVehicleUnlockCmd 0;
BA_ "GenSigTimeoutTime_HU_A" SG_ 495 RemoteVehicleUnlockCmd 0;
BA_ "GenSigTimeoutMsg_HU_Mid_X451" SG_ 495 RemoteVehicleUnlockCmd 0;
BA_ "GenSigTimeoutMsg_HU_High_X451" SG_ 495 RemoteVehicleUnlockCmd 0;
BA_ "GenSigTimeoutMsg_HU_B" SG_ 495 RemoteVehicleUnlockCmd 0;
BA_ "GenSigTimeoutMsg_HU_A" SG_ 495 RemoteVehicleUnlockCmd 0;
BA_ "GenSigSendType" SG_ 495 RemoteVehicleUnlockCmd 2;
BA_ "GenSigTimeoutMsg_HU_High_X445" SG_ 495 RemoteVehicleUnlockCmd 0;
BA_ "GenSigTimeoutMsg_HU_Mid_X445" SG_ 495 RemoteVehicleUnlockCmd 0;
BA_ "GenSigTimeoutTime_HU_High_X445" SG_ 495 RemoteVehicleUnlockCmd 0;
BA_ "GenSigTimeoutTime_HU_Mid_X445" SG_ 495 RemoteVehicleUnlockCmd 0;
BA_ "GenSigTimeoutMsg_IVI" SG_ 495 RemoteVehicleUnlockCmd 0;
BA_ "GenSigTimeoutTime_IVI" SG_ 495 RemoteVehicleUnlockCmd 0;
BA_ "GenSigTimeoutTime_HU_Mid_X451" SG_ 495 RemoteVehicleLockCmdStatus 0;
BA_ "GenSigTimeoutTime_HU_High_X451" SG_ 495 RemoteVehicleLockCmdStatus 0;
BA_ "GenSigTimeoutTime_HU_B" SG_ 495 RemoteVehicleLockCmdStatus 0;
BA_ "GenSigTimeoutTime_HU_A" SG_ 495 RemoteVehicleLockCmdStatus 0;
BA_ "GenSigTimeoutMsg_HU_Mid_X451" SG_ 495 RemoteVehicleLockCmdStatus 0;
BA_ "GenSigTimeoutMsg_HU_High_X451" SG_ 495 RemoteVehicleLockCmdStatus 0;
BA_ "GenSigTimeoutMsg_HU_B" SG_ 495 RemoteVehicleLockCmdStatus 0;
BA_ "GenSigTimeoutMsg_HU_A" SG_ 495 RemoteVehicleLockCmdStatus 0;
BA_ "GenSigStartValue" SG_ 495 RemoteVehicleLockCmdStatus 1;
BA_ "GenSigSendType" SG_ 495 RemoteVehicleLockCmdStatus 2;
BA_ "GenSigTimeoutMsg_HU_High_X445" SG_ 495 RemoteVehicleLockCmdStatus 0;
BA_ "GenSigTimeoutMsg_HU_Mid_X445" SG_ 495 RemoteVehicleLockCmdStatus 0;
BA_ "GenSigTimeoutTime_HU_High_X445" SG_ 495 RemoteVehicleLockCmdStatus 0;
BA_ "GenSigTimeoutTime_HU_Mid_X445" SG_ 495 RemoteVehicleLockCmdStatus 0;
BA_ "GenSigTimeoutMsg_IVI" SG_ 495 RemoteVehicleLockCmdStatus 0;
BA_ "GenSigTimeoutTime_IVI" SG_ 495 RemoteVehicleLockCmdStatus 0;
BA_ "GenSigTimeoutTime_HU_Mid_X451" SG_ 495 RemoteVehicleLockCmd 0;
BA_ "GenSigTimeoutTime_HU_High_X451" SG_ 495 RemoteVehicleLockCmd 0;
BA_ "GenSigTimeoutTime_HU_B" SG_ 495 RemoteVehicleLockCmd 0;
BA_ "GenSigTimeoutTime_HU_A" SG_ 495 RemoteVehicleLockCmd 0;
BA_ "GenSigTimeoutMsg_HU_Mid_X451" SG_ 495 RemoteVehicleLockCmd 0;
BA_ "GenSigTimeoutMsg_HU_High_X451" SG_ 495 RemoteVehicleLockCmd 0;
BA_ "GenSigTimeoutMsg_HU_B" SG_ 495 RemoteVehicleLockCmd 0;
BA_ "GenSigTimeoutMsg_HU_A" SG_ 495 RemoteVehicleLockCmd 0;
BA_ "GenSigSendType" SG_ 495 RemoteVehicleLockCmd 2;
BA_ "GenSigTimeoutMsg_HU_High_X445" SG_ 495 RemoteVehicleLockCmd 0;
BA_ "GenSigTimeoutMsg_HU_Mid_X445" SG_ 495 RemoteVehicleLockCmd 0;
BA_ "GenSigTimeoutTime_HU_High_X445" SG_ 495 RemoteVehicleLockCmd 0;
BA_ "GenSigTimeoutTime_HU_Mid_X445" SG_ 495 RemoteVehicleLockCmd 0;
BA_ "GenSigTimeoutMsg_IVI" SG_ 495 RemoteVehicleLockCmd 0;
BA_ "GenSigTimeoutTime_IVI" SG_ 495 RemoteVehicleLockCmd 0;
BA_ "Remarks" SG_ 580 CurrentBattDischargeSOClimit "null*";
BA_ "GenSigStartValue" SG_ 580 CurrentBattDischargeSOClimit 50;
BA_ "GenSigSendType" SG_ 580 CurrentBattDischargeSOClimit 7;
BA_ "GenSigCycleTimeActive" SG_ 580 CurrentBattDischargeSOClimit 100;
BA_ "GenSigCycleTime" SG_ 580 CurrentBattDischargeSOClimit 100;
BA_ "GenSigSendType" SG_ 580 BrakePaddlePosVcuStatus 7;
BA_ "GenSigCycleTimeActive" SG_ 580 BrakePaddlePosVcuStatus 100;
BA_ "GenSigCycleTime" SG_ 580 BrakePaddlePosVcuStatus 100;
BA_ "GenSigSendType" SG_ 580 BrakePaddlePosVcu 7;
BA_ "GenSigCycleTimeActive" SG_ 580 BrakePaddlePosVcu 100;
BA_ "GenSigCycleTime" SG_ 580 BrakePaddlePosVcu 100;
BA_ "GenSigSendType" SG_ 580 HVBattSoCPercenStatus_VCAN 7;
BA_ "GenSigCycleTimeActive" SG_ 580 HVBattSoCPercenStatus_VCAN 100;
BA_ "GenSigCycleTime" SG_ 580 HVBattSoCPercenStatus_VCAN 100;
BA_ "GenSigSendType" SG_ 580 HVBattSoCPercen_VCAN 7;
BA_ "GenSigCycleTimeActive" SG_ 580 HVBattSoCPercen_VCAN 100;
BA_ "GenSigCycleTime" SG_ 580 HVBattSoCPercen_VCAN 100;
BA_ "GenSigSendType" SG_ 580 DTeInfoStatus_VCAN 7;
BA_ "GenSigCycleTimeActive" SG_ 580 DTeInfoStatus_VCAN 100;
BA_ "GenSigCycleTime" SG_ 580 DTeInfoStatus_VCAN 100;
BA_ "GenSigSendType" SG_ 580 DTeInfo_VCAN 7;
BA_ "GenSigCycleTimeActive" SG_ 580 DTeInfo_VCAN 100;
BA_ "GenSigCycleTime" SG_ 580 DTeInfo_VCAN 100;
BA_ "GenSigSendType" SG_ 580 VehicleStatus 7;
BA_ "GenSigCycleTimeActive" SG_ 580 VehicleStatus 100;
BA_ "GenSigCycleTime" SG_ 580 VehicleStatus 100;
BA_ "GenSigSendType" SG_ 580 VcuStatus 7;
BA_ "GenSigCycleTimeActive" SG_ 580 VcuStatus 100;
BA_ "GenSigCycleTime" SG_ 580 VcuStatus 100;
BA_ "GenSigSendType" SG_ 580 ValetStateStatus 7;
BA_ "GenSigCycleTimeActive" SG_ 580 ValetStateStatus 100;
BA_ "GenSigCycleTime" SG_ 580 ValetStateStatus 100;
BA_ "GenSigSendType" SG_ 580 ValetState 7;
BA_ "GenSigCycleTimeActive" SG_ 580 ValetState 100;
BA_ "GenSigCycleTime" SG_ 580 ValetState 100;
BA_ "GenSigSendType" SG_ 580 AcComprMalFn 7;
BA_ "GenSigCycleTimeActive" SG_ 580 AcComprMalFn 100;
BA_ "GenSigCycleTime" SG_ 580 AcComprMalFn 100;
BA_ "GenSigSendType" SG_ 580 AcCmprStatusVcu 7;
BA_ "GenSigCycleTimeActive" SG_ 580 AcCmprStatusVcu 100;
BA_ "GenSigCycleTime" SG_ 580 AcCmprStatusVcu 100;
BA_ "GenSigSendType" SG_ 580 VcuPowerMode_VCAN 7;
BA_ "GenSigCycleTimeActive" SG_ 580 VcuPowerMode_VCAN 100;
BA_ "GenSigCycleTime" SG_ 580 VcuPowerMode_VCAN 100;
BA_ "GenSigSendType" SG_ 580 VcuPowerModeStatus_VCAN 7;
BA_ "GenSigCycleTimeActive" SG_ 580 VcuPowerModeStatus_VCAN 100;
BA_ "GenSigCycleTime" SG_ 580 VcuPowerModeStatus_VCAN 100;
BA_ "GenSigSendType" SG_ 579 VcuHazardLampReqStatus 7;
BA_ "GenSigCycleTimeActive" SG_ 579 VcuHazardLampReqStatus 100;
BA_ "GenSigCycleTime" SG_ 579 VcuHazardLampReqStatus 100;
BA_ "GenSigSendType" SG_ 579 VcuHazardLampReq 7;
BA_ "GenSigCycleTimeActive" SG_ 579 VcuHazardLampReq 100;
BA_ "GenSigCycleTime" SG_ 579 VcuHazardLampReq 100;
BA_ "GenSigSendType" SG_ 579 VCuPresence 7;
BA_ "GenSigCycleTimeActive" SG_ 579 VCuPresence 100;
BA_ "GenSigCycleTime" SG_ 579 VCuPresence 100;
BA_ "GenSigSendType" SG_ 579 BrkVacPumpStatus 7;
BA_ "GenSigCycleTimeActive" SG_ 579 BrkVacPumpStatus 100;
BA_ "GenSigCycleTime" SG_ 579 BrkVacPumpStatus 100;
BA_ "GenSigSendType" SG_ 579 DriveMotorStatus 7;
BA_ "GenSigCycleTimeActive" SG_ 579 DriveMotorStatus 100;
BA_ "GenSigCycleTime" SG_ 579 DriveMotorStatus 100;
BA_ "GenSigSendType" SG_ 579 HvBattSoh 7;
BA_ "GenSigCycleTimeActive" SG_ 579 HvBattSoh 100;
BA_ "GenSigCycleTime" SG_ 579 HvBattSoh 100;
BA_ "GenSigSendType" SG_ 579 RegenAmpHr 7;
BA_ "GenSigCycleTimeActive" SG_ 579 RegenAmpHr 100;
BA_ "GenSigCycleTime" SG_ 579 RegenAmpHr 100;
BA_ "GenSigSendType" SG_ 579 HvBattPackVolStatus 7;
BA_ "GenSigCycleTimeActive" SG_ 579 HvBattPackVolStatus 100;
BA_ "GenSigCycleTime" SG_ 579 HvBattPackVolStatus 100;
BA_ "GenSigSendType" SG_ 579 HvBattPackVol 7;
BA_ "GenSigCycleTimeActive" SG_ 579 HvBattPackVol 100;
BA_ "GenSigCycleTime" SG_ 579 HvBattPackVol 100;
BA_ "GenSigSendType" SG_ 579 AvgEnergyConsmption 7;
BA_ "GenSigCycleTimeActive" SG_ 579 AvgEnergyConsmption 100;
BA_ "GenSigCycleTime" SG_ 579 AvgEnergyConsmption 100;
BA_ "GenSigSendType" SG_ 579 AvgEnergyConsmptionStatus 7;
BA_ "GenSigCycleTimeActive" SG_ 579 AvgEnergyConsmptionStatus 100;
BA_ "GenSigCycleTime" SG_ 579 AvgEnergyConsmptionStatus 100;
BA_ "GenSigSendType" SG_ 579 MotorHightempStatus 7;
BA_ "GenSigCycleTimeActive" SG_ 579 MotorHightempStatus 100;
BA_ "GenSigCycleTime" SG_ 579 MotorHightempStatus 100;
BA_ "GenSigSendType" SG_ 579 MotorHightemp 7;
BA_ "GenSigCycleTimeActive" SG_ 579 MotorHightemp 100;
BA_ "GenSigCycleTime" SG_ 579 MotorHightemp 100;
BA_ "GenSigStartValue" SG_ 579 VcuGearSelectionChangeTxt 1;
BA_ "GenSigSendType" SG_ 579 VcuGearSelectionChangeTxt 7;
BA_ "GenSigCycleTimeActive" SG_ 579 VcuGearSelectionChangeTxt 100;
BA_ "GenSigCycleTime" SG_ 579 VcuGearSelectionChangeTxt 100;
BA_ "GenSigSendType" SG_ 579 ImmoStatusVcu 7;
BA_ "GenSigCycleTimeActive" SG_ 579 ImmoStatusVcu 100;
BA_ "GenSigCycleTime" SG_ 579 ImmoStatusVcu 100;
BA_ "GenSigSendType" SG_ 579 ClntTempVcuStatus 7;
BA_ "GenSigCycleTimeActive" SG_ 579 ClntTempVcuStatus 100;
BA_ "GenSigCycleTime" SG_ 579 ClntTempVcuStatus 100;
BA_ "GenSigStartValue" SG_ 579 ClntTempVcu 10;
BA_ "GenSigSendType" SG_ 579 ClntTempVcu 7;
BA_ "GenSigCycleTimeActive" SG_ 579 ClntTempVcu 100;
BA_ "GenSigCycleTime" SG_ 579 ClntTempVcu 100;
BA_ "GenSigStartValue" SG_ 579 GearForDisplayVcu 1;
BA_ "GenSigSendType" SG_ 579 GearForDisplayVcu 7;
BA_ "GenSigCycleTimeActive" SG_ 579 GearForDisplayVcu 100;
BA_ "GenSigCycleTime" SG_ 579 GearForDisplayVcu 100;
BA_ "GenSigSendType" SG_ 579 GearForDisplayVcuStatus 7;
BA_ "GenSigCycleTimeActive" SG_ 579 GearForDisplayVcuStatus 100;
BA_ "GenSigCycleTime" SG_ 579 GearForDisplayVcuStatus 100;
BA_ "GenSigSendType" SG_ 273 AccPedPosnVcuStatus 7;
BA_ "GenSigCycleTimeActive" SG_ 273 AccPedPosnVcuStatus 10;
BA_ "GenSigCycleTime" SG_ 273 AccPedPosnVcuStatus 10;
BA_ "GenSigSendType" SG_ 273 AccPedPosnVcu 7;
BA_ "GenSigCycleTimeActive" SG_ 273 AccPedPosnVcu 10;
BA_ "GenSigCycleTime" SG_ 273 AccPedPosnVcu 10;
BA_ "GenSigStartValue" SG_ 273 BrkPressStateVcu 1;
BA_ "GenSigSendType" SG_ 273 BrkPressStateVcu 7;
BA_ "GenSigCycleTimeActive" SG_ 273 BrkPressStateVcu 10;
BA_ "GenSigCycleTime" SG_ 273 BrkPressStateVcu 10;
BA_ "GenSigSendType" SG_ 273 BrkPressStatusVcu 7;
BA_ "GenSigCycleTimeActive" SG_ 273 BrkPressStatusVcu 10;
BA_ "GenSigCycleTime" SG_ 273 BrkPressStatusVcu 10;
BA_ "GenSigSendType" SG_ 192 LWS_ANGLE 7;
BA_ "GenSigCycleTimeActive" SG_ 192 LWS_ANGLE 10;
BA_ "GenSigCycleTime" SG_ 192 LWS_ANGLE 10;
BA_ "GenSigSendType" SG_ 259 MSG_CNT_5 7;
BA_ "GenSigCycleTimeActive" SG_ 259 MSG_CNT_5 100;
BA_ "GenSigCycleTime" SG_ 259 MSG_CNT_5 100;
BA_ "GenSigSendType" SG_ 259 CRC_5 7;
BA_ "GenSigCycleTimeActive" SG_ 259 CRC_5 100;
BA_ "GenSigCycleTime" SG_ 259 CRC_5 100;
BA_ "GenSigSendType" SG_ 259 CrashoutputSignal 7;
BA_ "GenSigCycleTimeActive" SG_ 259 CrashoutputSignal 100;
BA_ "GenSigCycleTime" SG_ 259 CrashoutputSignal 100;
BA_ "GenSigSendType" SG_ 259 FrPassSBRIndication 7;
BA_ "GenSigCycleTimeActive" SG_ 259 FrPassSBRIndication 100;
BA_ "GenSigCycleTime" SG_ 259 FrPassSBRIndication 100;
BA_ "GenSigStartValue" SG_ 259 SRSWarningLamp 1;
BA_ "GenSigSendType" SG_ 259 SRSWarningLamp 7;
BA_ "GenSigCycleTimeActive" SG_ 259 SRSWarningLamp 100;
BA_ "GenSigCycleTime" SG_ 259 SRSWarningLamp 100;
BA_ "GenSigSendType" SG_ 277 SteerAngEPAS 7;
BA_ "GenSigCycleTimeActive" SG_ 277 SteerAngEPAS 10;
BA_ "GenSigCycleTime" SG_ 277 SteerAngEPAS 10;
BA_ "GenSigSendType" SG_ 277 SteerAngEPAsDir 7;
BA_ "GenSigCycleTimeActive" SG_ 277 SteerAngEPAsDir 10;
BA_ "GenSigCycleTime" SG_ 277 SteerAngEPAsDir 10;
BA_ "GenSigStartValue" SG_ 277 SteerAngEPASStatus 2;
BA_ "GenSigSendType" SG_ 277 SteerAngEPASStatus 7;
BA_ "GenSigCycleTimeActive" SG_ 277 SteerAngEPASStatus 10;
BA_ "GenSigCycleTime" SG_ 277 SteerAngEPASStatus 10;
BA_ "GenSigSendType" SG_ 370 RCrankEnableStatus 7;
BA_ "GenSigCycleTimeActive" SG_ 370 RCrankEnableStatus 20;
BA_ "GenSigCycleTime" SG_ 370 RCrankEnableStatus 20;
BA_ "GenSigSendType" SG_ 370 RCrankEnable 7;
BA_ "GenSigCycleTimeActive" SG_ 370 RCrankEnable 20;
BA_ "GenSigCycleTime" SG_ 370 RCrankEnable 20;
BA_ "GenSigSendType" SG_ 370 BrkLightSig2Status 7;
BA_ "GenSigCycleTimeActive" SG_ 370 BrkLightSig2Status 20;
BA_ "GenSigCycleTime" SG_ 370 BrkLightSig2Status 20;
BA_ "GenSigSendType" SG_ 370 BrkLightSig2 7;
BA_ "GenSigCycleTimeActive" SG_ 370 BrkLightSig2 20;
BA_ "GenSigCycleTime" SG_ 370 BrkLightSig2 20;
BA_ "GenSigSendType" SG_ 370 EBdStatus 7;
BA_ "GenSigCycleTimeActive" SG_ 370 EBdStatus 20;
BA_ "GenSigCycleTime" SG_ 370 EBdStatus 20;
BA_ "GenSigSendType" SG_ 370 EBdActive 7;
BA_ "GenSigCycleTimeActive" SG_ 370 EBdActive 20;
BA_ "GenSigCycleTime" SG_ 370 EBdActive 20;
BA_ "GenSigSendType" SG_ 370 HHcStatus 7;
BA_ "GenSigCycleTimeActive" SG_ 370 HHcStatus 20;
BA_ "GenSigCycleTime" SG_ 370 HHcStatus 20;
BA_ "GenSigSendType" SG_ 370 HDcAvailability 7;
BA_ "GenSigCycleTimeActive" SG_ 370 HDcAvailability 20;
BA_ "GenSigCycleTime" SG_ 370 HDcAvailability 20;
BA_ "GenSigSendType" SG_ 370 HHcActive 7;
BA_ "GenSigCycleTimeActive" SG_ 370 HHcActive 20;
BA_ "GenSigCycleTime" SG_ 370 HHcActive 20;
BA_ "GenSigSendType" SG_ 370 HDcActive 7;
BA_ "GenSigCycleTimeActive" SG_ 370 HDcActive 20;
BA_ "GenSigCycleTime" SG_ 370 HDcActive 20;
BA_ "GenSigSendType" SG_ 370 HDcStatus 7;
BA_ "GenSigCycleTimeActive" SG_ 370 HDcStatus 20;
BA_ "GenSigCycleTime" SG_ 370 HDcStatus 20;
BA_ "GenSigSendType" SG_ 374 DrvModeIndctnESP2Status 7;
BA_ "GenSigCycleTimeActive" SG_ 374 DrvModeIndctnESP2Status 20;
BA_ "GenSigCycleTime" SG_ 374 DrvModeIndctnESP2Status 20;
BA_ "GenSigSendType" SG_ 374 DrvModeIndctnESP2 7;
BA_ "GenSigCycleTimeActive" SG_ 374 DrvModeIndctnESP2 20;
BA_ "GenSigCycleTime" SG_ 374 DrvModeIndctnESP2 20;
BA_ "GenSigStartValue" SG_ 376 AX1 32768;
BA_ "GenSigSendType" SG_ 376 AX1 7;
BA_ "GenSigCycleTimeActive" SG_ 376 AX1 20;
BA_ "GenSigCycleTime" SG_ 376 AX1 20;
BA_ "GenSigStartValue" SG_ 376 AY1 32768;
BA_ "GenSigSendType" SG_ 376 AY1 7;
BA_ "GenSigCycleTimeActive" SG_ 376 AY1 20;
BA_ "GenSigCycleTime" SG_ 376 AY1 20;
BA_ "GenSigSendType" SG_ 407 SpdCountSig 7;
BA_ "GenSigCycleTimeActive" SG_ 407 SpdCountSig 20;
BA_ "GenSigCycleTime" SG_ 407 SpdCountSig 20;
BA_ "GenSigSendType" SG_ 407 SpdCRCSig 7;
BA_ "GenSigCycleTimeActive" SG_ 407 SpdCRCSig 20;
BA_ "GenSigCycleTime" SG_ 407 SpdCRCSig 20;
BA_ "GenSigSendType" SG_ 407 VehSpdIC 7;
BA_ "GenSigCycleTimeActive" SG_ 407 VehSpdIC 20;
BA_ "GenSigCycleTime" SG_ 407 VehSpdIC 20;
BA_ "GenSigSendType" SG_ 407 VehSpdICStatus 7;
BA_ "GenSigCycleTimeActive" SG_ 407 VehSpdICStatus 20;
BA_ "GenSigCycleTime" SG_ 407 VehSpdICStatus 20;
BA_ "GenSigTimeoutTime_HU_Mid_X451" SG_ 448 PDcHuOnDelayTimer 0;
BA_ "GenSigTimeoutTime_HU_High_X451" SG_ 448 PDcHuOnDelayTimer 0;
BA_ "GenSigTimeoutTime_HU_B" SG_ 448 PDcHuOnDelayTimer 0;
BA_ "GenSigTimeoutTime_HU_A" SG_ 448 PDcHuOnDelayTimer 0;
BA_ "GenSigTimeoutMsg_HU_Mid_X451" SG_ 448 PDcHuOnDelayTimer 0;
BA_ "GenSigTimeoutMsg_HU_High_X451" SG_ 448 PDcHuOnDelayTimer 0;
BA_ "GenSigTimeoutMsg_HU_B" SG_ 448 PDcHuOnDelayTimer 0;
BA_ "GenSigTimeoutMsg_HU_A" SG_ 448 PDcHuOnDelayTimer 0;
BA_ "GenSigStartValue" SG_ 448 PDcHuOnDelayTimer 1;
BA_ "GenSigSendType" SG_ 448 PDcHuOnDelayTimer 1;
BA_ "GenSigTimeoutMsg_HU_High_X445" SG_ 448 PDcHuOnDelayTimer 0;
BA_ "GenSigTimeoutMsg_HU_Mid_X445" SG_ 448 PDcHuOnDelayTimer 0;
BA_ "GenSigTimeoutTime_HU_High_X445" SG_ 448 PDcHuOnDelayTimer 0;
BA_ "GenSigTimeoutTime_HU_Mid_X445" SG_ 448 PDcHuOnDelayTimer 0;
BA_ "GenSigTimeoutMsg_IVI" SG_ 448 PDcHuOnDelayTimer 0;
BA_ "GenSigTimeoutTime_IVI" SG_ 448 PDcHuOnDelayTimer 0;
BA_ "GenSigTimeoutTime_HU_Mid_X451" SG_ 448 PDcHuToneVolume 0;
BA_ "GenSigTimeoutTime_HU_High_X451" SG_ 448 PDcHuToneVolume 0;
BA_ "GenSigTimeoutTime_HU_B" SG_ 448 PDcHuToneVolume 0;
BA_ "GenSigTimeoutTime_HU_A" SG_ 448 PDcHuToneVolume 0;
BA_ "GenSigTimeoutMsg_HU_Mid_X451" SG_ 448 PDcHuToneVolume 0;
BA_ "GenSigTimeoutMsg_HU_High_X451" SG_ 448 PDcHuToneVolume 0;
BA_ "GenSigTimeoutMsg_HU_B" SG_ 448 PDcHuToneVolume 0;
BA_ "GenSigTimeoutMsg_HU_A" SG_ 448 PDcHuToneVolume 0;
BA_ "GenSigSendType" SG_ 448 PDcHuToneVolume 1;
BA_ "GenSigTimeoutMsg_HU_High_X445" SG_ 448 PDcHuToneVolume 0;
BA_ "GenSigTimeoutMsg_HU_Mid_X445" SG_ 448 PDcHuToneVolume 0;
BA_ "GenSigTimeoutTime_HU_High_X445" SG_ 448 PDcHuToneVolume 0;
BA_ "GenSigTimeoutTime_HU_Mid_X445" SG_ 448 PDcHuToneVolume 0;
BA_ "GenSigTimeoutMsg_IVI" SG_ 448 PDcHuToneVolume 0;
BA_ "GenSigTimeoutTime_IVI" SG_ 448 PDcHuToneVolume 0;
BA_ "GenSigTimeoutTime_HU_Mid_X451" SG_ 448 PDcHuRearTone 0;
BA_ "GenSigTimeoutTime_HU_High_X451" SG_ 448 PDcHuRearTone 0;
BA_ "GenSigTimeoutTime_HU_B" SG_ 448 PDcHuRearTone 0;
BA_ "GenSigTimeoutTime_HU_A" SG_ 448 PDcHuRearTone 0;
BA_ "GenSigTimeoutMsg_HU_Mid_X451" SG_ 448 PDcHuRearTone 0;
BA_ "GenSigTimeoutMsg_HU_High_X451" SG_ 448 PDcHuRearTone 0;
BA_ "GenSigTimeoutMsg_HU_B" SG_ 448 PDcHuRearTone 0;
BA_ "GenSigTimeoutMsg_HU_A" SG_ 448 PDcHuRearTone 0;
BA_ "GenSigSendType" SG_ 448 PDcHuRearTone 1;
BA_ "GenSigTimeoutMsg_HU_High_X445" SG_ 448 PDcHuRearTone 0;
BA_ "GenSigTimeoutMsg_HU_Mid_X445" SG_ 448 PDcHuRearTone 0;
BA_ "GenSigTimeoutTime_HU_High_X445" SG_ 448 PDcHuRearTone 0;
BA_ "GenSigTimeoutTime_HU_Mid_X445" SG_ 448 PDcHuRearTone 0;
BA_ "GenSigTimeoutMsg_IVI" SG_ 448 PDcHuRearTone 0;
BA_ "GenSigTimeoutTime_IVI" SG_ 448 PDcHuRearTone 0;
BA_ "GenSigTimeoutTime_HU_Mid_X451" SG_ 448 PDcHuRearNoOfSen 0;
BA_ "GenSigTimeoutTime_HU_High_X451" SG_ 448 PDcHuRearNoOfSen 0;
BA_ "GenSigTimeoutTime_HU_B" SG_ 448 PDcHuRearNoOfSen 0;
BA_ "GenSigTimeoutTime_HU_A" SG_ 448 PDcHuRearNoOfSen 0;
BA_ "GenSigTimeoutMsg_HU_Mid_X451" SG_ 448 PDcHuRearNoOfSen 0;
BA_ "GenSigTimeoutMsg_HU_High_X451" SG_ 448 PDcHuRearNoOfSen 0;
BA_ "GenSigTimeoutMsg_HU_B" SG_ 448 PDcHuRearNoOfSen 0;
BA_ "GenSigTimeoutMsg_HU_A" SG_ 448 PDcHuRearNoOfSen 0;
BA_ "GenSigSendType" SG_ 448 PDcHuRearNoOfSen 1;
BA_ "GenSigTimeoutMsg_HU_High_X445" SG_ 448 PDcHuRearNoOfSen 0;
BA_ "GenSigTimeoutMsg_HU_Mid_X445" SG_ 448 PDcHuRearNoOfSen 0;
BA_ "GenSigTimeoutTime_HU_High_X445" SG_ 448 PDcHuRearNoOfSen 0;
BA_ "GenSigTimeoutTime_HU_Mid_X445" SG_ 448 PDcHuRearNoOfSen 0;
BA_ "GenSigTimeoutMsg_IVI" SG_ 448 PDcHuRearNoOfSen 0;
BA_ "GenSigTimeoutTime_IVI" SG_ 448 PDcHuRearNoOfSen 0;
BA_ "GenSigTimeoutTime_HU_Mid_X451" SG_ 448 PDcHuVehicleImage 0;
BA_ "GenSigTimeoutTime_HU_High_X451" SG_ 448 PDcHuVehicleImage 0;
BA_ "GenSigTimeoutTime_HU_B" SG_ 448 PDcHuVehicleImage 0;
BA_ "GenSigTimeoutTime_HU_A" SG_ 448 PDcHuVehicleImage 0;
BA_ "GenSigTimeoutMsg_HU_Mid_X451" SG_ 448 PDcHuVehicleImage 0;
BA_ "GenSigTimeoutMsg_HU_High_X451" SG_ 448 PDcHuVehicleImage 0;
BA_ "GenSigTimeoutMsg_HU_B" SG_ 448 PDcHuVehicleImage 0;
BA_ "GenSigTimeoutMsg_HU_A" SG_ 448 PDcHuVehicleImage 0;
BA_ "GenSigSendType" SG_ 448 PDcHuVehicleImage 1;
BA_ "GenSigTimeoutMsg_HU_High_X445" SG_ 448 PDcHuVehicleImage 0;
BA_ "GenSigTimeoutMsg_HU_Mid_X445" SG_ 448 PDcHuVehicleImage 0;
BA_ "GenSigTimeoutTime_HU_High_X445" SG_ 448 PDcHuVehicleImage 0;
BA_ "GenSigTimeoutTime_HU_Mid_X445" SG_ 448 PDcHuVehicleImage 0;
BA_ "GenSigTimeoutMsg_IVI" SG_ 448 PDcHuVehicleImage 0;
BA_ "GenSigTimeoutTime_IVI" SG_ 448 PDcHuVehicleImage 0;
BA_ "GenSigTimeoutTime_HU_Mid_X451" SG_ 448 PDcHuFrontActivationState 0;
BA_ "GenSigTimeoutTime_HU_High_X451" SG_ 448 PDcHuFrontActivationState 0;
BA_ "GenSigTimeoutTime_HU_B" SG_ 448 PDcHuFrontActivationState 0;
BA_ "GenSigTimeoutTime_HU_A" SG_ 448 PDcHuFrontActivationState 0;
BA_ "GenSigTimeoutMsg_HU_Mid_X451" SG_ 448 PDcHuFrontActivationState 0;
BA_ "GenSigTimeoutMsg_HU_High_X451" SG_ 448 PDcHuFrontActivationState 0;
BA_ "GenSigTimeoutMsg_HU_B" SG_ 448 PDcHuFrontActivationState 0;
BA_ "GenSigTimeoutMsg_HU_A" SG_ 448 PDcHuFrontActivationState 0;
BA_ "GenSigSendType" SG_ 448 PDcHuFrontActivationState 1;
BA_ "GenSigTimeoutMsg_HU_High_X445" SG_ 448 PDcHuFrontActivationState 0;
BA_ "GenSigTimeoutMsg_HU_Mid_X445" SG_ 448 PDcHuFrontActivationState 0;
BA_ "GenSigTimeoutTime_HU_High_X445" SG_ 448 PDcHuFrontActivationState 0;
BA_ "GenSigTimeoutTime_HU_Mid_X445" SG_ 448 PDcHuFrontActivationState 0;
BA_ "GenSigTimeoutMsg_IVI" SG_ 448 PDcHuFrontActivationState 0;
BA_ "GenSigTimeoutTime_IVI" SG_ 448 PDcHuFrontActivationState 0;
BA_ "GenSigTimeoutTime_HU_Mid_X451" SG_ 448 PDcHuLowSpeedActivation 0;
BA_ "GenSigTimeoutTime_HU_High_X451" SG_ 448 PDcHuLowSpeedActivation 0;
BA_ "GenSigTimeoutTime_HU_B" SG_ 448 PDcHuLowSpeedActivation 0;
BA_ "GenSigTimeoutTime_HU_A" SG_ 448 PDcHuLowSpeedActivation 0;
BA_ "GenSigTimeoutMsg_HU_Mid_X451" SG_ 448 PDcHuLowSpeedActivation 0;
BA_ "GenSigTimeoutMsg_HU_High_X451" SG_ 448 PDcHuLowSpeedActivation 0;
BA_ "GenSigTimeoutMsg_HU_B" SG_ 448 PDcHuLowSpeedActivation 0;
BA_ "GenSigTimeoutMsg_HU_A" SG_ 448 PDcHuLowSpeedActivation 0;
BA_ "GenSigSendType" SG_ 448 PDcHuLowSpeedActivation 1;
BA_ "GenSigTimeoutMsg_HU_High_X445" SG_ 448 PDcHuLowSpeedActivation 0;
BA_ "GenSigTimeoutMsg_HU_Mid_X445" SG_ 448 PDcHuLowSpeedActivation 0;
BA_ "GenSigTimeoutTime_HU_High_X445" SG_ 448 PDcHuLowSpeedActivation 0;
BA_ "GenSigTimeoutTime_HU_Mid_X445" SG_ 448 PDcHuLowSpeedActivation 0;
BA_ "GenSigTimeoutMsg_IVI" SG_ 448 PDcHuLowSpeedActivation 0;
BA_ "GenSigTimeoutTime_IVI" SG_ 448 PDcHuLowSpeedActivation 0;
BA_ "GenSigTimeoutTime_HU_Mid_X451" SG_ 448 PDcHuFrontNoOfSen 0;
BA_ "GenSigTimeoutTime_HU_High_X451" SG_ 448 PDcHuFrontNoOfSen 0;
BA_ "GenSigTimeoutTime_HU_B" SG_ 448 PDcHuFrontNoOfSen 0;
BA_ "GenSigTimeoutTime_HU_A" SG_ 448 PDcHuFrontNoOfSen 0;
BA_ "GenSigTimeoutMsg_HU_Mid_X451" SG_ 448 PDcHuFrontNoOfSen 0;
BA_ "GenSigTimeoutMsg_HU_High_X451" SG_ 448 PDcHuFrontNoOfSen 0;
BA_ "GenSigTimeoutMsg_HU_B" SG_ 448 PDcHuFrontNoOfSen 0;
BA_ "GenSigTimeoutMsg_HU_A" SG_ 448 PDcHuFrontNoOfSen 0;
BA_ "GenSigSendType" SG_ 448 PDcHuFrontNoOfSen 1;
BA_ "GenSigTimeoutMsg_HU_High_X445" SG_ 448 PDcHuFrontNoOfSen 0;
BA_ "GenSigTimeoutMsg_HU_Mid_X445" SG_ 448 PDcHuFrontNoOfSen 0;
BA_ "GenSigTimeoutTime_HU_High_X445" SG_ 448 PDcHuFrontNoOfSen 0;
BA_ "GenSigTimeoutTime_HU_Mid_X445" SG_ 448 PDcHuFrontNoOfSen 0;
BA_ "GenSigTimeoutMsg_IVI" SG_ 448 PDcHuFrontNoOfSen 0;
BA_ "GenSigTimeoutTime_IVI" SG_ 448 PDcHuFrontNoOfSen 0;
BA_ "GenSigTimeoutTime_HU_Mid_X451" SG_ 448 PDcHuFrontTone 0;
BA_ "GenSigTimeoutTime_HU_High_X451" SG_ 448 PDcHuFrontTone 0;
BA_ "GenSigTimeoutTime_HU_B" SG_ 448 PDcHuFrontTone 0;
BA_ "GenSigTimeoutTime_HU_A" SG_ 448 PDcHuFrontTone 0;
BA_ "GenSigTimeoutMsg_HU_Mid_X451" SG_ 448 PDcHuFrontTone 0;
BA_ "GenSigTimeoutMsg_HU_High_X451" SG_ 448 PDcHuFrontTone 0;
BA_ "GenSigTimeoutMsg_HU_B" SG_ 448 PDcHuFrontTone 0;
BA_ "GenSigTimeoutMsg_HU_A" SG_ 448 PDcHuFrontTone 0;
BA_ "GenSigSendType" SG_ 448 PDcHuFrontTone 1;
BA_ "GenSigTimeoutMsg_HU_High_X445" SG_ 448 PDcHuFrontTone 0;
BA_ "GenSigTimeoutMsg_HU_Mid_X445" SG_ 448 PDcHuFrontTone 0;
BA_ "GenSigTimeoutTime_HU_High_X445" SG_ 448 PDcHuFrontTone 0;
BA_ "GenSigTimeoutTime_HU_Mid_X445" SG_ 448 PDcHuFrontTone 0;
BA_ "GenSigTimeoutMsg_IVI" SG_ 448 PDcHuFrontTone 0;
BA_ "GenSigTimeoutTime_IVI" SG_ 448 PDcHuFrontTone 0;
BA_ "GenSigTimeoutTime_HU_Mid_X451" SG_ 448 PDcHuFrontAudioMuteState 0;
BA_ "GenSigTimeoutTime_HU_High_X451" SG_ 448 PDcHuFrontAudioMuteState 0;
BA_ "GenSigTimeoutTime_HU_B" SG_ 448 PDcHuFrontAudioMuteState 0;
BA_ "GenSigTimeoutTime_HU_A" SG_ 448 PDcHuFrontAudioMuteState 0;
BA_ "GenSigTimeoutMsg_HU_Mid_X451" SG_ 448 PDcHuFrontAudioMuteState 0;
BA_ "GenSigTimeoutMsg_HU_High_X451" SG_ 448 PDcHuFrontAudioMuteState 0;
BA_ "GenSigTimeoutMsg_HU_B" SG_ 448 PDcHuFrontAudioMuteState 0;
BA_ "GenSigTimeoutMsg_HU_A" SG_ 448 PDcHuFrontAudioMuteState 0;
BA_ "GenSigSendType" SG_ 448 PDcHuFrontAudioMuteState 1;
BA_ "GenSigTimeoutMsg_HU_High_X445" SG_ 448 PDcHuFrontAudioMuteState 0;
BA_ "GenSigTimeoutMsg_HU_Mid_X445" SG_ 448 PDcHuFrontAudioMuteState 0;
BA_ "GenSigTimeoutTime_HU_High_X445" SG_ 448 PDcHuFrontAudioMuteState 0;
BA_ "GenSigTimeoutTime_HU_Mid_X445" SG_ 448 PDcHuFrontAudioMuteState 0;
BA_ "GenSigTimeoutMsg_IVI" SG_ 448 PDcHuFrontAudioMuteState 0;
BA_ "GenSigTimeoutTime_IVI" SG_ 448 PDcHuFrontAudioMuteState 0;
BA_ "GenSigTimeoutTime_HU_Mid_X451" SG_ 448 RVcImageRotationType 0;
BA_ "GenSigTimeoutTime_HU_High_X451" SG_ 448 RVcImageRotationType 0;
BA_ "GenSigTimeoutTime_HU_B" SG_ 448 RVcImageRotationType 0;
BA_ "GenSigTimeoutTime_HU_A" SG_ 448 RVcImageRotationType 0;
BA_ "GenSigTimeoutMsg_HU_Mid_X451" SG_ 448 RVcImageRotationType 0;
BA_ "GenSigTimeoutMsg_HU_High_X451" SG_ 448 RVcImageRotationType 0;
BA_ "GenSigTimeoutMsg_HU_B" SG_ 448 RVcImageRotationType 0;
BA_ "GenSigTimeoutMsg_HU_A" SG_ 448 RVcImageRotationType 0;
BA_ "GenSigSendType" SG_ 448 RVcImageRotationType 1;
BA_ "GenSigTimeoutMsg_HU_High_X445" SG_ 448 RVcImageRotationType 0;
BA_ "GenSigTimeoutMsg_HU_Mid_X445" SG_ 448 RVcImageRotationType 0;
BA_ "GenSigTimeoutTime_HU_High_X445" SG_ 448 RVcImageRotationType 0;
BA_ "GenSigTimeoutTime_HU_Mid_X445" SG_ 448 RVcImageRotationType 0;
BA_ "GenSigTimeoutMsg_IVI" SG_ 448 RVcImageRotationType 0;
BA_ "GenSigTimeoutTime_IVI" SG_ 448 RVcImageRotationType 0;
BA_ "GenSigTimeoutTime_HU_Mid_X451" SG_ 448 RVcOverlayType 0;
BA_ "GenSigTimeoutTime_HU_High_X451" SG_ 448 RVcOverlayType 0;
BA_ "GenSigTimeoutTime_HU_B" SG_ 448 RVcOverlayType 0;
BA_ "GenSigTimeoutTime_HU_A" SG_ 448 RVcOverlayType 0;
BA_ "GenSigTimeoutMsg_HU_Mid_X451" SG_ 448 RVcOverlayType 0;
BA_ "GenSigTimeoutMsg_HU_High_X451" SG_ 448 RVcOverlayType 0;
BA_ "GenSigTimeoutMsg_HU_B" SG_ 448 RVcOverlayType 0;
BA_ "GenSigTimeoutMsg_HU_A" SG_ 448 RVcOverlayType 0;
BA_ "GenSigSendType" SG_ 448 RVcOverlayType 1;
BA_ "GenSigTimeoutMsg_HU_High_X445" SG_ 448 RVcOverlayType 0;
BA_ "GenSigTimeoutMsg_HU_Mid_X445" SG_ 448 RVcOverlayType 0;
BA_ "GenSigTimeoutTime_HU_High_X445" SG_ 448 RVcOverlayType 0;
BA_ "GenSigTimeoutTime_HU_Mid_X445" SG_ 448 RVcOverlayType 0;
BA_ "GenSigTimeoutMsg_IVI" SG_ 448 RVcOverlayType 0;
BA_ "GenSigTimeoutTime_IVI" SG_ 448 RVcOverlayType 0;
BA_ "GenSigTimeoutTime_HU_Mid_X451" SG_ 451 OdoICFullSig 0;
BA_ "GenSigTimeoutTime_HU_High_X451" SG_ 451 OdoICFullSig 0;
BA_ "GenSigTimeoutTime_HU_B" SG_ 451 OdoICFullSig 0;
BA_ "GenSigTimeoutTime_HU_A" SG_ 451 OdoICFullSig 0;
BA_ "GenSigTimeoutMsg_HU_Mid_X451" SG_ 451 OdoICFullSig 0;
BA_ "GenSigTimeoutMsg_HU_High_X451" SG_ 451 OdoICFullSig 0;
BA_ "GenSigTimeoutMsg_HU_B" SG_ 451 OdoICFullSig 0;
BA_ "GenSigTimeoutMsg_HU_A" SG_ 451 OdoICFullSig 0;
BA_ "GenSigSendType" SG_ 451 OdoICFullSig 2;
BA_ "GenSigTimeoutMsg_HU_High_X445" SG_ 451 OdoICFullSig 0;
BA_ "GenSigTimeoutMsg_HU_Mid_X445" SG_ 451 OdoICFullSig 0;
BA_ "GenSigTimeoutTime_HU_High_X445" SG_ 451 OdoICFullSig 0;
BA_ "GenSigTimeoutTime_HU_Mid_X445" SG_ 451 OdoICFullSig 0;
BA_ "GenSigTimeoutMsg_IVI" SG_ 451 OdoICFullSig 0;
BA_ "GenSigTimeoutTime_IVI" SG_ 451 OdoICFullSig 0;
VAL_ 461 HuBCmWindowWindingHmiCmdReq 15 "Reserved" 14 "Reserved" 13 "Reserved" 12 "Reserved" 11 "Reserved" 10 "Rear Left Window Open" 9 "Rear Left Window Close" 8 "Rear Right Window Open	" 7 "Rear Right Window Close" 6 "Front Left Window Open" 5 "Front Left Window Close" 4 "Front Right Window Open" 3 "Front Right Window Close" 2 "Window Open" 1 "Window Close" 0 "No Command" ;
VAL_ 461 HuBCmTyreTempHmiVrCmdReq 7 "Reserved" 6 "Spare Tyre Temperature" 5 "Rear Left Tyre Temperature" 4 "Rear Right Tyre Temperature" 3 "Front Left Tyre Temperature" 2 "Front Right Tyre Temperature" 1 "All Tyre Temperature" 0 "No Command" ;
VAL_ 461 HuBCmTyrePressureHmiVrCmdReq 7 "Reserved" 6 "Spare Tyre Pressure" 5 "Rear Left Tyre Pressure" 4 "Rear Right Tyre Pressure" 3 "Front Left Tyre Pressure" 2 "Front Right Tyre Pressure" 1 "All Tyre Pressure" 0 "No Command" ;
VAL_ 461 HuBCmRoofLampHmiVrCmdReq 3 "Query Current State" 2 "ON" 1 "OFF" 0 "No Command" ;
VAL_ 461 HuBCmPositionLampVrCmdReq 3 "Query Current State" 2 "ON" 1 "OFF" 0 "No Command" ;
VAL_ 461 HuBCmORVMHmiVrCmdReq 15 "Reserved" 14 "Reserved" 13 "Reserved" 12 "Third Memory Recall" 11 "Second Memory Recall" 10 "First Memory Recall" 9 "Third Memory Set" 8 "Second Memory Set" 7 "First Memory Set" 6 "Left Mirror Unfold" 5 "Left Mirror Fold" 4 "Right Mirror Unfold" 3 "Right Mirror Fold" 2 "ORVM Unfold" 1 "ORVM Fold" 0 "No Command" ;
VAL_ 461 HuBCmMoodLightVrCmdReq 3 "Query Current State" 2 "ON" 1 "OFF" 0 "No Command" ;
VAL_ 461 HuBCmHazardLampVrCmdReq 3 "Query Current State" 2 "ON" 1 "OFF" 0 "No Command" ;
VAL_ 461 HuBCmDRLVrCmdReq 3 "Query Current State" 2 "ON" 1 "OFF" 0 "No Command" ;
VAL_ 461 HuBCmAmbientLightVrCmdReq 3 "Query Current State" 2 "ON" 1 "OFF" 0 "No Command" ;
VAL_ 461 HuBCmTiltVrCmdReq 3 "Query Current State" 2 "Open" 1 "Close" 0 "No Command" ;
VAL_ 461 HuBCmSunShadeVrCmdReq 3 "Query Current State" 2 "Open" 1 "Close" 0 "No Command" ;
VAL_ 461 HuBCmSunRoofVrCmdReq 3 "Query Current State" 2 "Close" 1 "Open" 0 "No Command" ;
VAL_ 489 BCmHuWindowWindingHmiCmdSupport 1 "Supported" 0 "Not Supported" ;
VAL_ 489 BCmHuTyreTempVrCmdSupport 1 "Supported" 0 "Not Supported" ;
VAL_ 489 BCmHuTyreTempHmiCmdSupport 1 "Supported" 0 "Not Supported" ;
VAL_ 489 BCmHuTyrePressureVrCmdSupport 1 "Supported" 0 "Not Supported" ;
VAL_ 489 BCmHuTyrePressureHmiCmdSupport 1 "Supported" 0 "Not Supported" ;
VAL_ 489 BCmHuSunroofTiltVrCmdSupport 1 "Supported" 0 "Not Supported" ;
VAL_ 489 BCmHuRoofLampVrCmdSupport 1 "Supported" 0 "Not Supported" ;
VAL_ 489 BCmHuRoofLampHmiCmdSupport 1 "Supported" 0 "Not Supported" ;
VAL_ 489 BCmHuPositionLampVrCmdSupport 1 "Supported" 0 "Not Supported" ;
VAL_ 489 BCmHuORVMVrCmdSupport 1 "Supported" 0 "Not Supported" ;
VAL_ 489 BCmHuORVMHmiCmdSupport 1 "Supported" 0 "Not Supported" ;
VAL_ 489 BCmHuMoodLightVrCmdSupport 1 "Supported" 0 "Not Supported" ;
VAL_ 489 BCmHuHazardLampVrCmdSupport 1 "Supported" 0 "Not Supported" ;
VAL_ 489 BCmHuDRLVrCmdSupport 1 "Supported" 0 "Not Supported" ;
VAL_ 489 BCmHuAmbientLightVrCmdSupport 1 "Supported" 0 "Not Supported" ;
VAL_ 489 BCmHuSunShadeVrCmdSupport 1 "Supported" 0 "Not Supported" ;
VAL_ 489 BCmHuSunRoofVrCmdSupport 1 "Supported" 0 "Not Supported" ;
VAL_ 458 BCmHuWindowWindingHmiCmdAck 31 "Reserved" 30 "Reserved" 29 "Reserved" 28 "Reserved" 27 "Reserved" 26 "Reserved" 25 "Reserved" 24 "Reserved" 23 "Reserved" 22 "Rear Left Window is already Opened" 21 "Rear Left Window is already Closed" 20 "Rear Left Window is Opening" 19 "Rear Left Window is Closing" 18 "Rear Right Window is already Opened" 17 "Rear Right Window is already Closed" 16 "Rear Right Window is Opening" 15 "Rear Right Window is Closing" 14 "Front Left Window is already Opened" 13 "Front Left Window is already Closed" 12 "Front Left Window is Opening" 11 "Front Left Window is Closing" 10 "Front Right Window is already Opened" 9 "Front Right Window is already Closed" 8 "Front Right Window is Opening" 7 "Front Right Window is Closing" 6 "All Windows are already Opened" 5 "All Windows are already Closed" 4 "All Windows are Opening" 3 "All Windows are Closing" 2 "Issue with Window Winding" 1 "Not supported (TBD)request" 0 "No Action Required" ;
VAL_ 458 BCmHuTyreTempHmiVrCmdAck 15 "Reserved" 14 "Reserved" 13 "Reserved" 12 "Rear Left Tyre Temperature Not Ok" 11 "Rear Left Tyre Temperature Ok" 10 "Rear Right Tyre Temperature Not Ok" 9 "Rear Right Tyre Temperature Ok" 8 "Front Left Tyre Temperature Not Ok" 7 "Front Left Tyre Temperature Ok" 6 "Front Right Tyre Temperature Not Ok" 5 "Front Right Tyre Temperature Ok" 4 "One or more Tyre Temperature Not Ok" 3 "All Tyres Temperature Ok" 2 "Issue with Tyre Temperature reading" 1 "Not supported (TBD)request" 0 "No Action Required" ;
VAL_ 458 BCmHuTyrePressureHmiVrCmdAck 15 "Reserved" 14 "Reserved" 13 "Reserved" 12 "Rear Left Tyre Pressure Not Ok" 11 "Rear Left Tyre Pressure Ok" 10 "Rear Right Tyre Pressure Not Ok" 9 "Rear Right Tyre Pressure Ok" 8 "Front Left Tyre Pressure Not Ok" 7 "Front Left Tyre Pressure Ok " 6 "Front Right Tyre Pressure Not Ok" 5 "Front Right Tyre Pressure Ok" 4 "One or more Tyre Pressure Not Ok" 3 "All Tyres Pressure Ok" 2 "Issue with Tyre Pressure reading" 1 "Not supported (TBD)request" 0 "No Action Required" ;
VAL_ 458 BCmHuRoofLampHmiVrCmdAck 15 "Reserved" 14 "Reserved" 13 "Reserved" 12 "Reserved" 11 "Roof lamp cannot operate due to vehicle crash detected" 10 "Request for all Door closed to operate Roof lamp through Voice command" 9 "Roof lamp Auto switch request" 8 "Roof lamp is ON" 7 "Roof lamp is OFF" 6 "Roof lamp is already turned ON" 5 "Roof lamp is turned ON" 4 "Roof lamp is already turned OFF" 3 "Roof lamp is turned OFF" 2 "Issue with Roof lamp" 1 "Not supported (TBD)request" 0 "No Action Required" ;
VAL_ 458 BCmHuPositionLampVrCmdAck 15 "Reserved" 14 "Reserved" 13 "Reserved" 12 "Reserved" 11 "Reserved" 10 "Reserved" 9 "Position lamp turned OFF through Switch only" 8 "Position lamp is ON" 7 "Position lamp is OFF" 6 "Position lamp is already turned ON" 5 "Position lamp is turned ON" 4 "Position lamp is already turned OFF" 3 "Position lamp is turned OFF" 2 "Issue with Position lamp" 1 "Not supported (TBD)request" 0 "No Action Required" ;
VAL_ 458 BCmHuORVMHmiVrCmdAck 31 "Reserved" 30 "Reserved" 29 "Reserved" 28 "Reserved" 27 "Reserved" 26 "Reserved" 25 "Reserved" 24 "Reserved" 23 "Reserved" 22 "Reserved" 21 "Reserved" 20 "Left ORVM already Unfolded" 19 "Left ORVM already Folded" 18 "Right ORVM already Unfolded" 17 "Right ORVM already Folded" 16 "Left & Right both ORVM already Unfolded" 15 "Left & Right both ORVM already Folded" 14 "ORVM is adjusting as per Third Memory set" 13 "ORVM is adjusting as per Second Memory set" 12 "ORVM is adjusting as per First Memory set" 11 "Present ORVM setting is stored in Third Memory set" 10 "Present ORVM setting is stored in Second Memory set" 9 "Present ORVM setting is stored in First Memory set" 8 "Left ORVM is Unfolding" 7 "Left ORVM is Folding" 6 "Right ORVM is Unfolding" 5 "Right ORVM is Folding" 4 "Left & Right ORVM are Unfolding" 3 "Left & Right ORVM are Folding" 2 "Issue with ORVM" 1 "Not supported (TBD)request" 0 "No Action Required" ;
VAL_ 458 BCmHuMoodLightVrCmdAck 15 "Reserved" 14 "Reserved" 13 "Reserved" 12 "Reserved" 11 "Reserved" 10 "Reserved" 9 "Reserved" 8 "Mood light is ON" 7 "Mood light is OFF" 6 "Mood light is already turned ON" 5 "Mood light is turned ON" 4 "Mood light is already turned OFF" 3 "Mood light is turned OFF" 2 "Issue with Mood light" 1 "Not supported (TBD)request" 0 "No Action Required" ;
VAL_ 458 BCmHuHazardLampVrCmdAck 15 "Reserved" 14 "Reserved" 13 "Reserved" 12 "Reserved" 11 "Reserved" 10 "Reserved" 9 "Unable to operate Hazard lamp due to load activated by other feature" 8 "Hazard lamp is ON" 7 "Hazard lamp is OFF" 6 "Hazard lamp is already turned ON" 5 "Hazard lamp is turned ON" 4 "Hazard lamp is already turned OFF" 3 "Hazard lamp is turned OFF" 2 "Issue with Hazard lamp" 1 "Not supported (TBD)request" 0 "No Action Required" ;
VAL_ 458 BCmHuDRLVrCmdAck 15 "Reserved" 14 "Reserved" 13 "Reserved" 12 "Reserved" 11 "Reserved" 10 "Reserved" 9 "DRL lamp turned OFF through Switch only" 8 "DRL lamp is ON" 7 "DRL lamp is OFF" 6 "DRL lamp is already turned ON / Activated." 5 "DRL lamp is turned ON / Activate." 4 "DRL lamp is already turned OFF / Deactivated." 3 "DRL lamp is turned OFF / Deactivate" 2 "Issue with DRL lamp" 1 "Not supported (TBD)request" 0 "No Action Required" ;
VAL_ 458 BCmHuAmbientLightVrCmdAck 15 "Reserved" 14 "Reserved" 13 "Reserved" 12 "Reserved" 11 "Reserved" 10 "Reserved" 9 "Reserved" 8 "Ambient light is ON" 7 "Ambient light is OFF" 6 "Ambient light is already turned ON" 5 "Ambient light is turned ON" 4 "Ambient light is already turned OFF" 3 "Ambient light is turned OFF" 2 "Issue with Ambient light" 1 "Not supported (TBD)request" 0 "No Action Required" ;
VAL_ 458 BCmHuTiltVrCmdAck 15 "Reserved " 14 "Reserved " 13 "Reserved " 12 "Current State is Sunroof Tilt Opened" 11 "Current State is Sunroof Tilt Closed" 10 "Unable to execute Tilt Open / Close, because Sunroof is open" 9 "Sunroof Tilt is stuck" 8 "Unable to Tilt open the Sunroof" 7 "Sunroof is already tilted opened" 6 "Tilting Open the Sunroof" 5 "Unable to Tilt close the Sunroof" 4 "Sunroof is already tilted closed" 3 "Tilting Close the Sunroof" 2 "Unknown Error" 1 "Not supported (TBD)" 0 "No Action Required" ;
VAL_ 458 BCmHuSunShadeVrCmdAck 15 "Reserved " 14 "Reserved " 13 "Reserved " 12 "Current State is Sunshade Opened " 11 "Current State is Sunshade Closed " 10 "Unable to Close Sunshade, because Sunroof is open" 9 "Sunshade is stuck" 8 "Unable to open the Sunshade" 7 "Sunshade is already opened" 6 "Opening the Sunshade" 5 "Unable to close the Sunshade" 4 "Sunshade is already closed" 3 "Closing the Sunshade" 2 "Unknown Error" 1 "Not supported (TBD)" 0 "No Action Required" ;
VAL_ 458 BCmHuSunRoofVrCmdAck 15 "Reserved " 14 "Reserved " 13 "Reserved " 12 "Reserved " 11 "Current State is Sunroof Opened " 10 "Current State is Sunroof Closed" 9 "Sunroof is stuck" 8 "Unable to open the Sunroof" 7 "Sunroof is already opened" 6 "Opening the Sunroof" 5 "Unable to close the Sunroof" 4 "Sunroof is already Closed" 3 "Closing the Sunroof" 2 "Unknown Error" 1 "Not supported (TBD)" 0 "No Action Required" ;
VAL_ 567 APbState 15 "Reserved" 14 "Reserved" 13 "Reserved" 12 "Failure -both MoC applied" 11 "Failure -one MoC applied" 10 "Failure -both MoC released" 9 "Unknown" 8 "APB Auto release not possible- Driver seat belt unbuckled/ Driver door open" 7 "No Action" 6 "APB cannot hold the vehicle-Slope too high" 5 "Dynamic APB apply" 4 "Locking" 3 "Releasing" 2 "Closed" 1 "Released" 0 "Static Relaese not possible Brake not pressed		

" ;
VAL_ 960 DateTimeStatus 3 "SNA" 2 "Implausible" 1 "Reserved" 0 "Plausible" ;
VAL_ 582 SILTelltaleVcuStatus 3 "Reserved" 2 "Information given is implausible due to a detected failure " 1 "Reserved" 0 "Information given correct and according to specification" ;
VAL_ 582 SILTelltaleVcu 7 "Reserved	" 6 "Reserved	" 5 "Reserved	" 4 "SIL Telltale Lamp Red Color On" 3 "SIL Telltale Lamp Red Color Blink" 2 "SIL Telltale Lamp Orange Color On" 1 "SIL Telltale Lamp Orange Color Blink" 0 "SIL Telltale Lamp  off" ;
VAL_ 582 AvgEnergyConsmpTripBStatus 3 "Signal Not Available" 2 "Information given is implausible due to a detected failure" 1 "Reserved" 0 "Information given is correct and according to specification" ;
VAL_ 582 AvgEnergyConsmpTripAStatus 3 "Signal Not Available" 2 "Information given is implausible due to a detected failure" 1 "Reserved" 0 "Information given is correct and according to specification" ;
VAL_ 582 AvgEnergyConsmpTripB 511 "Information Initialization in progress due to Reset" ;
VAL_ 582 AvgEnergyConsmpTripA 511 "Information Initialization in progress due to Reset" ;
VAL_ 582 InstPwrConsumpStatus 3 "Signal Not Available" 2 "Information given is implausible" 1 "Reserved" 0 "Information given is correct" ;
VAL_ 582 InstPwrConsump 255 "Information Initialization in progress due to Reset" ;
VAL_ 719 ComfortState 1 "Comfort level reached" 0 "Comfort level not reached" ;
VAL_ 719 ComfortStateStatus 3 "Signal not available" 2 "Implausible" 1 "Reserved for future use" 0 "Plausible and signal is correct" ;
VAL_ 493 CarAnniversary 1 "Display message It's your car's Birthday. Congratulations!" 0 "No trigger" ;
VAL_ 493 OwnersAnniversary 1 "Display message Happy Marriage Anniversary!" 0 "No trigger" ;
VAL_ 493 OwnersBirthday 1 "Display message Happy Birthday" 0 "No trigger" ;
VAL_ 581 HvChargeTypeStatus_VCAN 3 "Reserved for Future use" 2 "Signal is implausible" 1 "Reserved for Future use" 0 "Signal is plausible" ;
VAL_ 581 HvChargeType_VCAN 3 "AC Fast Charging" 2 "V2V/V2L" 1 "Fast Charging" 0 "Normal Charging" ;
VAL_ 581 HvChargingStateStatus_VCAN 3 "Signal Not Available" 2 "Signal is implausible" 1 "Reserved for Future use" 0 "Signal is plausible" ;
VAL_ 581 HvChargingState_VCAN 7 "Reserved" 6 "Reserved" 5 "Reserved" 4 "Charger Connection lamp Red color  Blink" 3 "Charger Connection lamp Red color  ON" 2 "Charger Connection lamp Green color  Blink" 1 "Charger Connection lamp Green color  ON" 0 "Charger Connection lamp is OFF. " ;
VAL_ 581 TimetoChargeHVMintsStatus_VCAN 3 "Reserved" 2 "Information given is implausible due to a detected failure" 1 "Reserved" 0 "Information given is correct and according to specification" ;
VAL_ 581 TimetoChargeHVHoursStatus_VCAN 3 "Reserved" 2 "Information given is implausible due to a detected failure" 1 "Reserved" 0 "Information given is correct and according to specification" ;
VAL_ 581 CabinCoolingSolValveStateStatus 3 "Reserved" 2 "Information given is implausible due to a detected failure " 1 "Reserved" 0 "Information given correct and according to specification" ;
VAL_ 581 CabinCoolingSolValveState 3 "Reserved" 2 "Cabin Cooling SV is ON" 1 "Reserved" 0 "Cabin Cooling SV is OFF" ;
VAL_ 581 LowHVBatteryChargeStatus_VCAN 3 "Reserved" 2 "Information given is implausible due to a detected failure" 1 "Reserved" 0 "Information given is correct and according to specification" ;
VAL_ 581 LowHVBatteryCharge_VCAN 3 " Reserved for future use" 2 "Low HV Battery Charge lamp ON" 1 "Low HV Battery Charge lamp Flashing" 0 "Low HV Battery Charge lamp is OFF. " ;
VAL_ 581 LowLVBatteryChargeStatus_VCAN 3 "Reserved" 2 "Information given is implausible due to a detected failure" 1 "Reserved" 0 "Information given is correct and according to specification" ;
VAL_ 581 LowLVBatteryCharge_VCAN 3 " Reserved for future use" 2 "Low LV Battery Charge lamp ON" 1 "Low LV Battery Charge lamp Flashing" 0 "Low LV Battery Charge lamp is OFF. " ;
VAL_ 581 HvAmpHrStatus 3 "Reserved" 2 "Information  is implausible due to a detected failure " 1 "Reserved" 0 "Information is correct and accord to specification" ;
VAL_ 724 HeatingPwrValStatus 3 "Signal not available" 2 "Implausible" 1 "Reserved for future use" 0 "Plausible and signal is correct" ;
VAL_ 724 CoolingPwrValStatus 3 "Signal not available" 2 "Implausible" 1 "Reserved for future use" 0 "Plausible and signal is correct" ;
VAL_ 724 AcReqNew 1 "AC request from driver activated" 0 "AC Request from driver deactivated" ;
VAL_ 408 ICDispSpeedSigStatus 3 "Reserved" 2 "Implausible -Information given at ICDispSpeedSig is implausible" 1 "Reserved for future use" 0 "Plausible-Informationgiveniscorrectandaccordingtospecification" ;
VAL_ 738 TurnInputSwStateInfoStatus 3 "Signal Not Available(SNA)" 2 "Implausible" 1 "Reserved" 0 "Plausible" ;
VAL_ 738 TurnInputSwStateInfo 3 "RH turn indicator switch is turnned ON" 2 "LH turn indicator switch is turnned ON" 1 "Turn indicator switch is turnned OFF" 0 "Don't Care " ;
VAL_ 738 RemoteUsecaseStateStatus 3 "Signal not available" 2 "Signal is implausible" 1 "Reserved for future use." 0 "Signal is correct" ;
VAL_ 738 RemoteUsecaseState 3 "Remote Use case is ON" 2 "Reserved" 1 "Remote Use case is OFF with Normal Running Mode ON  " 0 "Remote Use case is OFF" ;
VAL_ 738 HornStateStatus 3 "Reserved" 2 "Information given is implausible due to a detected failure " 1 "Reserved" 0 "Information given is correct" ;
VAL_ 738 HornState 1 "Horn is  Acive " 0 "Horn is  Not Acive " ;
VAL_ 738 ForcePanicStatus 1 "Force Panic  Active" 0 "Force panic Not Active" ;
VAL_ 738 ApprochLampStateStatus 3 "Signal Not Available" 2 "Signal is implausible" 1 "Reserved for future use" 0 "Plausible  - Information given is correct" ;
VAL_ 738 ApprochLampState 1 "ApprochLamp ON" 0 "ApprochLamp OFF" ;
VAL_ 738 LowBeamTellTaleStatus 3 "Signal LowBeamTelltale Not Available" 2 "Reserved for future use" 1 "Reserved for future use" 0 "Plausible  and Signal is correct" ;
VAL_ 738 LowBeamTellTale 1 "Low Beam ON" 0 "Low Beam OFF" ;
VAL_ 738 IntrusionInfoStateStatus 3 "Signal Not Available" 2 "Reserved for future use." 1 "Reserved for future use." 0 "Plausible-Information is correct and according to specification" ;
VAL_ 738 IntrusionInfoState 1 "Perimetric alarm ON" 0 "Perimetric alarm OFF" ;
VAL_ 738 HazardLampState 1 "Hazard Lamp On" 0 "Hazard Lamp off" ;
VAL_ 738 HazardLampStateStatus 3 "Signal Not Available" 2 "Signal is implausible" 1 "Reserved for future use." 0 "Signal is plausible" ;
VAL_ 738 VehicleSecured 1 "Secured" 0 "Not Secured" ;
VAL_ 738 VehicleSecuredStatus 3 "Signal Not Available" 2 "Signal is implausible" 1 "Reserved for future use." 0 "Plausible-Informationgiveniscorrectandaccordingtospecification" ;
VAL_ 495 RemoteHornCmdStatus 3 "Signal Not Available" 2 "Signal is Implausible" 1 "Don't Care " 0 "Plausible  - Information given is correct" ;
VAL_ 495 RemoteHornCmd 1 "Remote horn requested" 0 "Remote horn not requested" ;
VAL_ 495 RemoteApprochLmpCmdStatus 3 "Signal Not Available" 2 "Signal is implausible" 1 "Don't Care " 0 "Plausible  - Information given is correct" ;
VAL_ 495 RemoteApprochLmpCmd 1 "Turn On Approch lamp" 0 "Turn Off Approch lamp" ;
VAL_ 495 RemoteValetCmdStatus 3 "Signal not available" 2 "Signal is implausible" 1 "Don't Care " 0 "Plausible and signal is correct" ;
VAL_ 495 RemoteValetCmd 1 "valet Command enable" 0 "Valet command Disable" ;
VAL_ 495 RemoteAcTempSetStatus 3 "Signal Not Available" 2 "Signal is Implausible" 1 "Don't Care " 0 "Plausible and signal is correct" ;
VAL_ 495 RemoteAcTempSet 31 "Reserved" 30 "HI" 29 "30" 28 "29.5" 27 "29" 26 "28.5" 25 "28" 24 "27.5" 23 "27" 22 "26.5" 21 "26" 20 "25.5" 19 "25" 18 "24.5" 17 "24" 16 "23.5" 15 "23" 14 "22.5" 13 "22" 12 "21.5" 11 "21" 10 "20.5" 9 "20" 8 "19.5" 7 "19" 6 "18.5" 5 "18" 4 "LO" 3 "Reserved" 2 "Reserved" 1 "Reserved" 0 "Reserved" ;
VAL_ 495 RemoteAcCmd 1 "Turn On AC" 0 "Turn Off AC" ;
VAL_ 495 RemoteAcCmdStatus 3 "Signal Not Available" 2 "Signal is Implausible" 1 "Don't Care " 0 "Plausible and signal is correct" ;
VAL_ 495 RemoteImmoReqStatus 3 "Signal Not Available" 2 "Signal is Implausible" 1 "Don't Care " 0 "Plausible and signal is correct" ;
VAL_ 495 RemoteImmoReq 3 "Reserved" 2 "Immobilize request" 1 "Mobilize request" 0 "No request" ;
VAL_ 495 TowInfoStatus 3 "Signal Not Available" 2 "Reserved for future use." 1 "Don't Care " 0 "Plausible -Information is correct and according to specification" ;
VAL_ 495 TowInfo 1 "Tow occurred" 0 "Tow not occurred" ;
VAL_ 495 ParkingCollisionInfoStatus 3 "Signal Not Available" 2 "Signal is implausible" 1 "Don't Care " 0 "Plausible -Information is correct and according to specification" ;
VAL_ 495 ParkingCollisionInfo 1 "Parking collision occured" 0 "Parking collision not occured" ;
VAL_ 495 RemotePositionCmdStatus 3 "Signal Not Available" 2 "Signal is implausible" 1 "Don't Care " 0 "Plausible-Information is correct and according to specification" ;
VAL_ 495 RemotePositionCmd 1 "Turn ON Position Lamp" 0 "Turn Off Position Lamp" ;
VAL_ 495 RemoteHazardCmdStatus 3 "Signal Not Available" 2 "Signal is implausible" 1 "Don't Care " 0 "Plausible -Informationgiveniscorrectandaccordingtospecification" ;
VAL_ 495 RemoteHazardCmd 1 "Turn ON Hazard Lamp" 0 "Turn Off Hazard Lamp" ;
VAL_ 495 RemoteVehicleUnlockCmdStatus 3 "Signal Not Available" 2 "Signal is implausible" 1 "Don't Care " 0 "Plausible-Information is correct and according to specification" ;
VAL_ 495 RemoteVehicleUnlockCmd 1 "Vehicle unlock request received" 0 "Vehicle unlock request not received" ;
VAL_ 495 RemoteVehicleLockCmdStatus 3 "Signal Not Available" 2 "Signal is implausible" 1 "Don't Care " 0 "Plausible-Information is correct and according to specification" ;
VAL_ 495 RemoteVehicleLockCmd 1 "Vehicle lock request received" 0 "Vehicle lock request not received" ;
VAL_ 580 BrakePaddlePosVcuStatus 3 "Signal Not available" 2 "BrakePaddlePosVcu signal Value is implausible" 1 "Reserved" 0 "Information given by BrakePaddlePosVcu is correct and according to specification" ;
VAL_ 580 HVBattSoCPercenStatus_VCAN 3 "Reserved" 2 "Information given is implausible due to a detected failure" 1 "Reserved" 0 "Information given is correct and according to specification" ;
VAL_ 580 DTeInfoStatus_VCAN 3 "Reserved" 2 "Information given is implausible due to a detected failure" 1 "Reserved" 0 "Information given is correct and according to specification" ;
VAL_ 580 VehicleStatus 7 "Reserved" 6 "Reserved" 5 "Reserved" 4 "Reserved" 3 "EV System Disengaged" 2 "Not Ready to Go,  HV System Not Ready" 1 "Not Ready to Go, Charger Connected" 0 "Ready to Go" ;
VAL_ 580 VcuStatus 1 "VCU Malfunction" 0 "VCU Normal" ;
VAL_ 580 ValetStateStatus 3 "Signal not available" 2 "Signal is implausible" 1 "Reserved for future use" 0 "Plausible and signal is correct" ;
VAL_ 580 ValetState 1 "Valet State Mode On" 0 "Valet State Mode OFF" ;
VAL_ 580 AcComprMalFn 1 "AC Compressor Malfunction" 0 "AC Compressor Normal" ;
VAL_ 580 AcCmprStatusVcu 1 "AC Compressor is On" 0 "AC Compressor is Off" ;
VAL_ 580 VcuPowerMode_VCAN 15 "Reserved" 14 "Reserved" 13 "Reserved" 12 "Reserved" 11 "Reserved" 10 "Reserved" 9 "Reserved" 8 "Reserved" 7 "Discharging Mode for V2V/V2L" 6 "Limited power mode" 5 "Charging mode" 4 "Energy Recuperation" 3 "Normal Run" 2 "Crank" 1 "Active" 0 "Awake" ;
VAL_ 580 VcuPowerModeStatus_VCAN 3 "Reserved" 2 "Information given is implausible due to a detected failure" 1 "Reserved" 0 "Information given is correct and according to specification" ;
VAL_ 579 VcuHazardLampReqStatus 3 "Reserved" 2 "Information given is implausible due to a detected failure" 1 "Reserved" 0 "Information given correct and according to specification" ;
VAL_ 579 VcuHazardLampReq 1 "Request to activate Hazard Lamp" 0 "No Request for Hazard Lamp" ;
VAL_ 579 VCuPresence 1 "Reserved" 0 "VCU is present" ;
VAL_ 579 BrkVacPumpStatus 1 "Brake Vaccum Pump Malfunction" 0 "Brake Vaccum Pump Normal" ;
VAL_ 579 DriveMotorStatus 1 "Drive Motor Malfunction" 0 "Drive Motor  Normal" ;
VAL_ 579 HvBattSoh 1 "HV Batt SOH Not OK" 0 "HV Batt SOH OK" ;
VAL_ 579 HvBattPackVolStatus 3 "Reserved" 2 "Information is implausible due to a detected failure " 1 "Reserved" 0 "Information is correct and according to specification" ;
VAL_ 579 AvgEnergyConsmption 511 "Information Initialization in progress due to Reset" ;
VAL_ 579 AvgEnergyConsmptionStatus 3 "Signal Not Available" 2 "Information given is implausible due to a detected failure" 1 "Reserved" 0 "Information given is correct and according to specification" ;
VAL_ 579 MotorHightempStatus 3 "Reserved" 2 "Information given is implausible due to a detected failure" 1 "Reserved" 0 "Information given is correct and according to specification" ;
VAL_ 579 MotorHightemp 3 " Reserved for future use" 2 "Motor Temp lamp ON" 1 "Motor Temp lamp Flashing" 0 "Motor Temp lamp is OFF. " ;
VAL_ 579 VcuGearSelectionChangeTxt 3 "Low SoC, Sports mode De-Activated" 2 "Gear Selections selection is not possible due to System failure" 1 "Press The Brake for Gear selection " 0 "Gear selection possible" ;
VAL_ 579 ImmoStatusVcu 1 "VCU is immobilized" 0 "VCU is mobilized" ;
VAL_ 579 ClntTempVcuStatus 3 "Reserved for future use" 2 "Value is implausible" 1 "Reserved for future use" 0 "ClntTemp signal is correct" ;
VAL_ 579 GearForDisplayVcu 15 "Information Initialization in progress" 14 "Reserved" 13 "Reserved" 12 "Reserved" 11 "Reserved" 10 "Reserved" 9 "Reserved" 8 "Reserved" 7 "Reserved" 6 "Reserved" 5 "Sport" 4 "Forward/Drive" 3 "Neutral" 2 "Reverse" 1 "Park" 0 "Not Used" ;
VAL_ 579 GearForDisplayVcuStatus 3 "Signal Not Available" 2 "Information given is implausible due to a detected failure" 1 "Reserved" 0 "Information given correct and according to specification" ;
VAL_ 273 AccPedPosnVcuStatus 3 "Reserved" 2 "Information given is implausible" 1 "Reserved" 0 "Information given is correct" ;
VAL_ 273 BrkPressStateVcu 1 "Brake is not pressed" 0 "Brake is pressed" ;
VAL_ 273 BrkPressStatusVcu 3 "Reserved" 2 "Information given is implausible due to a detected failure" 1 "Reserved" 0 "Information given is correct and according to specification" ;
VAL_ 259 CrashoutputSignal 16 "Left hand side deploy crash" 8 "Right hand side deploy crash" 4 "Rear Crash" 2 "Front Deploy Crash" 1 "No Fire Crash" 0 "No Crash" ;
VAL_ 259 FrPassSBRIndication 1 "Indicator ON" 0 "Indicator OFF" ;
VAL_ 259 SRSWarningLamp 1 "AWL ON" 0 "AWL OFF" ;
VAL_ 277 SteerAngEPAsDir 1 "Counter Clockwise Direct" 0 "Clockwise Direction" ;
VAL_ 277 SteerAngEPASStatus 3 "Reserved" 2 "Signal is implausible" 1 "Reserved " 0 "Signal is correct" ;
VAL_ 370 RCrankEnableStatus 3 "Signal not available" 2 "Value implausible." 1 "Reserved" 0 "Value is correct" ;
VAL_ 370 RCrankEnable 1 "Disable" 0 "Enable" ;
VAL_ 370 BrkLightSig2Status 3 "Signal not available" 2 "Value is implausible" 1 "Reserved for future" 0 "Value is correct" ;
VAL_ 370 BrkLightSig2 3 "Reserved for future use

" 2 "Panic Brake detected" 1 "Brake lamp ON request" 0 "No request" ;
VAL_ 370 EBdStatus 3 "Reserved for future" 2 "EBD function is switched off due to failure @EBD Warn Lamp is ON" 1 "Low Brake Fluid Detected" 0 "EBD function fully available@EBD Warning Lamp is OFF" ;
VAL_ 370 EBdActive 1 "EBD intervention  by ABS/ESP is active" 0 "No EBD intervention by ABS/ESP" ;
VAL_ 370 HHcStatus 3 "HHC function not available" 2 "HHC function switched off due to a detected failure at  ESP system" 1 "Reserved for future" 0 "HHC function is fully available" ;
VAL_ 370 HDcAvailability 1 "HDC is not available " 0 "HDC is available" ;
VAL_ 370 HHcActive 1 "HHC Intervention by ESP system is active" 0 "No HHC intervention by ESP system" ;
VAL_ 370 HDcActive 1 "HDC intervention by ESP syst is active@HDC Lamp is Blinking" 0 "No HDC intervention by ESP system@HDC Lamp is OFF" ;
VAL_ 370 HDcStatus 3 "HDC deactivation due to vehicle speed more than 60 kmph" 2 "HDC function switched off due to a detected failure at  ESP system @ HDC failure lamp is ON" 1 "HDC switched off due to a system passive request or switch" 0 "HDC function fully available @HDC failure lamp is OFF" ;
VAL_ 374 DrvModeIndctnESP2Status 3 "Signal is not available" 2 "Signal is implausible" 1 "Reserved" 0 "Information given is correct and according to specification" ;
VAL_ 374 DrvModeIndctnESP2 7 "Reserved" 6 "Reserved" 5 "Reserved" 4 "Reserved" 3 "Reserved" 2 "Rough Road Mode" 1 "Sports Mode" 0 "Normal Mode" ;
VAL_ 407 VehSpdICStatus 3 "Reserved" 2 "Value is implausibe" 1 "Reserved" 0 "Value is plausible" ;
VAL_ 448 PDcHuRearTone 15 "Reserved for future use." 14 "Reserved for future use." 13 "Reserved for future use." 12 "Reserved for future use." 11 "Reserved for future use." 10 "Reserved for future use." 9 "Reserved for future use" 8 "Reserved for future use" 7 "Reserved for future use" 6 "Reserved for future use" 5 "Reserved for future use" 4 "Reserved for future use" 3 "Reserved for future use" 2 "Tone 3" 1 "Tone 2" 0 "Tone 1" ;
VAL_ 448 PDcHuRearNoOfSen 7 "Reserved for future" 6 "Reserved for future" 5 "Reserved for future" 4 "Reserved for future" 3 "Reserved for future" 2 "4 Sensors" 1 "3 Sensors" 0 "2 Sensors" ;
VAL_ 448 PDcHuVehicleImage 7 "Vehicle Image 8" 6 "Vehicle Image 7" 5 "Vehicle Image6" 4 "Vehicle Image 5" 3 "Vehicle Image4" 2 "Vehicle Image 3" 1 "Vehicle Image 2" 0 "Vehicle Image 1" ;
VAL_ 448 PDcHuFrontActivationState 1 "Active" 0 "Inactive" ;
VAL_ 448 PDcHuLowSpeedActivation 1 "Active" 0 "InActive" ;
VAL_ 448 PDcHuFrontNoOfSen 7 "Reserved for future" 6 "Reserved for future" 5 "Reserved for future" 4 "Reserved for future" 3 "Reserved for future" 2 "4 Sensors" 1 "3 Sensors" 0 "2 Sensors" ;
VAL_ 448 PDcHuFrontTone 15 "Reserved for future use." 14 "Reserved for future use." 13 "Reserved for future use." 12 "Reserved for future use." 11 "Reserved for future use." 10 "Reserved for future use." 9 "Reserved for future use" 8 "Reserved for future use" 7 "Reserved for future use" 6 "Reserved for future use" 5 "Reserved for future use" 4 "Reserved for future use" 3 "Reserved for future use" 2 "Tone 3" 1 "Tone 2" 0 "Tone 1" ;
VAL_ 448 PDcHuFrontAudioMuteState 1 "Mute" 0 "Unmute" ;
VAL_ 448 RVcImageRotationType 1 "180 degree rotation" 0 "No rotation" ;
VAL_ 448 RVcOverlayType 1 "Dynamic Overlay" 0 "Static Overlay" ;
